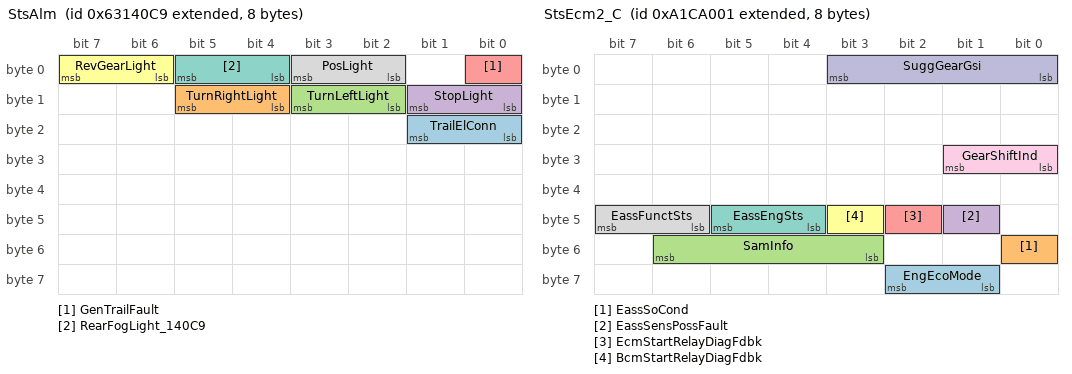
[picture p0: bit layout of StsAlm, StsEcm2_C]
BO_ 2251374793 StsAlm: 8 ALM
 SG_ TrailElConn : 16|2@1+ (1,0) [0|3] ""  PCM,NODE_40
 SG_ TurnRightLight : 12|2@1+ (1,0) [0|3] ""  PCM,NODE_40
 SG_ TurnLeftLight : 10|2@1+ (1,0) [0|3] ""  PCM,NODE_40
 SG_ StopLight : 8|2@1+ (1,0) [0|3] ""  PCM,NODE_40
 SG_ GenTrailFault : 0|1@0+ (1,0) [0|1] ""  PCM,NODE_40
 SG_ RevGearLight : 6|2@1+ (1,0) [0|3] ""  PCM,NODE_40
 SG_ RearFogLight_140C9 : 4|2@1+ (1,0) [0|3] ""  PCM,NODE_40
 SG_ PosLight : 2|2@1+ (1,0) [0|3] ""  PCM,NODE_40

BO_ 2317131777 StsEcm2_C: 8 NODE_1
 SG_ EngEcoMode : 58|2@0+ (1,0) [0|3] ""  PCM,AEBS
 SG_ EassSoCond : 48|1@0+ (1,0) [0|1] ""  PCM,AEBS
 SG_ SamInfo : 54|4@0+ (1,0) [0|15] ""  PCM,AEBS
 SG_ EassSensPossFault : 41|1@0+ (1,0) [0|1] ""  PCM,AEBS
 SG_ EcmStartRelayDiagFdbk : 42|1@0+ (1,0) [0|1] ""  PCM,AEBS
 SG_ BcmStartRelayDiagFdbk : 43|1@0+ (1,0) [0|1] ""  PCM,AEBS
 SG_ EassEngSts : 45|2@0+ (1,0) [0|3] ""  PCM,AEBS
 SG_ EassFunctSts : 47|2@0+ (1,0) [0|3] ""  PCM,AEBS
 SG_ GearShiftInd : 25|2@0+ (1,0) [0|3] ""  PCM,AEBS
 SG_ SuggGearGsi : 3|4@0+ (1,0) [0|15] ""  PCM,AEBS

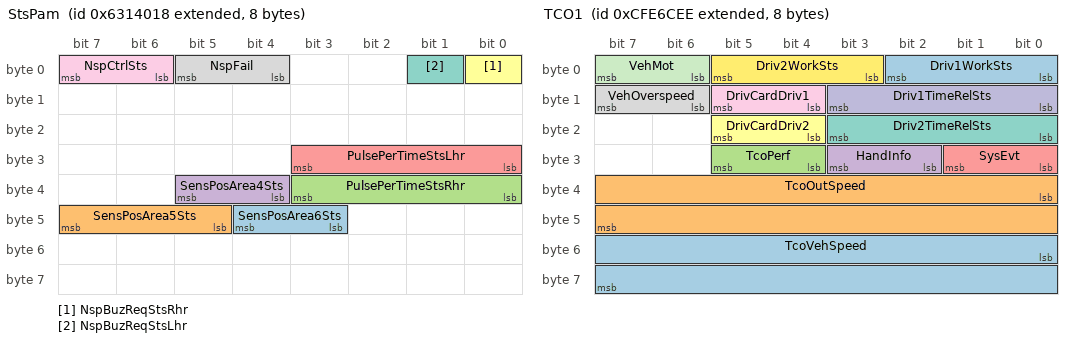
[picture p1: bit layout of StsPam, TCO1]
BO_ 2251374616 StsPam: 8 NODE_18
 SG_ SensPosArea6Sts : 44|2@0+ (1,0) [0|3] ""  PCM,NODE_40
 SG_ SensPosArea5Sts : 47|3@0+ (1,0) [0|7] ""  PCM,NODE_40
 SG_ PulsePerTimeStsRhr : 35|4@0+ (25,0) [0|375] "ms"  PCM,NODE_40
 SG_ SensPosArea4Sts : 37|2@0+ (1,0) [0|3] ""  PCM,NODE_40
 SG_ PulsePerTimeStsLhr : 27|4@0+ (25,0) [0|375] "ms"  PCM,NODE_40
 SG_ NspBuzReqStsRhr : 0|1@0+ (1,0) [0|1] ""  PCM,NODE_40
 SG_ NspBuzReqStsLhr : 1|1@0+ (1,0) [0|1] ""  PCM,NODE_40
 SG_ NspFail : 5|2@0+ (1,0) [0|3] ""  PCM,NODE_40
 SG_ NspCtrlSts : 7|2@0+ (1,0) [0|3] ""  PCM,NODE_40

BO_ 2348885874 TC1_72_27: 8 EM_PTO
 SG_ TransmMode8 : 62|2@1+ (1,0) [0|3] ""  PCM,VCM
 SG_ TransmMode7 : 60|2@1+ (1,0) [0|3] ""  PCM,VCM
 SG_ TransmMode6 : 58|2@1+ (1,0) [0|3] ""  PCM,VCM
 SG_ TransmMode5 : 56|2@1+ (1,0) [0|3] ""  PCM,VCM
 SG_ TransmShiftSelDisModeSw : 54|2@1+ (1,0) [0|3] ""  PCM,VCM
 SG_ TransmReqLaunchGear : 50|4@1+ (1,0) [0|15] ""  PCM,VCM
 SG_ TransmMode4 : 46|2@1+ (1,0) [0|3] ""  PCM,VCM
 SG_ TransmMode3 : 44|2@1+ (1,0) [0|3] ""  PCM,VCM
 SG_ TransmMode2 : 42|2@1+ (1,0) [0|3] ""  PCM,VCM
 SG_ TransmMode1 : 40|2@1+ (1,0) [0|3] ""  PCM,VCM
 SG_ DisengDiffLckReqCentRear : 36|2@1+ (1,0) [0|3] ""  PCM,VCM
 SG_ DisengDiffLckReqCentFront : 34|2@1+ (1,0) [0|3] ""  PCM,VCM
 SG_ DisengDiffLckReqCent : 32|2@1+ (1,0) [0|3] ""  PCM,VCM
 SG_ DisengDiffLckReqRa2 : 30|2@1+ (1,0) [0|3] ""  PCM,VCM
 SG_ DisengDiffLckReqRa1 : 28|2@1+ (1,0) [0|3] ""  PCM,VCM
 SG_ DisengDiffLckReqFa2 : 26|2@1+ (1,0) [0|3] ""  PCM,VCM
 SG_ DisengDiffLckReqFa1 : 24|2@1+ (1,0) [0|3] ""  PCM,VCM
 SG_ TransmReqGear : 16|8@1+ (1,-125) [-125|125] "gear value"  PCM,VCM
 SG_ ReqPcCltSlip : 8|8@1+ (0.4,0) [0|100] "%"  PCM,VCM
 SG_ TransmRevGearShiftInhReq : 6|2@1+ (1,0) [0|3] ""  PCM,VCM
 SG_ DisengDrvlReq : 4|2@1+ (1,0) [0|3] ""  PCM,VCM
 SG_ TransmTrqConvLckReq : 2|2@1+ (1,0) [0|3] ""  PCM,VCM
 SG_ TransmGearShiftInhReq : 0|2@1+ (1,0) [0|3] ""  PCM,VCM

BO_ 2566840835 TCFG: 20 AI_G5_TCM
 SG_ TransmGr9 : 144|16@1+ (0.001,0) [0|64.255] ""  PCM
 SG_ TransmGr8 : 128|16@1+ (0.001,0) [0|64.255] ""  PCM
 SG_ TransmGr7 : 112|16@1+ (0.001,0) [0|64.255] ""  PCM
 SG_ TransmGr6 : 96|16@1+ (0.001,0) [0|64.255] ""  PCM
 SG_ TransmGr5 : 80|16@1+ (0.001,0) [0|64.255] ""  PCM
 SG_ TransmGr4 : 64|16@1+ (0.001,0) [0|64.255] ""  PCM
 SG_ TransmGr3 : 48|16@1+ (0.001,0) [0|64.255] ""  PCM
 SG_ TransmGr2 : 32|16@1+ (0.001,0) [0|64.255] ""  PCM
 SG_ TransmGr1 : 16|16@1+ (0.001,0) [0|64.255] ""  PCM
 SG_ NumOfFwGrs : 8|8@1+ (1,0) [0|250] "gear value"  PCM
 SG_ NumOfRevGrs : 0|8@1+ (1,0) [0|250] "gear value"  PCM

BO_ 2566750979 TCI_03: 8 AI_G5_TCM
 SG_ TcSts : 0|3@1+ (1,0) [0|7] ""  PCM

BO_ 2566751205 TCI_E5: 8 BC2
 SG_ TcSts_FD83E5 : 0|3@1+ (1,0) [0|7] ""  PCM

BO_ 2365484270 TCO1: 8 DTCO
 SG_ TcoVehSpeed : 48|16@1+ (0.00390625,0) [0|250.996] "km/h"  PCM
 SG_ TcoOutSpeed : 32|16@1+ (0.125,0) [0|8031.875] "rpm"  PCM
 SG_ TcoPerf : 28|2@1+ (1,0) [0|3] ""  PCM
 SG_ HandInfo : 26|2@1+ (1,0) [0|3] ""  PCM
 SG_ SysEvt : 24|2@1+ (1,0) [0|3] ""  PCM
 SG_ DrivCardDriv2 : 20|2@1+ (1,0) [0|3] ""  PCM
 SG_ Driv2TimeRelSts : 16|4@1+ (1,0) [0|15] ""  PCM
 SG_ VehOverspeed : 14|2@1+ (1,0) [0|3] ""  PCM
 SG_ DrivCardDriv1 : 12|2@1+ (1,0) [0|3] ""  PCM
 SG_ Driv1TimeRelSts : 8|4@1+ (1,0) [0|15] ""  PCM
 SG_ VehMot : 6|2@1+ (1,0) [0|3] ""  PCM
 SG_ Driv2WorkSts : 3|3@1+ (1,0) [0|7] ""  PCM
 SG_ Driv1WorkSts : 0|3@1+ (1,0) [0|7] ""  PCM

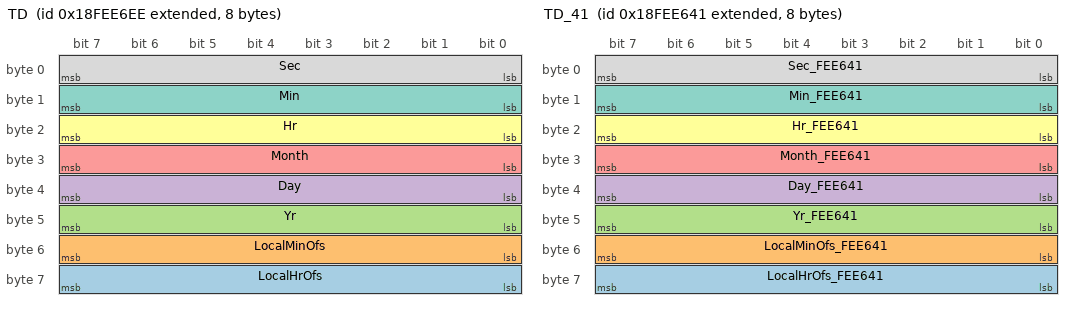
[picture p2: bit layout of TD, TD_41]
BO_ 2566842094 TD: 8 DTCO
 SG_ LocalHrOfs : 56|8@1+ (1,-125) [-125|125] "h"  PCM
 SG_ LocalMinOfs : 48|8@1+ (1,-125) [-125|125] "min"  PCM
 SG_ Yr : 40|8@1+ (1,1985) [1985|2235] "year"  PCM
 SG_ Day : 32|8@1+ (0.25,0) [0|62.5] "day"  PCM
 SG_ Month : 24|8@1+ (1,0) [0|250] "month"  PCM
 SG_ Hr : 16|8@1+ (1,0) [0|250] "h"  PCM
 SG_ Min : 8|8@1+ (1,0) [0|250] "min"  PCM
 SG_ Sec : 0|8@1+ (0.25,0) [0|62.5] "s"  PCM

BO_ 2566841921 TD_41: 8 NIS_RDR
 SG_ LocalHrOfs_FEE641 : 56|8@1+ (1,-125) [-125|125] "h"  PCM
 SG_ LocalMinOfs_FEE641 : 48|8@1+ (1,-125) [-125|125] "min"  PCM
 SG_ Yr_FEE641 : 40|8@1+ (1,1985) [1985|2235] "year"  PCM
 SG_ Day_FEE641 : 32|8@1+ (0.25,0) [0|62.5] "day"  PCM
 SG_ Month_FEE641 : 24|8@1+ (1,0) [0|250] "month"  PCM
 SG_ Hr_FEE641 : 16|8@1+ (1,0) [0|250] "h"  PCM
 SG_ Min_FEE641 : 8|8@1+ (1,0) [0|250] "min"  PCM
 SG_ Sec_FEE641 : 0|8@1+ (0.25,0) [0|62.5] "s"  PCM

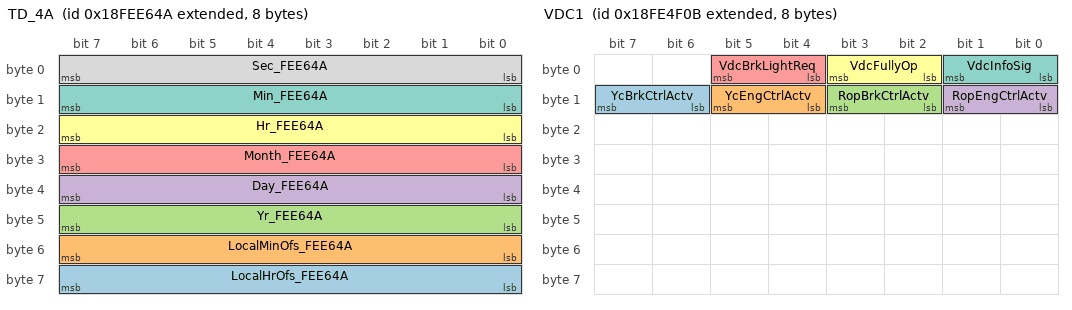
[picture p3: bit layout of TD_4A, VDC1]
BO_ 2566841930 TD_4A: 8 PCM
 SG_ LocalHrOfs_FEE64A : 56|8@1+ (1,-125) [-125|125] "h" Vector__XXX
 SG_ LocalMinOfs_FEE64A : 48|8@1+ (1,-125) [-125|125] "min" Vector__XXX
 SG_ Yr_FEE64A : 40|8@1+ (1,1985) [1985|2235] "year" Vector__XXX
 SG_ Day_FEE64A : 32|8@1+ (0.25,0) [0|62.5] "day" Vector__XXX
 SG_ Month_FEE64A : 24|8@1+ (1,0) [0|250] "month" Vector__XXX
 SG_ Hr_FEE64A : 16|8@1+ (1,0) [0|250] "h" Vector__XXX
 SG_ Min_FEE64A : 8|8@1+ (1,0) [0|250] "min" Vector__XXX
 SG_ Sec_FEE64A : 0|8@1+ (0.25,0) [0|62.5] "s" Vector__XXX

BO_ 2566764851 TPRI: 8 OptiTire
 SG_ RefTirePrs : 8|8@1+ (8,0) [0|2000] "kPa"  PCM
 SG_ TireLoc : 0|8@1+ (1,0) [0|255] ""  PCM

BO_ 2566846467 TRF1: 8 AI_G5_TCM
 SG_ TransmOilTemp1 : 32|16@1+ (0.03125,-273) [-273|1734.96875] "�C"  PCM

BO_ 2566755587 TRF2: 8 AI_G5_TCM
 SG_ TransmTrqConvOilOutTemp : 8|16@1+ (0.03125,-273) [-273|1734.96875] "�C"  PCM

BO_ 2566803211 VDC1: 8 BSM
 SG_ YcBrkCtrlActv : 14|2@1+ (1,0) [0|3] ""  PCM
 SG_ YcEngCtrlActv : 12|2@1+ (1,0) [0|3] ""  PCM
 SG_ RopBrkCtrlActv : 10|2@1+ (1,0) [0|3] ""  PCM
 SG_ RopEngCtrlActv : 8|2@1+ (1,0) [0|3] ""  PCM
 SG_ VdcBrkLightReq : 4|2@1+ (1,0) [0|3] ""  PCM
 SG_ VdcFullyOp : 2|2@1+ (1,0) [0|3] ""  PCM
 SG_ VdcInfoSig : 0|2@1+ (1,0) [0|3] ""  PCM

BO_ 2566832622 VDHR: 8 DTCO
 SG_ TripDistHr : 32|32@1+ (5,0) [0|21055406075] "m"  PCM
 SG_ TotVehDistHr : 0|32@1+ (5,0) [0|21055406075] "m"  PCM

BO_ 2566832407 VDHR_17: 8 ICC
 SG_ TotVehDistHr_FEC117 : 0|32@1+ (5,0) [0|21055406075] "m"  PCM

BO_ 2566842433 VDS_41: 8 NIS_RDR
 SG_ Altitude : 48|16@1+ (0.125,-2500) [-2500|5531.875] "m"  PCM
 SG_ Pitch : 32|16@1+ (0.0078125,-200) [-200|301.99] "deg"  PCM
 SG_ NavBasedVehSpeed : 16|16@1+ (0.00390625,0) [0|250.996] "km/h"  PCM
 SG_ CompassBear : 0|16@1+ (0.0078125,0) [0|501.99] "deg"  PCM

BO_ 2566842442 VDS_4A: 8 PCM
 SG_ Altitude_FEE84A : 48|16@1+ (0.125,-2500) [-2500|5531.875] "m" Vector__XXX
 SG_ Pitch_FEE84A : 32|16@1+ (0.0078125,-200) [-200|301.99] "deg" Vector__XXX
 SG_ NavBasedVehSpeed_FEE84A : 16|16@1+ (0.00390625,0) [0|250.996] "km/h" Vector__XXX
 SG_ CompassBear_FEE84A : 0|16@1+ (0.0078125,0) [0|501.99] "deg" Vector__XXX

BO_ 2566752586 VDS2_4A: 8 PCM
 SG_ VehRoll : 0|16@1+ (0.0078125,-200) [-200|301.99] "deg" Vector__XXX

BO_ 2566846208 VEP1_00: 8 ECM
 SG_ KeyBatPot : 48|16@1+ (0.05,0) [0|3212.75] "V"  PCM
 SG_ BatPot_PwrIn1 : 32|16@1+ (0.05,0) [0|3212.75] "V"  PCM

BO_ 2566846241 VEP1_21: 8 BCM
 SG_ KeyBatPot_FEF721 : 48|16@1+ (0.05,0) [0|3212.75] "V"  PCM
 SG_ BatPot_PwrIn1_FEF721 : 32|16@1+ (0.05,0) [0|3212.75] "V"  PCM

BO_ 2566843392 VI_00: 18 ECM
 SG_ Vin : 0|8@1+ (1,0) [0|255] "ASCII"  PCM

BO_ 2566843466 VI_4A: 18 PCM
 SG_ Vin_FEEC4A : 0|8@1+ (1,0) [0|255] "ASCII" Vector__XXX

BO_ 2566843630 VI_EE: 18 DTCO
 SG_ Vin_FEECEE : 0|8@1+ (1,0) [0|255] "ASCII"  PCM

BO_ 2566845249 VP1_41: 8 NIS_RDR
 SG_ Long_FEF341 : 32|32@1+ (1E-007,-210) [-210|211.1081215] "deg"  PCM
 SG_ Lat_FEF341 : 0|32@1+ (1E-007,-210) [-210|211.1081215] "deg"  PCM

BO_ 2566845258 VP1_4A: 8 PCM
 SG_ Long_FEF34A : 32|32@1+ (1E-007,-210) [-210|211.1081215] "deg" Vector__XXX
 SG_ Lat_FEF34A : 0|32@1+ (1E-007,-210) [-210|211.1081215] "deg" Vector__XXX

BO_ 2566845422 VP1_EE: 8 DTCO
 SG_ Long_FEF3EE : 32|32@1+ (1E-007,-210) [-210|211.1081215] "deg"  PCM
 SG_ Lat_FEF3EE : 0|32@1+ (1E-007,-210) [-210|211.1081215] "deg"  PCM

BO_ 2566649418 VP2_4A: 8 PCM
 SG_ TimeDilutionOfPrec : 32|8@1+ (0.1,0) [0|25] "" Vector__XXX
 SG_ PosDilutionOfPrec : 24|8@1+ (0.1,0) [0|25] "" Vector__XXX
 SG_ VertDilutionOfPrec : 16|8@1+ (0.1,0) [0|25] "" Vector__XXX
 SG_ HorDilutionOfPrec : 8|8@1+ (0.1,0) [0|25] "" Vector__XXX
 SG_ TotNumOfSatsInView : 0|8@1+ (1,0) [0|250] "count" Vector__XXX

BO_ 2566842606 VDS_EE: 8 DTCO
 SG_ Altitude_FEE8EE : 48|16@1+ (0.125,-2500) [-2500|5531.875] "m"  PCM
 SG_ NavBasedVehSpeed_FEE8EE : 16|16@1+ (0.00390625,0) [0|250.996] "km/h"  PCM
 SG_ CompassBear_FEE8EE : 0|16@1+ (0.0078125,0) [0|501.99] "deg"  PCM

BO_ 2348875082 PB_DC_7_4A: 8 PCM
 SG_ StopTime : 32|32@1+ (1,0) [0|65000000] "ms"  NODE_FD
 SG_ PTOTime : 0|32@1+ (1,0) [0|65000000] "ms"  NODE_FD

BO_ 2348874826 PB_DC_6_4A: 8 PCM
 SG_ DrivingTime : 32|32@1+ (1,0) [0|65000000] "ms"  RADAR_ACC
 SG_ RegenerationTime : 0|32@1+ (1,0) [0|65000000] "ms"  RADAR_ACC

BO_ 2348874570 PB_DC_5_4A: 8 PCM
 SG_ RegenerationDistance : 18|18@1+ (5,0) [0|1310000] "m"  NODE_FB
 SG_ EcoSwitchDistance : 0|18@1+ (5,0) [0|1310000] "m"  NODE_FB

BO_ 2348874314 PB_DC_4_4A: 8 PCM
 SG_ EcoSwitchTime : 24|32@1+ (1,0) [0|65000000] "ms"  TesterMh
 SG_ RecovEnergySumAbs : 0|24@1+ (0.1,0) [0|1644953.5] "kWh"  TesterMh

BO_ 2348875594 PB_DC_3_4A: 8 PCM
 SG_ TracEnergyDrivingSumAbs : 40|24@1+ (0.1,0) [0|1644953.5] "kWh" Vector__XXX
 SG_ EnergyConsPTOSumAbs : 16|24@1+ (0.1,0) [0|1644953.5] "kWh" Vector__XXX
 SG_ EnergyConsAvg : 0|16@1+ (0.001953125,0) [0|125.498046875] "km/kWh" Vector__XXX

BO_ 2348871498 PB_DC_2_4A: 8 PCM
 SG_ BatTempAvg : 40|8@1+ (1,-40) [-40|215] "�C"  NODE_EF
 SG_ AmbTempMax : 24|16@1+ (0.03125,-273) [-273|1734.96875] "�C"  NODE_EF
 SG_ AmbTempAvg : 8|16@1+ (0.03125,-273) [-273|1734.96875] "�C"  NODE_EF
 SG_ BatTempMax : 0|8@1+ (1,-40) [-40|210] "�C"  NODE_EF

BO_ 2348871242 PB_DC_1_4A: 8 PCM
 SG_ StopNumbersOccurrences : 34|10@1+ (1,0) [0|1023] ""  DTCO
 SG_ DrivingDistance : 16|18@1+ (5,0) [0|1310000] "m"  DTCO
 SG_ WhBasedVehSpeedAvg : 0|16@1+ (0.00390625,0) [0|250.996] "km/h"  DTCO

BO_ 2561142090 DSE_DRIVER_STOP: 8 PCM
 SG_ Driver_Stop : 0|2@1+ (1,0) [0|2] ""  NODE_ED

BO_ 2561141834 DSE_FUEL_CONSP: 8 PCM
 SG_ FuelConsumptionEstimatedDiesel : 20|10@1+ (0.1,-1) [-1|101.3] "L/100km"  MCDS
 SG_ FuelConsumptionGas : 10|10@1+ (0.1,-1) [-1|101.3] "Kg/100km"  MCDS
 SG_ FuelConsumptionDiesel : 0|10@1+ (0.1,-1) [-1|101.3] "L/100km"  MCDS

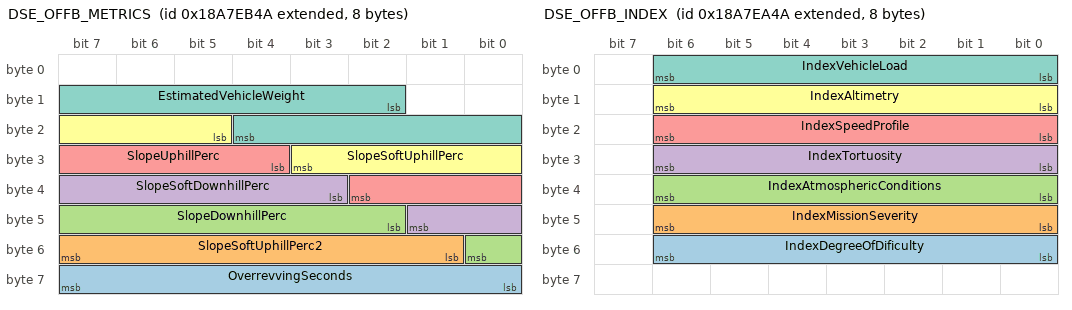
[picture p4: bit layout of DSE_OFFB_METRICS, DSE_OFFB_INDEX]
BO_ 2561141578 DSE_OFFB_METRICS: 8 PCM
 SG_ OverrevvingSeconds : 56|8@1+ (1,-1) [-1|254] "s"  NODE_EB
 SG_ SlopeSoftUphillPerc2 : 49|7@1+ (1,-1) [-1|126] "Index"  NODE_EB
 SG_ SlopeDownhillPerc : 42|7@1+ (1,-1) [-1|126] "Index"  NODE_EB
 SG_ SlopeSoftDownhillPerc : 35|7@1+ (1,-1) [-1|126] "Index"  NODE_EB
 SG_ SlopeUphillPerc : 28|7@1+ (1,-1) [-1|126] "Index"  NODE_EB
 SG_ SlopeSoftUphillPerc : 21|7@1+ (1,-1) [-1|126] "Index"  NODE_EB
 SG_ EstimatedVehicleWeight : 10|11@1+ (50,-1) [-1|102349] "kg"  NODE_EB

BO_ 2561141322 DSE_OFFB_INDEX: 8 PCM
 SG_ IndexDegreeOfDificulty : 48|7@1+ (1,-1) [-1|126] "Index"  MCSL
 SG_ IndexMissionSeverity : 40|7@1+ (1,-1) [-1|126] "Index"  MCSL
 SG_ IndexAtmosphericConditions : 32|7@1+ (1,-1) [-1|126] "Index"  MCSL
 SG_ IndexTortuosity : 24|7@1+ (1,-1) [-1|126] "Index"  MCSL
 SG_ IndexSpeedProfile : 16|7@1+ (1,-1) [-1|126] "Index"  MCSL
 SG_ IndexAltimetry : 8|7@1+ (1,-1) [-1|126] "Index"  MCSL
 SG_ IndexVehicleLoad : 0|7@1+ (1,-1) [-1|126] "Index"  MCSL

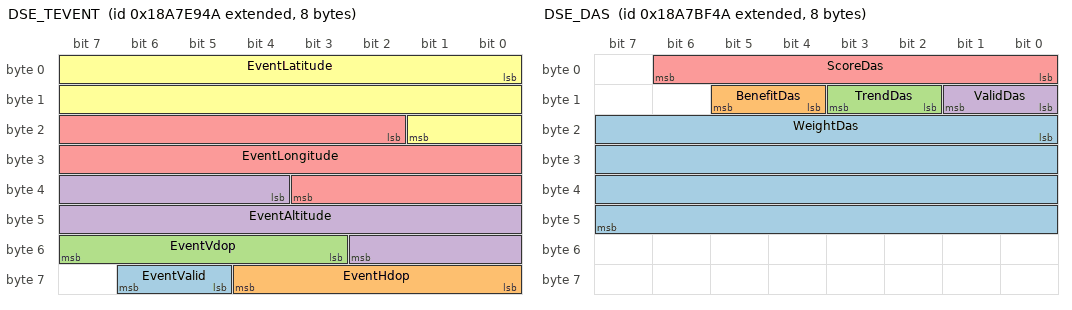
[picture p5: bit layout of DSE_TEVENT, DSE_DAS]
BO_ 2561141066 DSE_TEVENT: 8 PCM
 SG_ EventValid : 61|2@1+ (1,0) [0|3] ""  Mirror
 SG_ EventHdop : 56|5@1+ (1,0) [0|25] ""  Mirror
 SG_ EventVdop : 51|5@1+ (1,0) [0|25] ""  Mirror
 SG_ EventAltitude : 36|15@1+ (0.2,-500) [-500|6053.4] ""  Mirror
 SG_ EventLongitude : 18|18@1+ (0.0015,0) [-196.608|196.6065] ""  Mirror
 SG_ EventLatitude : 0|18@1+ (0.001,0) [-131.072|131.071] ""  Mirror

BO_ 2561140810 DSE_EVAL: 8 PCM
 SG_ EvaluatedSamplesTrip : 32|32@1+ (1,-1) [-1|4294967294] ""  NODE_E8
 SG_ EvaluatedMetersTrip : 0|32@1+ (1,-1) [-1|4294967294] "m"  NODE_E8

BO_ 2561140554 DSE_DAS_DBG: 8 PCM
 SG_ EventDas : 16|2@1+ (1,0) [0|3] ""  NODE_E7
 SG_ EvaluatedSamplesDas : 0|16@1+ (1,-1) [-1|65534] ""  NODE_E7

BO_ 2561130314 DSE_DAS: 8 PCM
 SG_ WeightDas : 16|32@1+ (1,-1) [-1|4294967294] ""  NODE_BF
 SG_ BenefitDas : 12|2@1+ (1,0) [0|0] ""  NODE_BF
 SG_ TrendDas : 10|2@1+ (1,-1) [-1|2] ""  NODE_BF
 SG_ ValidDas : 8|2@1+ (1,0) [0|0] ""  NODE_BF
 SG_ ScoreDas : 0|7@1+ (1,-1) [-1|126] "Index"  NODE_BF

BO_ 2561132874 DSE_HRBK_DBG: 8 PCM
 SG_ MaxDecelerationHarshBraking : 18|6@1+ (1,0) [0|63] "kmh/s"  ALM
 SG_ EventHarshBraking : 16|2@1+ (1,0) [0|3] ""  ALM
 SG_ EvaluatedMetersHarshBraking : 0|16@1+ (1,-1) [-1|65534] "m"  ALM

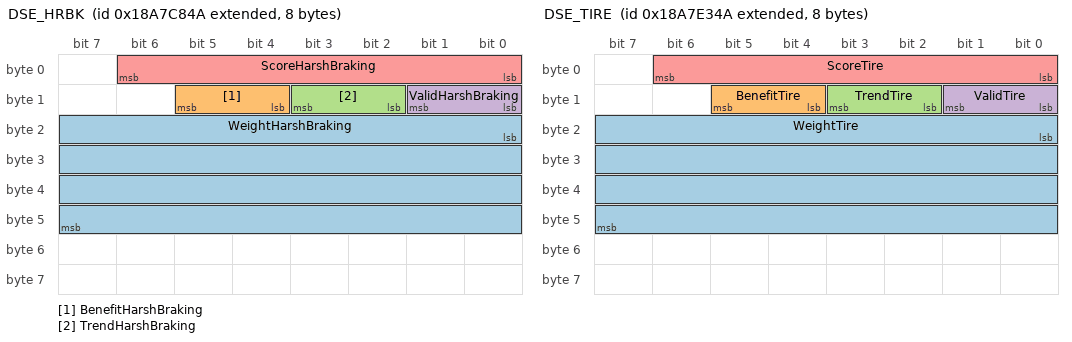
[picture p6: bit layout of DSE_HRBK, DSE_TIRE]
BO_ 2561132618 DSE_HRBK: 8 PCM
 SG_ WeightHarshBraking : 16|32@1+ (1,-1) [-1|4294967294] ""  NODE_C8
 SG_ BenefitHarshBraking : 12|2@1+ (1,0) [0|0] ""  NODE_C8
 SG_ TrendHarshBraking : 10|2@1+ (1,-1) [-1|2] ""  NODE_C8
 SG_ ValidHarshBraking : 8|2@1+ (1,0) [0|0] ""  NODE_C8
 SG_ ScoreHarshBraking : 0|7@1+ (1,-1) [-1|126] "Index"  NODE_C8

BO_ 2561139786 DSE_TIRE_DBG: 8 PCM
 SG_ EventTireSaving : 16|2@1+ (1,-1) [-1|2] ""  SAS
 SG_ EvaluatedSamplesTire : 0|16@1+ (1,-1) [-1|65534] ""  SAS

BO_ 2561139530 DSE_TIRE: 8 PCM
 SG_ WeightTire : 16|32@1+ (1,-1) [-1|4294967294] ""  NODE_E3
 SG_ BenefitTire : 12|2@1+ (1,0) [0|0] ""  NODE_E3
 SG_ TrendTire : 10|2@1+ (1,-1) [-1|2] ""  NODE_E3
 SG_ ValidTire : 8|2@1+ (1,0) [0|0] ""  NODE_E3
 SG_ ScoreTire : 0|7@1+ (1,-1) [-1|126] "Index"  NODE_E3

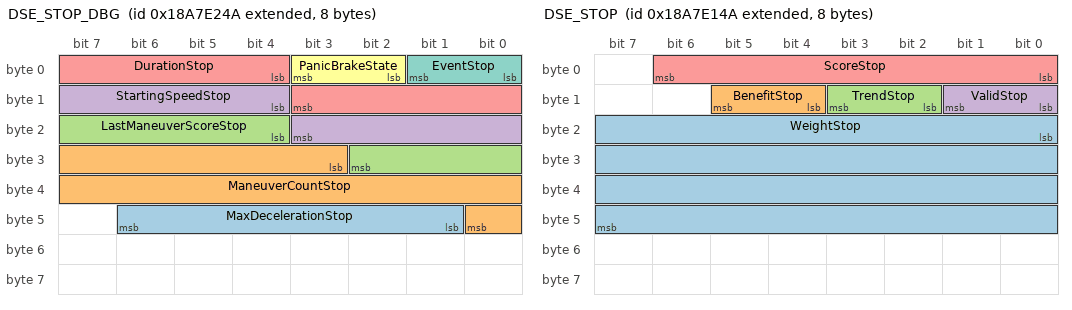
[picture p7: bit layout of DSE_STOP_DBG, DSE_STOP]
BO_ 2561139274 DSE_STOP_DBG: 8 PCM
 SG_ MaxDecelerationStop : 41|6@1+ (1,0) [0|63] "kmh/s"  NODE_E2
 SG_ ManeuverCountStop : 27|14@1+ (1,-1) [-1|16382] "Count"  NODE_E2
 SG_ LastManeuverScoreStop : 20|7@1+ (1,-1) [-1|126] "Index"  NODE_E2
 SG_ StartingSpeedStop : 12|8@1+ (0.5,0) [0|127.5] "km/h"  NODE_E2
 SG_ DurationStop : 4|8@1+ (1,-1) [-1|254] "s"  NODE_E2
 SG_ PanicBrakeState : 2|2@1+ (1,0) [0|3] ""  NODE_E2
 SG_ EventStop : 0|2@1+ (1,0) [0|3] ""  NODE_E2

BO_ 2561139018 DSE_STOP: 8 PCM
 SG_ WeightStop : 16|32@1+ (1,-1) [-1|4294967294] ""  NODE_E1
 SG_ BenefitStop : 12|2@1+ (1,0) [0|0] ""  NODE_E1
 SG_ TrendStop : 10|2@1+ (1,-1) [-1|2] ""  NODE_E1
 SG_ ValidStop : 8|2@1+ (1,0) [0|0] ""  NODE_E1
 SG_ ScoreStop : 0|7@1+ (1,-1) [-1|126] "Index"  NODE_E1

BO_ 2561138762 DSE_STCNT_DBG: 8 PCM
 SG_ EventStabilityControl : 16|2@1+ (1,0) [0|3] ""  NODE_E0
 SG_ EvaluatedMetersStabilityControl : 0|16@1+ (1,-1) [-1|65534] "m"  NODE_E0

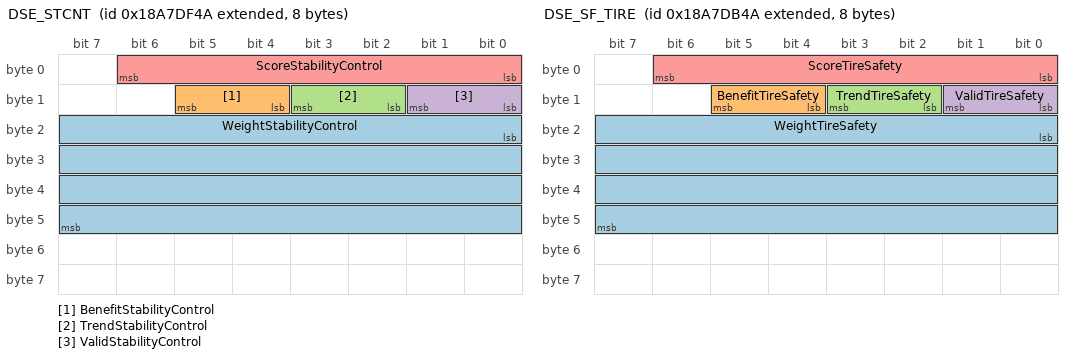
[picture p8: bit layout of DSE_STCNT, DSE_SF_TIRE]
BO_ 2561138506 DSE_STCNT: 8 PCM
 SG_ WeightStabilityControl : 16|32@1+ (1,-1) [-1|4294967294] ""  NODE_DF
 SG_ BenefitStabilityControl : 12|2@1+ (1,0) [0|0] ""  NODE_DF
 SG_ TrendStabilityControl : 10|2@1+ (1,-1) [-1|2] ""  NODE_DF
 SG_ ValidStabilityControl : 8|2@1+ (1,0) [0|0] ""  NODE_DF
 SG_ ScoreStabilityControl : 0|7@1+ (1,-1) [-1|126] "Index"  NODE_DF

BO_ 2561138250 DSE_STATUS: 8 PCM
 SG_ TripEndReason : 8|3@1+ (1,0) [0|7] ""  NODE_DE
 SG_ TripActive : 4|2@1+ (1,0) [0|0] ""  NODE_DE
 SG_ TripEnded_A7DE4A : 2|2@1+ (1,0) [0|0] ""  NODE_DE
 SG_ TripStarted_A7DE4A : 0|2@1+ (1,0) [0|0] ""  NODE_DE

BO_ 2561137994 DSE_START: 8 PCM
 SG_ TimeStampTripStart : 32|32@1+ (1,946684800) [946684800|5241652095] "Count"  NODE_DD
 SG_ OdometerTripStart : 0|32@1+ (5,-1) [-1|21474836474] "m"  NODE_DD

BO_ 2561137738 DSE_SF_TIRE_DBG: 8 PCM
 SG_ EventTireSafety : 16|2@1+ (1,0) [0|3] ""  NODE_DC
 SG_ EvaluatedMetersTireSafety : 0|16@1+ (1,-1) [-1|65534] "m"  NODE_DC

BO_ 2561137482 DSE_SF_TIRE: 8 PCM
 SG_ WeightTireSafety : 16|32@1+ (1,-1) [-1|4294967294] ""  NODE_DB
 SG_ BenefitTireSafety : 12|2@1+ (1,0) [0|0] ""  NODE_DB
 SG_ TrendTireSafety : 10|2@1+ (1,-1) [-1|2] ""  NODE_DB
 SG_ ValidTireSafety : 8|2@1+ (1,0) [0|0] ""  NODE_DB
 SG_ ScoreTireSafety : 0|7@1+ (1,-1) [-1|126] "Index"  NODE_DB

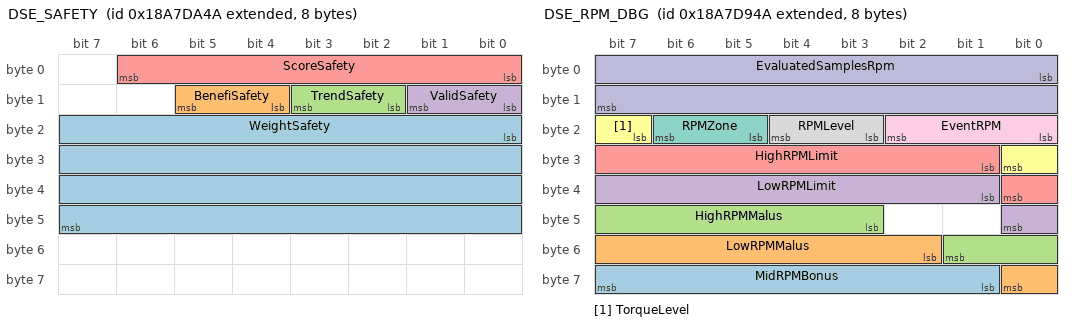
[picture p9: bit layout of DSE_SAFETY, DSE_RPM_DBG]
BO_ 2561137226 DSE_SAFETY: 8 PCM
 SG_ WeightSafety : 16|32@1+ (1,-1) [-1|4294967294] ""  NODE_DA
 SG_ BenefiSafety : 12|2@1+ (1,0) [0|0] ""  NODE_DA
 SG_ TrendSafety : 10|2@1+ (1,-1) [-1|2] ""  NODE_DA
 SG_ ValidSafety : 8|2@1+ (1,0) [0|0] ""  NODE_DA
 SG_ ScoreSafety : 0|7@1+ (1,-1) [-1|126] "Index"  NODE_DA

BO_ 2561136970 DSE_RPM_DBG: 8 PCM
 SG_ MidRPMBonus : 57|7@1+ (1,-1) [-1|126] "Index"  NODE_D9
 SG_ LowRPMMalus : 50|7@1+ (1,-126) [-126|1] "Index"  NODE_D9
 SG_ HighRPMMalus : 43|7@1+ (1,-126) [-126|1] "Index"  NODE_D9
 SG_ LowRPMLimit : 33|8@1+ (10,0) [0|2550] "rpm"  NODE_D9
 SG_ HighRPMLimit : 25|8@1+ (10,1000) [1000|3550] "rpm"  NODE_D9
 SG_ TorqueLevel : 23|2@1+ (1,0) [0|3] ""  NODE_D9
 SG_ RPMZone : 21|2@1+ (1,0) [0|3] ""  NODE_D9
 SG_ RPMLevel : 19|2@1+ (1,0) [0|3] ""  NODE_D9
 SG_ EventRPM : 16|3@1+ (1,0) [0|7] ""  NODE_D9
 SG_ EvaluatedSamplesRpm : 0|16@1+ (1,-1) [-1|65534] ""  NODE_D9

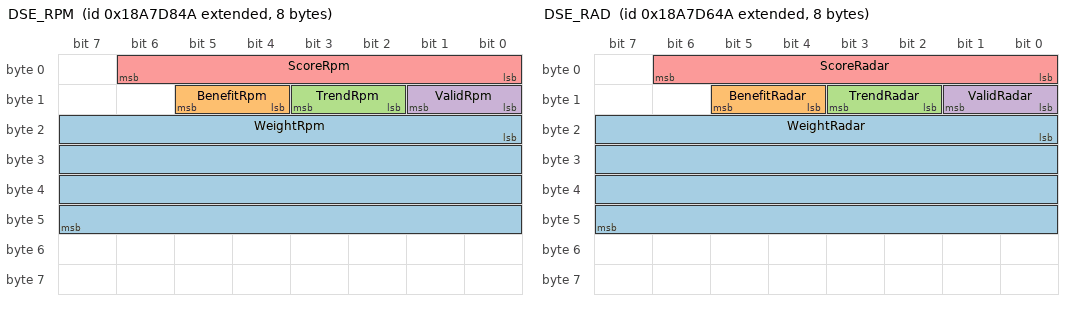
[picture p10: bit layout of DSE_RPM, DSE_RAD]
BO_ 2561136714 DSE_RPM: 8 PCM
 SG_ WeightRpm : 16|32@1+ (1,-1) [-1|4294967294] ""  NODE_D8
 SG_ BenefitRpm : 12|2@1+ (1,0) [0|0] ""  NODE_D8
 SG_ TrendRpm : 10|2@1+ (1,-1) [-1|2] ""  NODE_D8
 SG_ ValidRpm : 8|2@1+ (1,0) [0|0] ""  NODE_D8
 SG_ ScoreRpm : 0|7@1+ (1,-1) [-1|126] "Index"  NODE_D8

BO_ 2561136458 DSE_RAD_DBG: 8 PCM
 SG_ EventRadar : 16|2@1+ (1,0) [0|3] ""  NODE_D7
 SG_ EvaluatedSamplesRadar : 0|16@1+ (1,-1) [-1|65534] ""  NODE_D7

BO_ 2561136202 DSE_RAD: 8 PCM
 SG_ WeightRadar : 16|32@1+ (1,-1) [-1|4294967294] ""  NODE_D6
 SG_ BenefitRadar : 12|2@1+ (1,0) [0|0] ""  NODE_D6
 SG_ TrendRadar : 10|2@1+ (1,-1) [-1|2] ""  NODE_D6
 SG_ ValidRadar : 8|2@1+ (1,0) [0|0] ""  NODE_D6
 SG_ ScoreRadar : 0|7@1+ (1,-1) [-1|126] "Index"  NODE_D6

BO_ 2561135946 DSE_PECC_DBG: 8 PCM
 SG_ EventPecc : 16|2@1+ (1,0) [0|3] ""  NODE_D5
 SG_ EvaluatedSamplesPecc : 0|16@1+ (1,-1) [-1|65534] ""  NODE_D5

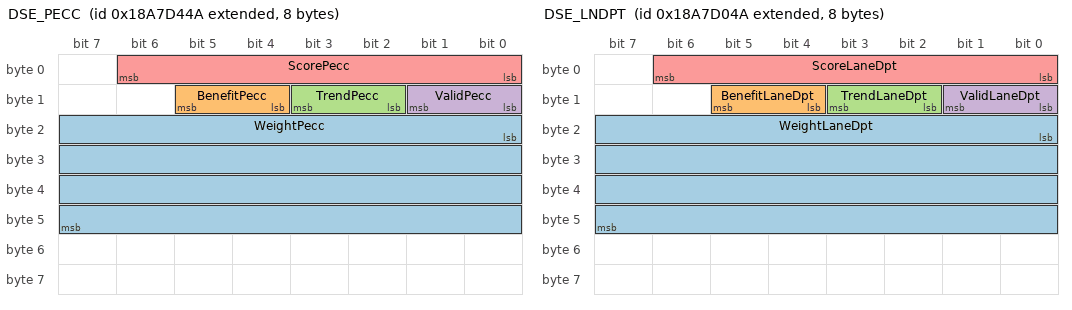
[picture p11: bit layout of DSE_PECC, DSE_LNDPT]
BO_ 2561135690 DSE_PECC: 8 PCM
 SG_ WeightPecc : 16|32@1+ (1,-1) [-1|4294967294] ""  NODE_D4
 SG_ BenefitPecc : 12|2@1+ (1,0) [0|0] ""  NODE_D4
 SG_ TrendPecc : 10|2@1+ (1,-1) [-1|2] ""  NODE_D4
 SG_ ValidPecc : 8|2@1+ (1,0) [0|0] ""  NODE_D4
 SG_ ScorePecc : 0|7@1+ (1,-1) [-1|126] "Index"  NODE_D4

BO_ 2561134922 DSE_LNDPT_DBG: 8 PCM
 SG_ EventLaneDpt : 16|2@1+ (1,0) [0|3] ""  NODE_D1
 SG_ EvaluatedSamplesLaneDpt : 0|16@1+ (1,-1) [-1|65534] ""  NODE_D1

BO_ 2561134666 DSE_LNDPT: 8 PCM
 SG_ WeightLaneDpt : 16|32@1+ (1,-1) [-1|4294967294] ""  NODE_D0
 SG_ BenefitLaneDpt : 12|2@1+ (1,0) [0|0] ""  NODE_D0
 SG_ TrendLaneDpt : 10|2@1+ (1,-1) [-1|2] ""  NODE_D0
 SG_ ValidLaneDpt : 8|2@1+ (1,0) [0|0] ""  NODE_D0
 SG_ ScoreLaneDpt : 0|7@1+ (1,-1) [-1|126] "Index"  NODE_D0

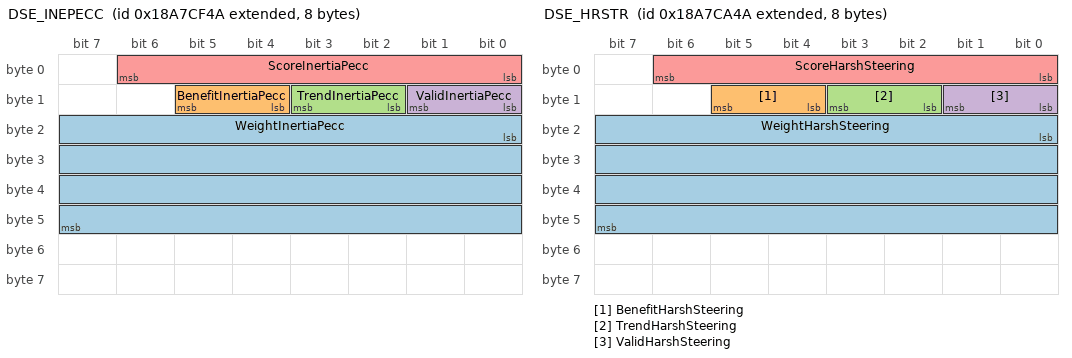
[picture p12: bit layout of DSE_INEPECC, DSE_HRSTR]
BO_ 2561134410 DSE_INEPECC: 8 PCM
 SG_ WeightInertiaPecc : 16|32@1+ (1,-1) [-1|4294967294] ""  NODE_CF
 SG_ BenefitInertiaPecc : 12|2@1+ (1,0) [0|0] ""  NODE_CF
 SG_ TrendInertiaPecc : 10|2@1+ (1,-1) [-1|2] ""  NODE_CF
 SG_ ValidInertiaPecc : 8|2@1+ (1,0) [0|0] ""  NODE_CF
 SG_ ScoreInertiaPecc : 0|7@1+ (1,-1) [-1|126] "Index"  NODE_CF

BO_ 2561133386 DSE_HRSTR_DBG: 8 PCM
 SG_ EventHarshSteering : 16|2@1+ (1,0) [0|3] ""  NODE_CB
 SG_ EvaluatedMetersHarshSteering : 0|16@1+ (1,-1) [-1|65534] "m"  NODE_CB

BO_ 2561133130 DSE_HRSTR: 8 PCM
 SG_ WeightHarshSteering : 16|32@1+ (1,-1) [-1|4294967294] ""  NODE_CA
 SG_ BenefitHarshSteering : 12|2@1+ (1,0) [0|0] ""  NODE_CA
 SG_ TrendHarshSteering : 10|2@1+ (1,-1) [-1|2] ""  NODE_CA
 SG_ ValidHarshSteering : 8|2@1+ (1,0) [0|0] ""  NODE_CA
 SG_ ScoreHarshSteering : 0|7@1+ (1,-1) [-1|126] "Index"  NODE_CA

BO_ 2561132362 DSE_HNBK_DBG: 8 PCM
 SG_ EventHandBrake : 16|2@1+ (1,0) [0|3] ""  NODE_C7
 SG_ NumEventsHandBrake : 0|16@1+ (1,-1) [-1|65534] ""  NODE_C7

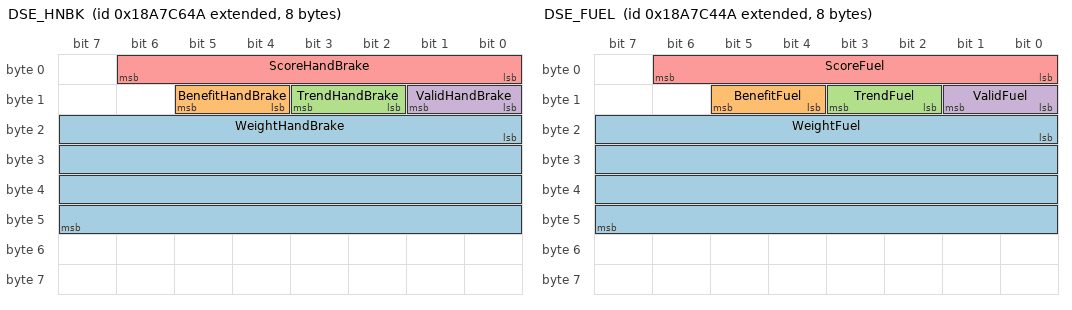
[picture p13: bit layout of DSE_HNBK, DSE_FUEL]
BO_ 2561132106 DSE_HNBK: 8 PCM
 SG_ WeightHandBrake : 16|32@1+ (1,-1) [-1|4294967294] ""  NODE_C6
 SG_ BenefitHandBrake : 12|2@1+ (1,0) [0|0] ""  NODE_C6
 SG_ TrendHandBrake : 10|2@1+ (1,-1) [-1|2] ""  NODE_C6
 SG_ ValidHandBrake : 8|2@1+ (1,0) [0|0] ""  NODE_C6
 SG_ ScoreHandBrake : 0|7@1+ (1,-1) [-1|126] "Index"  NODE_C6

BO_ 2561131594 DSE_FUEL: 8 PCM
 SG_ WeightFuel : 16|32@1+ (1,-1) [-1|4294967294] ""  NODE_C4
 SG_ BenefitFuel : 12|2@1+ (1,0) [0|0] ""  NODE_C4
 SG_ TrendFuel : 10|2@1+ (1,-1) [-1|2] ""  NODE_C4
 SG_ ValidFuel : 8|2@1+ (1,0) [0|0] ""  NODE_C4
 SG_ ScoreFuel : 0|7@1+ (1,-1) [-1|126] "Index"  NODE_C4

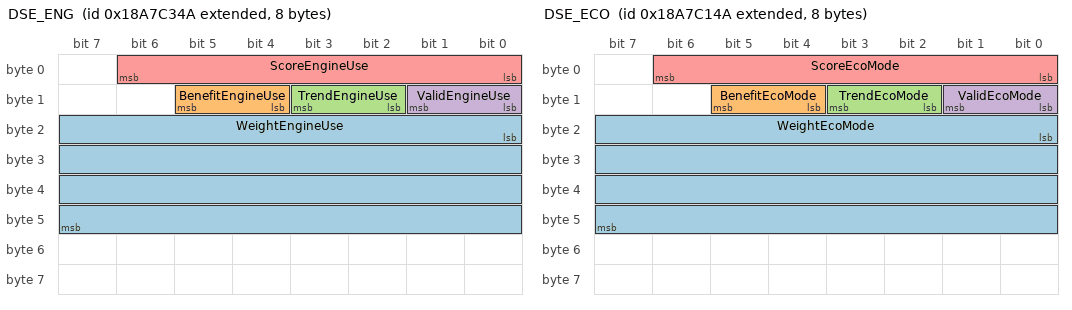
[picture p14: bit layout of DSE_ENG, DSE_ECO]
BO_ 2561131338 DSE_ENG: 8 PCM
 SG_ WeightEngineUse : 16|32@1+ (1,-1) [-1|4294967294] ""  NODE_C3
 SG_ BenefitEngineUse : 12|2@1+ (1,0) [0|0] ""  NODE_C3
 SG_ TrendEngineUse : 10|2@1+ (1,-1) [-1|2] ""  NODE_C3
 SG_ ValidEngineUse : 8|2@1+ (1,0) [0|0] ""  NODE_C3
 SG_ ScoreEngineUse : 0|7@1+ (1,-1) [-1|126] "Index"  NODE_C3

BO_ 2561131082 DSE_ECO_DBG: 8 PCM
 SG_ EvaluatedSamplesEcoMode : 0|16@1+ (1,-1) [-1|65534] ""  NODE_C2

BO_ 2561130826 DSE_ECO: 8 PCM
 SG_ WeightEcoMode : 16|32@1+ (1,-1) [-1|4294967294] ""  NODE_C1
 SG_ BenefitEcoMode : 12|2@1+ (1,0) [0|0] ""  NODE_C1
 SG_ TrendEcoMode : 10|2@1+ (1,-1) [-1|2] ""  NODE_C1
 SG_ ValidEcoMode : 8|2@1+ (1,0) [0|0] ""  NODE_C1
 SG_ ScoreEcoMode : 0|7@1+ (1,-1) [-1|126] "Index"  NODE_C1

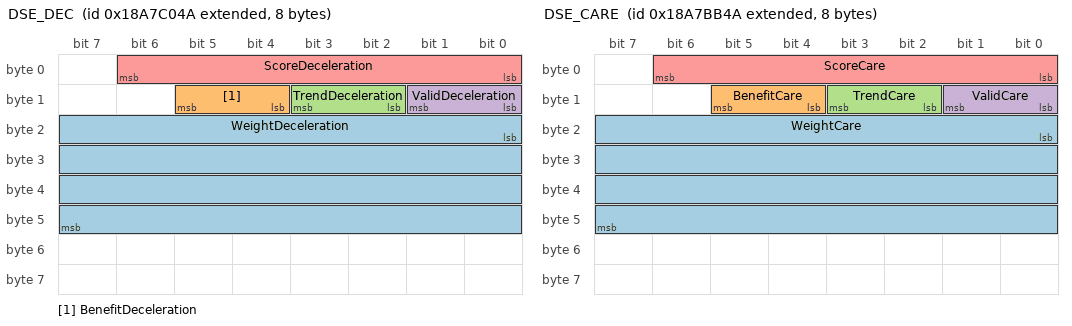
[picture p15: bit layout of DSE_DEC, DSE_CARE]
BO_ 2561130570 DSE_DEC: 8 PCM
 SG_ WeightDeceleration : 16|32@1+ (1,-1) [-1|4294967294] ""  NODE_C0
 SG_ BenefitDeceleration : 12|2@1+ (1,0) [0|0] ""  NODE_C0
 SG_ TrendDeceleration : 10|2@1+ (1,-1) [-1|2] ""  NODE_C0
 SG_ ValidDeceleration : 8|2@1+ (1,0) [0|0] ""  NODE_C0
 SG_ ScoreDeceleration : 0|7@1+ (1,-1) [-1|126] "Index"  NODE_C0

BO_ 2561129802 DSE_CURNT: 8 PCM
 SG_ TimeStampCurrent : 32|32@1+ (1,946684800) [946684800|5241652095] "Date"  NODE_BD
 SG_ OdometerTripCurrent : 0|32@1+ (5,-1) [-1|21474836474] "m"  NODE_BD

BO_ 2561129290 DSE_CARE: 8 PCM
 SG_ WeightCare : 16|32@1+ (1,-1) [-1|4294967294] ""  NODE_BB
 SG_ BenefitCare : 12|2@1+ (1,0) [0|0] ""  NODE_BB
 SG_ TrendCare : 10|2@1+ (1,-1) [-1|2] ""  NODE_BB
 SG_ ValidCare : 8|2@1+ (1,0) [0|0] ""  NODE_BB
 SG_ ScoreCare : 0|7@1+ (1,-1) [-1|126] "Index"  NODE_BB

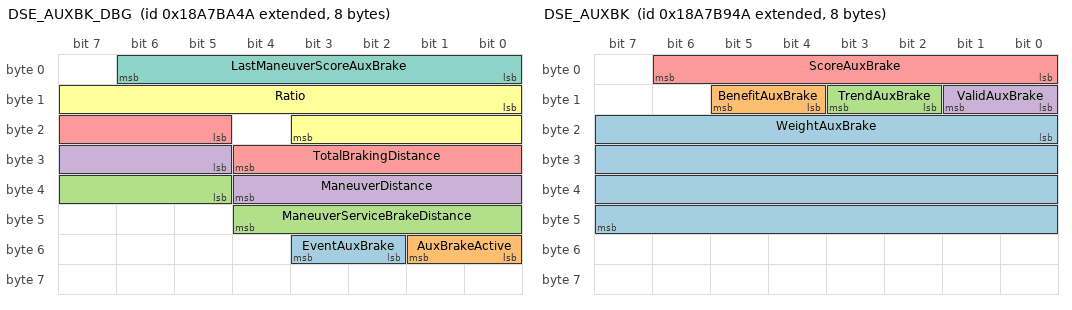
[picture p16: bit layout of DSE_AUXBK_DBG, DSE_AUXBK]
BO_ 2561129034 DSE_AUXBK_DBG: 8 PCM
 SG_ EventAuxBrake : 50|2@1+ (1,0) [0|3] ""  NODE_BA
 SG_ AuxBrakeActive : 48|2@1+ (1,0) [0|3] ""  NODE_BA
 SG_ ManeuverServiceBrakeDistance : 37|8@1+ (1,-1) [-1|254] "m"  NODE_BA
 SG_ ManeuverDistance : 29|8@1+ (1,-1) [-1|254] "m"  NODE_BA
 SG_ TotalBrakingDistance : 21|8@1+ (1,-1) [-1|254] "m"  NODE_BA
 SG_ Ratio : 8|12@1+ (0.1,-1) [-1|408.5] ""  NODE_BA
 SG_ LastManeuverScoreAuxBrake : 0|7@1+ (1,-1) [-1|126] "Index"  NODE_BA

BO_ 2561128778 DSE_AUXBK: 8 PCM
 SG_ WeightAuxBrake : 16|32@1+ (1,-1) [-1|4294967294] ""  NODE_B9
 SG_ BenefitAuxBrake : 12|2@1+ (1,0) [0|0] ""  NODE_B9
 SG_ TrendAuxBrake : 10|2@1+ (1,-1) [-1|2] ""  NODE_B9
 SG_ ValidAuxBrake : 8|2@1+ (1,0) [0|0] ""  NODE_B9
 SG_ ScoreAuxBrake : 0|7@1+ (1,-1) [-1|126] "Index"  NODE_B9

BO_ 2561128522 DSE_AIRC_DBG: 8 PCM
 SG_ EvaluatedSamplesAirC : 0|16@1+ (1,-1) [-1|65534] ""  NODE_B8

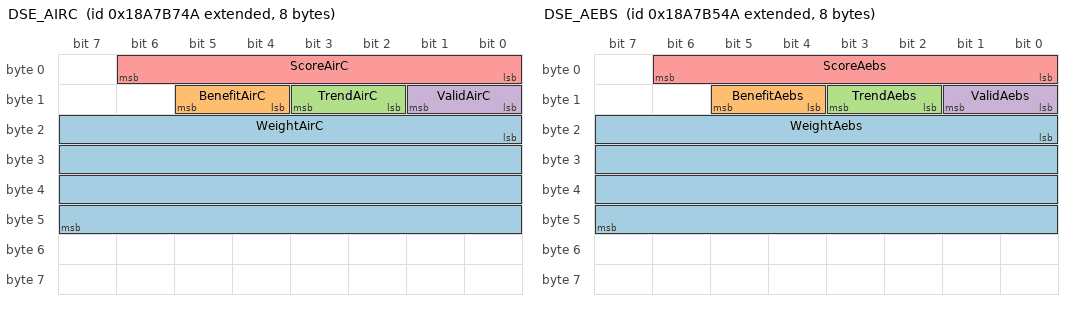
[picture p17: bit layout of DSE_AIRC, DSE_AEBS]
BO_ 2561128266 DSE_AIRC: 8 PCM
 SG_ WeightAirC : 16|32@1+ (1,-1) [-1|4294967294] ""  NODE_B7
 SG_ BenefitAirC : 12|2@1+ (1,0) [0|0] ""  NODE_B7
 SG_ TrendAirC : 10|2@1+ (1,-1) [-1|2] ""  NODE_B7
 SG_ ValidAirC : 8|2@1+ (1,0) [0|0] ""  NODE_B7
 SG_ ScoreAirC : 0|7@1+ (1,-1) [-1|126] "Index"  NODE_B7

BO_ 2561128010 DSE_AEBS_DBG: 8 PCM
 SG_ EventAebs : 16|2@1+ (1,0) [0|3] ""  NODE_B6
 SG_ EvaluatedSamplesAebs : 0|16@1+ (1,-1) [-1|65534] ""  NODE_B6

BO_ 2561126986 DSE_ACC_DBG: 8 PCM
 SG_ EventAcc : 16|2@1+ (1,0) [0|3] ""  NODE_B2
 SG_ EvaluatedSamplesAcc : 0|16@1+ (1,-1) [-1|65534] ""  NODE_B2

BO_ 2561127754 DSE_AEBS: 8 PCM
 SG_ WeightAebs : 16|32@1+ (1,-1) [-1|4294967294] ""  NODE_B5
 SG_ BenefitAebs : 12|2@1+ (1,0) [0|0] ""  NODE_B5
 SG_ TrendAebs : 10|2@1+ (1,-1) [-1|2] ""  NODE_B5
 SG_ ValidAebs : 8|2@1+ (1,0) [0|0] ""  NODE_B5
 SG_ ScoreAebs : 0|7@1+ (1,-1) [-1|126] "Index"  NODE_B5

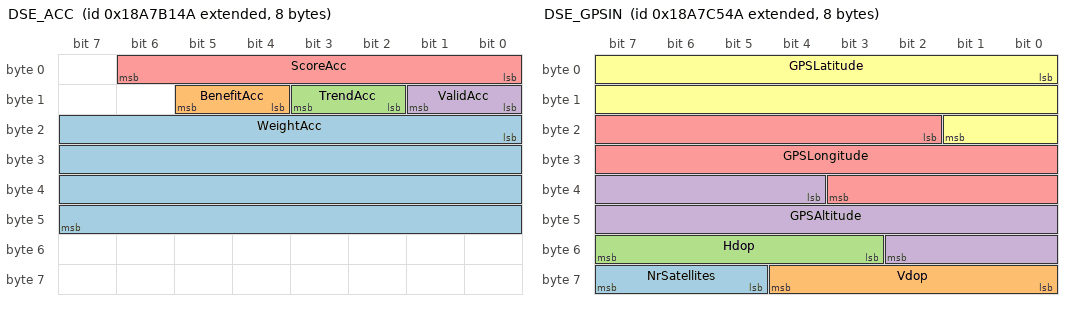
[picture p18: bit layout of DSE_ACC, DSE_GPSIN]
BO_ 2561126730 DSE_ACC: 8 PCM
 SG_ WeightAcc : 16|32@1+ (1,-1) [-1|4294967294] ""  NODE_B1
 SG_ BenefitAcc : 12|2@1+ (1,0) [0|0] ""  NODE_B1
 SG_ TrendAcc : 10|2@1+ (1,-1) [-1|2] ""  NODE_B1
 SG_ ValidAcc : 8|2@1+ (1,0) [0|0] ""  NODE_B1
 SG_ ScoreAcc : 0|7@1+ (1,-1) [-1|126] "Index"  NODE_B1

BO_ 2561129546 DSE_CMD: 8 PCM
 SG_ ResetEcoB : 2|2@1+ (1,0) [0|0] ""  NODE_BC
 SG_ ResetEcoA : 0|2@1+ (1,0) [0|0] ""  NODE_BC

BO_ 2561135434 DSE_OLDDAS: 8 PCM
 SG_ OldDasEnabled : 44|2@1- (1,0) [0|0] ""  NODE_D3
 SG_ OldDasWarning : 42|2@1+ (1,0) [0|0] ""  NODE_D3
 SG_ OldDasStop : 40|2@1+ (1,0) [0|0] ""  NODE_D3
 SG_ OldDasStatus : 32|8@1+ (1,0) [0|0] ""  NODE_D3
 SG_ OldDasPiswa : 0|32@1- (1,0) [0|0] ""  NODE_D3

BO_ 2561135178 DSE_NOTF: 8 PCM
 SG_ NotificationEnabled : 16|2@1+ (1,0) [0|3] ""  NODE_D2
 SG_ NotificationCritical : 14|2@1+ (1,0) [0|3] ""  NODE_D2
 SG_ NotificationTypeId : 8|6@1+ (1,0) [0|63] ""  NODE_D2
 SG_ NotificationTextId : 0|6@1+ (1,0) [0|63] ""  NODE_D2

BO_ 2561131850 DSE_GPSIN: 8 PCM
 SG_ NrSatellites : 61|3@1+ (1,0) [0|7] ""  NODE_C5
 SG_ Vdop : 56|5@1+ (1,0) [0|25] ""  NODE_C5
 SG_ Hdop : 51|5@1+ (1,0) [0|25] ""  NODE_C5
 SG_ GPSAltitude : 36|15@1+ (0.2,-500) [-500|6053.4] ""  NODE_C5
 SG_ GPSLongitude : 18|18@1- (0.0015,0) [-196.608|196.6065] ""  NODE_C5
 SG_ GPSLatitude : 0|18@1- (0.001,0) [-131.072|131.071] ""  NODE_C5

BO_ 2561140298 DSE_VER: 8 PCM
 SG_ VersionModel : 24|8@1+ (1,-1) [0|0] ""  NODE_E6
 SG_ VersionRevision : 16|8@1+ (1,-1) [0|0] ""  NODE_E6
 SG_ VersionMinor : 8|8@1+ (1,-1) [0|0] ""  NODE_E6
 SG_ VersionMajor : 0|8@1+ (1,-1) [0|0] ""  NODE_E6

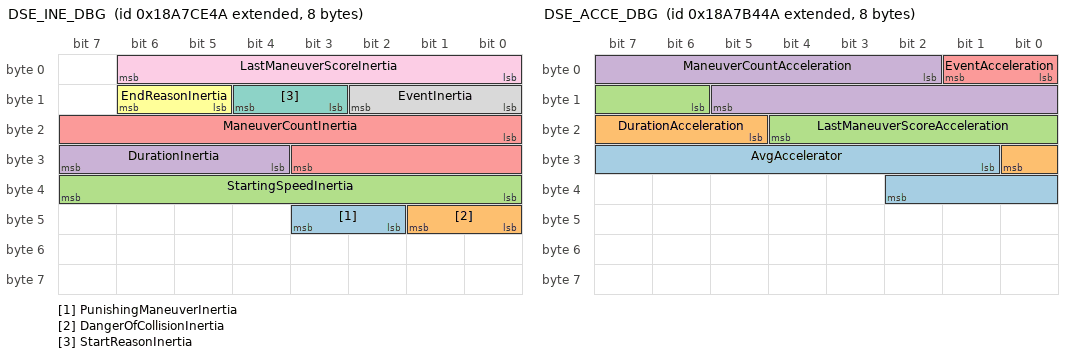
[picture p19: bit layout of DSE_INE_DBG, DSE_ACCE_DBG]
BO_ 2561134154 DSE_INE_DBG: 8 PCM
 SG_ PunishingManeuverInertia : 42|2@1+ (1,0) [0|0] ""  NODE_CE
 SG_ DangerOfCollisionInertia : 40|2@1+ (1,0) [0|0] ""  NODE_CE
 SG_ StartingSpeedInertia : 32|8@1+ (0.5,0) [0|127.5] "km/h"  NODE_CE
 SG_ DurationInertia : 28|4@1+ (1,-1) [-1|14] "s"  NODE_CE
 SG_ ManeuverCountInertia : 16|12@1+ (1,-1) [-1|4094] "Count"  NODE_CE
 SG_ EndReasonInertia : 13|2@1+ (1,0) [0|3] ""  NODE_CE
 SG_ StartReasonInertia : 11|2@1+ (1,0) [0|3] ""  NODE_CE
 SG_ EventInertia : 8|3@1+ (1,0) [0|7] ""  NODE_CE
 SG_ LastManeuverScoreInertia : 0|7@1+ (1,-1) [-1|126] "Index"  NODE_CE

BO_ 2561133898 DSE_INE: 8 PCM
 SG_ WeightInertia : 16|32@1+ (1,-1) [-1|4294967294] ""  NODE_CD
 SG_ BenefitInertia : 12|2@1+ (1,0) [0|0] ""  NODE_CD
 SG_ TrendInertia : 10|2@1+ (1,-1) [-1|2] ""  NODE_CD
 SG_ ValidInertia : 8|2@1+ (1,0) [0|0] ""  NODE_CD
 SG_ ScoreInertia : 0|7@1+ (1,-1) [-1|126] "Index"  NODE_CD

BO_ 2561127498 DSE_ACCE_DBG: 8 PCM
 SG_ AvgAccelerator : 25|10@1+ (0.1,-1) [-1|101.3] "%"  NODE_B4
 SG_ DurationAcceleration : 21|4@1+ (1,-1) [-1|14] "s"  NODE_B4
 SG_ LastManeuverScoreAcceleration : 14|7@1+ (1,-1) [-1|126] "Index"  NODE_B4
 SG_ ManeuverCountAcceleration : 2|12@1+ (1,-1) [-1|4094] "Count"  NODE_B4
 SG_ EventAcceleration : 0|2@1+ (1,0) [0|3] ""  NODE_B4

BO_ 2561127242 DSE_ACCE: 8 PCM
 SG_ WeightAcceleration : 16|32@1+ (1,-1) [-1|4294967294] ""  NODE_B3
 SG_ BenefitAcceleration : 12|2@1+ (1,0) [0|0] ""  NODE_B3
 SG_ TrendAcceleration : 10|2@1+ (1,-1) [-1|2] ""  NODE_B3
 SG_ ValidAcceleration : 8|2@1+ (1,0) [0|0] ""  NODE_B3
 SG_ ScoreAcceleration : 0|7@1+ (1,-1) [-1|126] "Index"  NODE_B3

BO_ 2566894154 PB_EVR_4A: 8 PCM
 SG_ GetChargedTime : 40|16@1+ (1,0) [0|64255] "min" Vector__XXX

BO_ 2566896970 PB_IdCrash2_4A: 8 PCM
 SG_ IdCrashDevice4 : 32|32@1+ (1,0) [0|4294967295] "" Vector__XXX
 SG_ IdCrashDevice3 : 0|32@1+ (1,0) [0|4294967295] "" Vector__XXX

BO_ 2566893898 PB_CrashInfo_4A: 8 PCM
 SG_ CrashEventType : 0|3@1+ (1,0) [0|7] "" Vector__XXX

BO_ 2566895434 PB_IdCrash_4A: 8 PCM
 SG_ IdCrashDevice2 : 32|32@1+ (1,0) [0|4294967295] "" Vector__XXX
 SG_ IdCrashDevice : 0|32@1+ (1,0) [0|4294967295] "" Vector__XXX

BO_ 2566845491 TIRE1: 8 OptiTire
 SG_ TirePrsThrsDetAx1InnLe m1 : 61|3@1+ (1,0) [0|7] ""  PCM
 SG_ TirePrsThrsDetAx1InnRi m2 : 61|3@1+ (1,0) [0|7] ""  PCM
 SG_ TirePrsThrsDetAx1OutLe m0 : 61|3@1+ (1,0) [0|7] ""  PCM
 SG_ TirePrsThrsDetAx1OutRi m3 : 61|3@1+ (1,0) [0|7] ""  PCM
 SG_ TirePrsThrsDetAx2InnLe m17 : 61|3@1+ (1,0) [0|7] ""  PCM
 SG_ TirePrsThrsDetAx2InnRi m18 : 61|3@1+ (1,0) [0|7] ""  PCM
 SG_ TirePrsThrsDetAx2OutLe m16 : 61|3@1+ (1,0) [0|7] ""  PCM
 SG_ TirePrsThrsDetAx2OutRi m19 : 61|3@1+ (1,0) [0|7] ""  PCM
 SG_ TirePrsThrsDetAx3InnLe m33 : 61|3@1+ (1,0) [0|7] ""  PCM
 SG_ TirePrsThrsDetAx3InnRi m34 : 61|3@1+ (1,0) [0|7] ""  PCM
 SG_ TirePrsThrsDetAx3OutLe m32 : 61|3@1+ (1,0) [0|7] ""  PCM
 SG_ TirePrsThrsDetAx3OutRi m35 : 61|3@1+ (1,0) [0|7] ""  PCM
 SG_ TirePrsThrsDetAx4InnLe m49 : 61|3@1+ (1,0) [0|7] ""  PCM
 SG_ TirePrsThrsDetAx4InnRi m50 : 61|3@1+ (1,0) [0|7] ""  PCM
 SG_ TirePrsThrsDetAx4OutLe m48 : 61|3@1+ (1,0) [0|7] ""  PCM
 SG_ TirePrsThrsDetAx4OutRi m51 : 61|3@1+ (1,0) [0|7] ""  PCM
 SG_ ExTirePrsSupp m0 : 38|2@1+ (1,0) [0|3] ""  PCM
 SG_ TireSensElFault m0 : 36|2@1+ (1,0) [0|3] ""  PCM
 SG_ TireSensEnaSts m0 : 32|2@1+ (1,0) [0|3] ""  PCM
 SG_ TireTempAx1InnLe m1 : 16|16@1+ (0.03125,-273) [-273|1734.96875] "�C"  PCM
 SG_ TireTempAx1InnRi m2 : 16|16@1+ (0.03125,-273) [-273|1734.96875] "�C"  PCM
 SG_ TireTempAx1OutLe m0 : 16|16@1+ (0.03125,-273) [-273|1734.96875] "�C"  PCM
 SG_ TireTempAx1OutRi m3 : 16|16@1+ (0.03125,-273) [-273|1734.96875] "�C"  PCM
 SG_ TireTempAx2InnLe m17 : 16|16@1+ (0.03125,-273) [-273|1734.96875] "�C"  PCM
 SG_ TireTempAx2InnRi m18 : 16|16@1+ (0.03125,-273) [-273|1734.96875] "�C"  PCM
 SG_ TireTempAx2OutLe m16 : 16|16@1+ (0.03125,-273) [-273|1734.96875] "�C"  PCM
 SG_ TireTempAx2OutRi m19 : 16|16@1+ (0.03125,-273) [-273|1734.96875] "�C"  PCM
 SG_ TireTempAx3InnLe m33 : 16|16@1+ (0.03125,-273) [-273|1734.96875] "�C"  PCM
 SG_ TireTempAx3InnRi m34 : 16|16@1+ (0.03125,-273) [-273|1734.96875] "�C"  PCM
 SG_ TireTempAx3OutLe m32 : 16|16@1+ (0.03125,-273) [-273|1734.96875] "�C"  PCM
 SG_ TireTempAx3OutRi m35 : 16|16@1+ (0.03125,-273) [-273|1734.96875] "�C"  PCM
 SG_ TireTempAx4InnLe m49 : 16|16@1+ (0.03125,-273) [-273|1734.96875] "�C"  PCM
 SG_ TireTempAx4InnRi m50 : 16|16@1+ (0.03125,-273) [-273|1734.96875] "�C"  PCM
 SG_ TireTempAx4OutLe m48 : 16|16@1+ (0.03125,-273) [-273|1734.96875] "�C"  PCM
 SG_ TireTempAx4OutRi m51 : 16|16@1+ (0.03125,-273) [-273|1734.96875] "�C"  PCM
 SG_ TirePrsAx1OutRi m3 : 8|8@1+ (4,0) [0|1000] "kPa"  PCM
 SG_ TirePrsAx1InnLe m1 : 8|8@1+ (4,0) [0|1000] "kPa"  PCM
 SG_ TirePrsAx1InnRi m2 : 8|8@1+ (4,0) [0|1000] "kPa"  PCM
 SG_ TirePrsAx1OutLe m0 : 8|8@1+ (4,0) [0|1000] "kPa"  PCM
 SG_ TirePrsAx2InnLe m17 : 8|8@1+ (4,0) [0|1000] "kPa"  PCM
 SG_ TirePrsAx2InnRi m18 : 8|8@1+ (4,0) [0|1000] "kPa"  PCM
 SG_ TirePrsAx2OutLe m16 : 8|8@1+ (4,0) [0|1000] "kPa"  PCM
 SG_ TirePrsAx2OutRi m19 : 8|8@1+ (4,0) [0|1000] "kPa"  PCM
 SG_ TirePrsAx3InnLe m33 : 8|8@1+ (4,0) [0|1000] "kPa"  PCM
 SG_ TirePrsAx3InnRi m34 : 8|8@1+ (4,0) [0|1000] "kPa"  PCM
 SG_ TirePrsAx3OutLe m32 : 8|8@1+ (4,0) [0|1000] "kPa"  PCM
 SG_ TirePrsAx3OutRi m35 : 8|8@1+ (4,0) [0|1000] "kPa"  PCM
 SG_ TirePrsAx4InnLe m49 : 8|8@1+ (4,0) [0|1000] "kPa"  PCM
 SG_ TirePrsAx4InnRi m50 : 8|8@1+ (4,0) [0|1000] "kPa"  PCM
 SG_ TirePrsAx4OutLe m48 : 8|8@1+ (4,0) [0|1000] "kPa"  PCM
 SG_ TirePrsAx4OutRi m51 : 8|8@1+ (4,0) [0|1000] "kPa"  PCM
 SG_ TireLoc_FEF433 M : 0|8@1+ (1,0) [0|255] ""  PCM

BO_ 2565982748 DM01_1C: 82 PCM
 SG_ SpnCm20_FECA1C : 655|1@1+ (1,0) [0|1] "" Vector__XXX

BO_ 2566845212 VP1_1C: 8 PCM
 SG_ Long_FEF31C : 32|32@1+ (1E-007,-210) [-210|211.1081215] "deg" Vector__XXX
 SG_ Lat_FEF31C : 0|32@1+ (1E-007,-210) [-210|211.1081215] "deg" Vector__XXX

CM_ SG_ 2251374793 TurnRightLight "- On Daily MY24 values are (00 Off; 01 On; 10 Error & Off; 11 Error and On)";
CM_ SG_ 2251374793 TurnLeftLight "- On Daily MY24 values are (00 Off; 01 On; 10 Error & Off; 11 Error and On)";
CM_ SG_ 2251374793 StopLight "- On Daily MY24 values are (00 Off; 01 On; 10 Error & Off; 11 Error and On)";
CM_ SG_ 2251374793 RevGearLight "- On Daily MY24 values are (00 Off; 01 On; 10 Error & Off; 11 Error and On)";
CM_ SG_ 2251374793 RearFogLight_140C9 "- On Daily MY24 values are (00 Off; 01 On; 10 Error & Off; 11 Error and On)";
CM_ SG_ 2251374793 PosLight "- On Daily MY24 values are (00 Off; 01 On; 10 Error & Off; 11 Error and On)";
CM_ SG_ 2317131777 EassSoCond "- In Fiat 07332 assigned to ColdStartLampIndication";
CM_ SG_ 2317131777 SamInfo "- Logistic Mode value available on VT from MY24";
CM_ SG_ 2317131777 SuggGearGsi "- Only with F1A and 2835.6 manual transmission";
CM_ BO_ 2251374616 "- Original Fiat name STATUS_PAM_V2";
CM_ SG_ 2348885874 TransmMode8 "- Application Counter (0 to 3)";
CM_ BO_ 2566840835 "-  2 Message Variant(s): Transm.Rates OnRequest, OnRequest
-  Multipacket message handled by SAE Transport Protocol (J1939/21, par 5.10, Multipacket Broadcast with TP.CM/BAM, TP.DT)
-  Multipacket message handled by SAE Transport Protocol (J1939/21, par 5.10, Multipacket Broadcast with TP.CM/BAM, TP.DT)";
CM_ SG_ 2566751205 TcSts_FD83E5 "- 010b Neutral, 100b Low Range, 001b High Range, 101b Shift in progress, 110b Error, 111b Not available";
CM_ BO_ 2365484270 "- FMS Trans.Rate=1s
-  SAE Trans.Rate=50ms";
CM_ SG_ 2365484270 Driv2TimeRelSts "- SAE J1939 Value Table different to ISO16844-7 definition (used by DTCO)";
CM_ SG_ 2365484270 Driv1TimeRelSts "- SAE J1939 Value Table different to ISO16844-7 definition (used by DTCO)";
CM_ BO_ 2566842094 "- SAE Trans.Rate=On Request";
CM_ SG_ 2566842094 Yr "- SAE J1939/73 Freeze Frame parameter";
CM_ SG_ 2566842094 Day "- SAE J1939/73 Freeze Frame parameter";
CM_ SG_ 2566842094 Month "- SAE J1939/73 Freeze Frame parameter";
CM_ SG_ 2566842094 Hr "- SAE J1939/73 Freeze Frame parameter";
CM_ SG_ 2566842094 Min "- SAE J1939/73 Freeze Frame parameter";
CM_ SG_ 2566842094 Sec "- SAE J1939/73 Freeze Frame parameter";
CM_ BO_ 2566841921 "- Cyclic Transmission Rate as result of PGN requests";
CM_ SG_ 2566841921 Yr_FEE641 "- GPS Time";
CM_ SG_ 2566841921 Day_FEE641 "- GPS Time";
CM_ SG_ 2566841921 Month_FEE641 "- GPS Time";
CM_ SG_ 2566841921 Hr_FEE641 "- GPS Time";
CM_ SG_ 2566841921 Min_FEE641 "- GPS Time";
CM_ SG_ 2566841921 Sec_FEE641 "- GPS Time";
CM_ SG_ 2566841930 Yr_FEE64A "- GPS Time";
CM_ SG_ 2566841930 Day_FEE64A "- GPS Time";
CM_ SG_ 2566841930 Month_FEE64A "- GPS Time";
CM_ SG_ 2566841930 Hr_FEE64A "- GPS Time";
CM_ SG_ 2566841930 Min_FEE64A "- GPS Time";
CM_ SG_ 2566841930 Sec_FEE64A "- GPS Time";
CM_ BO_ 2566764851 "- Not implemented in TPMS Sensata Step1 Stralis MY2019";
CM_ SG_ 2566803211 VdcInfoSig "- VDC lamp status";
CM_ SG_ 2566832622 TotVehDistHr "- SAE J1939/73 Freeze Frame parameter";
CM_ SG_ 2566846208 BatPot_PwrIn1 "- SAE J1939/73 Freeze Frame parameter";
CM_ BO_ 2566846241 "- SAE Trans.Rate=1000ms";
CM_ SG_ 2566846241 BatPot_PwrIn1_FEF721 "- SAE J1939/73 Freeze Frame parameter";
CM_ BO_ 2566843392 "-  2 Message Variant(s): Transm.Rates 10000, OnRequest
-  As a deviation from SAE, when multi-packet, this message is always sent without control flow (Broadcast mode)
-  Cyclic Transmission Rate as result of PGN requests
-  Multipacket message handled by SAE Transport Protocol (J1939/21, par 5.10, Multipacket Broadcast with TP.CM/BAM, TP.DT)
-  Variable Message Length, maximum value used for dbc generation
-  As a deviation from SAE, when multi-packet, this message is always sent without control fl";
CM_ SG_ 2566843392 Vin "- 17 bytes followed by an * delimiter
-  Variable signal length, 8 bits used for dbc generation only";
CM_ BO_ 2566843466 "- Multipacket message handled by SAE Transport Protocol (J1939/21, par 5.10, Multipacket Broadcast with TP.CM/BAM, TP.DT)
-  Variable Message Length, maximum value used for dbc generation";
CM_ SG_ 2566843466 Vin_FEEC4A "- 17 bytes followed by an * delimiter
-  Variable signal length, 8 bits used for dbc generation only";
CM_ BO_ 2566843630 "- Multipacket message handled by SAE Transport Protocol (J1939/21, par 5.10, Multipacket Broadcast with TP.CM/BAM, TP.DT)
-  Variable Message Length, maximum value used for dbc generation";
CM_ SG_ 2566843630 Vin_FEECEE "- 17 bytes followed by an * delimiter
-  Variable signal length, 8 bits used for dbc generation only";
CM_ BO_ 2566842606 "- TBC";
CM_ SG_ 2348875082 StopTime "- SAE J1939/73 Freeze Frame parameter";
CM_ SG_ 2348874826 DrivingTime "- SAE J1939/73 Freeze Frame parameter";
CM_ SG_ 2348874826 RegenerationTime "- SAE J1939/73 Freeze Frame parameter";
CM_ SG_ 2348874570 RegenerationDistance "- SAE J1939/73 Freeze Frame parameter";
CM_ SG_ 2348874570 EcoSwitchDistance "- SAE J1939/73 Freeze Frame parameter";
CM_ SG_ 2348874314 EcoSwitchTime "- SAE J1939/73 Freeze Frame parameter";
CM_ SG_ 2348871242 StopNumbersOccurrences "- SAE J1939/73 Freeze Frame parameter";
CM_ SG_ 2348871242 DrivingDistance "- SAE J1939/73 Freeze Frame parameter";
CM_ SG_ 2348871242 WhBasedVehSpeedAvg "- SAE J1939/73 Freeze Frame parameter";
CM_ BO_ 2561140298 "DSE Version is MAJOR.MINOR.REVISION
Model version is MODEL";
CM_ BO_ 2566845491 "- SAE Trans.Rate=10s";
CM_ SG_ 2566845491 TirePrsThrsDetAx1InnLe "- SAE Resolution= 4kPa/bit";
CM_ SG_ 2566845491 TirePrsThrsDetAx1InnRi "- SAE Resolution= 4kPa/bit";
CM_ SG_ 2566845491 TirePrsThrsDetAx1OutLe "- SAE Resolution= 4kPa/bit";
CM_ SG_ 2566845491 TirePrsThrsDetAx1OutRi "- SAE Resolution= 4kPa/bit";
CM_ SG_ 2566845491 TirePrsThrsDetAx2InnLe "- SAE Resolution= 4kPa/bit";
CM_ SG_ 2566845491 TirePrsThrsDetAx2InnRi "- SAE Resolution= 4kPa/bit";
CM_ SG_ 2566845491 TirePrsThrsDetAx2OutLe "- SAE Resolution= 4kPa/bit";
CM_ SG_ 2566845491 TirePrsThrsDetAx2OutRi "- SAE Resolution= 4kPa/bit";
CM_ SG_ 2566845491 TirePrsThrsDetAx3InnLe "- SAE Resolution= 4kPa/bit";
CM_ SG_ 2566845491 TirePrsThrsDetAx3InnRi "- SAE Resolution= 4kPa/bit";
CM_ SG_ 2566845491 TirePrsThrsDetAx3OutLe "- SAE Resolution= 4kPa/bit";
CM_ SG_ 2566845491 TirePrsThrsDetAx3OutRi "- SAE Resolution= 4kPa/bit";
CM_ SG_ 2566845491 TirePrsThrsDetAx4InnLe "- SAE Resolution= 4kPa/bit";
CM_ SG_ 2566845491 TirePrsThrsDetAx4InnRi "- SAE Resolution= 4kPa/bit";
CM_ SG_ 2566845491 TirePrsThrsDetAx4OutLe "- SAE Resolution= 4kPa/bit";
CM_ SG_ 2566845491 TirePrsThrsDetAx4OutRi "- SAE Resolution= 4kPa/bit";
CM_ SG_ 2566845491 ExTirePrsSupp "- SAE Resolution= 4kPa/bit";
CM_ SG_ 2566845491 TireSensElFault "- SAE Resolution= 4kPa/bit";
CM_ SG_ 2566845491 TireSensEnaSts "- SAE Resolution= 4kPa/bit";
CM_ SG_ 2566845491 TireTempAx1InnLe "- SAE Resolution= 4kPa/bit";
CM_ SG_ 2566845491 TireTempAx1InnRi "- SAE Resolution= 4kPa/bit";
CM_ SG_ 2566845491 TireTempAx1OutLe "- SAE Resolution= 4kPa/bit";
CM_ SG_ 2566845491 TireTempAx1OutRi "- SAE Resolution= 4kPa/bit";
CM_ SG_ 2566845491 TireTempAx2InnLe "- SAE Resolution= 4kPa/bit";
CM_ SG_ 2566845491 TireTempAx2InnRi "- SAE Resolution= 4kPa/bit";
CM_ SG_ 2566845491 TireTempAx2OutLe "- SAE Resolution= 4kPa/bit";
CM_ SG_ 2566845491 TireTempAx2OutRi "- SAE Resolution= 4kPa/bit";
CM_ SG_ 2566845491 TireTempAx3InnLe "- SAE Resolution= 4kPa/bit";
CM_ SG_ 2566845491 TireTempAx3InnRi "- SAE Resolution= 4kPa/bit";
CM_ SG_ 2566845491 TireTempAx3OutLe "- SAE Resolution= 4kPa/bit";
CM_ SG_ 2566845491 TireTempAx3OutRi "- SAE Resolution= 4kPa/bit";
CM_ SG_ 2566845491 TireTempAx4InnLe "- SAE Resolution= 4kPa/bit";
CM_ SG_ 2566845491 TireTempAx4InnRi "- SAE Resolution= 4kPa/bit";
CM_ SG_ 2566845491 TireTempAx4OutLe "- SAE Resolution= 4kPa/bit";
CM_ SG_ 2566845491 TireTempAx4OutRi "- SAE Resolution= 4kPa/bit";
CM_ SG_ 2566845491 TirePrsAx1OutRi "- SAE Resolution= 4kPa/bit";
CM_ SG_ 2566845491 TirePrsAx1InnLe "- SAE Resolution= 4kPa/bit";
CM_ SG_ 2566845491 TirePrsAx1InnRi "- SAE Resolution= 4kPa/bit";
CM_ SG_ 2566845491 TirePrsAx1OutLe "- SAE Resolution= 4kPa/bit";
CM_ SG_ 2566845491 TirePrsAx2InnLe "- SAE Resolution= 4kPa/bit";
CM_ SG_ 2566845491 TirePrsAx2InnRi "- SAE Resolution= 4kPa/bit";
CM_ SG_ 2566845491 TirePrsAx2OutLe "- SAE Resolution= 4kPa/bit";
CM_ SG_ 2566845491 TirePrsAx2OutRi "- SAE Resolution= 4kPa/bit";
CM_ SG_ 2566845491 TirePrsAx3InnLe "- SAE Resolution= 4kPa/bit";
CM_ SG_ 2566845491 TirePrsAx3InnRi "- SAE Resolution= 4kPa/bit";
CM_ SG_ 2566845491 TirePrsAx3OutLe "- SAE Resolution= 4kPa/bit";
CM_ SG_ 2566845491 TirePrsAx3OutRi "- SAE Resolution= 4kPa/bit";
CM_ SG_ 2566845491 TirePrsAx4InnLe "- SAE Resolution= 4kPa/bit";
CM_ SG_ 2566845491 TirePrsAx4InnRi "- SAE Resolution= 4kPa/bit";
CM_ SG_ 2566845491 TirePrsAx4OutLe "- SAE Resolution= 4kPa/bit";
CM_ SG_ 2566845491 TirePrsAx4OutRi "- SAE Resolution= 4kPa/bit";
CM_ SG_ 2566845491 TireLoc_FEF433 "- 0Xh 1st, 1Xh 2nd 2Xh 3rd, 3Xh 4th axle
- X0h Left outer, X1h Left inner, X2h Right inner, X3h Right outer wheel";
CM_ BO_ 2565982748 "- Multipacket message handled by SAE Transport Protocol (J1939/21, par 5.10, Multipacket Broadcast with TP.CM/BAM, TP.DT)
-  Variable Message Length, maximum value used for dbc generation";
CM_ SG_ 2565982748 SpnCm20_FECA1C "- Always 0b";
BA_DEF_ BO_  "CI_MsgDefinition" STRING ;
BA_DEF_ BO_  "CI_MsgId" INT 0 2147483647;
BA_DEF_ BO_  "CI_MsgName" STRING ;
BA_DEF_ BO_  "GenMsgCycleTime" INT 0 3600000;
BA_DEF_ BO_  "GenMsgCycleTimeFast" INT 0 3600000;
BA_DEF_ BO_  "GenMsgDelayTime" INT 0 3600000;
BA_DEF_ BO_  "GenMsgILSupport" ENUM  "No","Yes";
BA_DEF_ BO_  "GenMsgNrOfRepetition" INT 0 1000000;
BA_DEF_ BO_  "GenMsgRequestable" INT 0 1;
BA_DEF_ BO_  "GenMsgSendType" ENUM  "cyclic","NotUsed","NotUsed","NotUsed","NotUsed","NotUsed","NotUsed","IfActive","noMsgSendType";
BA_DEF_ BO_  "GenMsgStartDelayTime" INT 0 100000;
BA_DEF_ BO_  "TpJ1939VarDlc" ENUM  "No","Yes";
BA_DEF_ BO_  "VFrameFormat" ENUM  "StandardCAN","ExtendedCAN","reserved","J1939PG";
BA_DEF_ SG_  "CI_ParId" STRING ;
BA_DEF_ SG_  "CI_SigId" INT 0 2147483647;
BA_DEF_ SG_  "CI_SigName" STRING ;
BA_DEF_ SG_  "GenSigEVName" STRING ;
BA_DEF_ SG_  "GenSigILSupport" ENUM  "No","Yes";
BA_DEF_ SG_  "GenSigInactiveValue" INT 0 2147483647;
BA_DEF_ SG_  "GenSigSendType" ENUM  "Cyclic","OnWrite","OnWriteWithRepetition","OnChange","OnChangeWithRepetition","IfActive","IfActiveWithRepetition","NoSigSendType";
BA_DEF_ SG_  "GenSigStartValue" INT 0 2147483647;
BA_DEF_ SG_  "GenSigTimeoutTime_PCM" INT 0 3600000;
BA_DEF_ SG_  "GenSigTimeoutTime_SGW" INT 0 3600000;
BA_DEF_ SG_  "SPN" INT 0 524287;
BA_DEF_ SG_  "SigType" ENUM  "Default","Range","RangeSigned","ASCII","Discrete","Control","ReferencePGN","DTC","StringDelimiter","StringLength","StringLengthControl";
BA_DEF_DEF_  "CI_MsgDefinition" "";
BA_DEF_DEF_  "CI_MsgId" 0;
BA_DEF_DEF_  "CI_MsgName" "";
BA_DEF_DEF_  "GenMsgCycleTime" 0;
BA_DEF_DEF_  "GenMsgCycleTimeFast" 0;
BA_DEF_DEF_  "GenMsgDelayTime" 1;
BA_DEF_DEF_  "GenMsgILSupport" "Yes";
BA_DEF_DEF_  "GenMsgNrOfRepetition" 0;
BA_DEF_DEF_  "GenMsgRequestable" 0;
BA_DEF_DEF_  "GenMsgSendType" "noMsgSendType";
BA_DEF_DEF_  "GenMsgStartDelayTime" 0;
BA_DEF_DEF_  "TpJ1939VarDlc" "No";
BA_DEF_DEF_  "VFrameFormat" "J1939PG";
BA_DEF_DEF_  "CI_ParId" "";
BA_DEF_DEF_  "CI_SigId" 0;
BA_DEF_DEF_  "CI_SigName" "";
BA_DEF_DEF_  "GenSigEVName" "Env@Nodename_@Signame";
BA_DEF_DEF_  "GenSigILSupport" "Yes";
BA_DEF_DEF_  "GenSigInactiveValue" 0;
BA_DEF_DEF_  "GenSigSendType" "NoSigSendType";
BA_DEF_DEF_  "GenSigStartValue" 0;
BA_DEF_DEF_  "GenSigTimeoutTime_PCM" 0;
BA_DEF_DEF_  "GenSigTimeoutTime_SGW" 0;
BA_DEF_DEF_  "SPN" 0;
BA_DEF_DEF_  "SigType" "Default";
BA_ "CI_MsgDefinition" BO_ 2251374793 "Iveco Daily Proprietary";
BA_ "CI_MsgId" BO_ 2251374793 42837;
BA_ "CI_MsgName" BO_ 2251374793 "StsAlm - ALM Status (B-CAN)";
BA_ "GenMsgCycleTime" BO_ 2251374793 50;
BA_ "GenMsgCycleTimeFast" BO_ 2251374793 50;
BA_ "GenMsgDelayTime" BO_ 2251374793 100;
BA_ "GenMsgSendType" BO_ 2251374793 0;
BA_ "GenMsgStartDelayTime" BO_ 2251374793 32;
BA_ "VFrameFormat" BO_ 2251374793 1;
BA_ "CI_MsgDefinition" BO_ 2317131777 "Iveco Daily Proprietary";
BA_ "CI_MsgId" BO_ 2317131777 29888;
BA_ "CI_MsgName" BO_ 2317131777 "StsEcm2-C - ECM Status 2 (VDB)";
BA_ "GenMsgCycleTime" BO_ 2317131777 50;
BA_ "GenMsgCycleTimeFast" BO_ 2317131777 50;
BA_ "GenMsgDelayTime" BO_ 2317131777 25;
BA_ "GenMsgSendType" BO_ 2317131777 0;
BA_ "GenMsgStartDelayTime" BO_ 2317131777 33;
BA_ "VFrameFormat" BO_ 2317131777 1;
BA_ "CI_MsgDefinition" BO_ 2251374616 "Iveco Daily Proprietary";
BA_ "CI_MsgId" BO_ 2251374616 41675;
BA_ "CI_MsgName" BO_ 2251374616 "StsPam - PAM Status (B-CAN)";
BA_ "GenMsgCycleTime" BO_ 2251374616 200;
BA_ "GenMsgCycleTimeFast" BO_ 2251374616 200;
BA_ "GenMsgDelayTime" BO_ 2251374616 100;
BA_ "GenMsgSendType" BO_ 2251374616 0;
BA_ "GenMsgStartDelayTime" BO_ 2251374616 97;
BA_ "VFrameFormat" BO_ 2251374616 1;
BA_ "CI_MsgDefinition" BO_ 2348885874 "J1939DA";
BA_ "CI_MsgId" BO_ 2348885874 1215;
BA_ "CI_MsgName" BO_ 2348885874 "TC1_72_27 - Transmission Control 1";
BA_ "GenMsgCycleTime" BO_ 2348885874 50;
BA_ "GenMsgCycleTimeFast" BO_ 2348885874 50;
BA_ "GenMsgDelayTime" BO_ 2348885874 25;
BA_ "GenMsgSendType" BO_ 2348885874 0;
BA_ "GenMsgStartDelayTime" BO_ 2348885874 34;
BA_ "CI_MsgDefinition" BO_ 2566840835 "J1939DA";
BA_ "CI_MsgId" BO_ 2566840835 1423;
BA_ "CI_MsgName" BO_ 2566840835 "TCFG - Transmission Configuration";
BA_ "CI_MsgDefinition" BO_ 2566750979 "J1939DA";
BA_ "CI_MsgId" BO_ 2566750979 1410;
BA_ "CI_MsgName" BO_ 2566750979 "TCI_03 - Transfer Case Information";
BA_ "GenMsgCycleTime" BO_ 2566750979 1000;
BA_ "GenMsgCycleTimeFast" BO_ 2566750979 1000;
BA_ "GenMsgDelayTime" BO_ 2566750979 100;
BA_ "GenMsgSendType" BO_ 2566750979 0;
BA_ "GenMsgStartDelayTime" BO_ 2566750979 167;
BA_ "CI_MsgDefinition" BO_ 2566751205 "J1939DA";
BA_ "CI_MsgId" BO_ 2566751205 1413;
BA_ "CI_MsgName" BO_ 2566751205 "TCI_E5 - Transfer Case Information";
BA_ "GenMsgCycleTime" BO_ 2566751205 1000;
BA_ "GenMsgCycleTimeFast" BO_ 2566751205 1000;
BA_ "GenMsgDelayTime" BO_ 2566751205 100;
BA_ "GenMsgSendType" BO_ 2566751205 0;
BA_ "GenMsgStartDelayTime" BO_ 2566751205 168;
BA_ "CI_MsgDefinition" BO_ 2365484270 "J1939DA";
BA_ "CI_MsgId" BO_ 2365484270 1511;
BA_ "CI_MsgName" BO_ 2365484270 "TCO1 - Tachograph";
BA_ "GenMsgCycleTime" BO_ 2365484270 20;
BA_ "GenMsgCycleTimeFast" BO_ 2365484270 20;
BA_ "GenMsgDelayTime" BO_ 2365484270 10;
BA_ "GenMsgSendType" BO_ 2365484270 0;
BA_ "GenMsgStartDelayTime" BO_ 2365484270 18;
BA_ "CI_MsgDefinition" BO_ 2566842094 "J1939DA";
BA_ "CI_MsgId" BO_ 2566842094 1589;
BA_ "CI_MsgName" BO_ 2566842094 "TD - Time/Date";
BA_ "GenMsgCycleTime" BO_ 2566842094 1000;
BA_ "GenMsgCycleTimeFast" BO_ 2566842094 1000;
BA_ "GenMsgDelayTime" BO_ 2566842094 500;
BA_ "GenMsgSendType" BO_ 2566842094 0;
BA_ "GenMsgStartDelayTime" BO_ 2566842094 232;
BA_ "CI_MsgDefinition" BO_ 2566841921 "J1939DA";
BA_ "CI_MsgId" BO_ 2566841921 1562;
BA_ "CI_MsgName" BO_ 2566841921 "TD_41 - Time/Date";
BA_ "GenMsgCycleTime" BO_ 2566841921 1000;
BA_ "GenMsgCycleTimeFast" BO_ 2566841921 1000;
BA_ "GenMsgDelayTime" BO_ 2566841921 500;
BA_ "GenMsgSendType" BO_ 2566841921 0;
BA_ "GenMsgStartDelayTime" BO_ 2566841921 231;
BA_ "CI_MsgDefinition" BO_ 2566841930 "J1939DA";
BA_ "CI_MsgId" BO_ 2566841930 1571;
BA_ "CI_MsgName" BO_ 2566841930 "TD_4A - Time/Date";
BA_ "CI_MsgDefinition" BO_ 2566764851 "J1939DA";
BA_ "CI_MsgId" BO_ 2566764851 6097;
BA_ "CI_MsgName" BO_ 2566764851 "TPRI - Tire Pressure Reference Information";
BA_ "CI_MsgDefinition" BO_ 2566846467 "J1939DA";
BA_ "CI_MsgId" BO_ 2566846467 1472;
BA_ "CI_MsgName" BO_ 2566846467 "TRF1 - Transmission Fluids 1";
BA_ "GenMsgCycleTime" BO_ 2566846467 1000;
BA_ "GenMsgCycleTimeFast" BO_ 2566846467 1000;
BA_ "GenMsgDelayTime" BO_ 2566846467 500;
BA_ "GenMsgSendType" BO_ 2566846467 0;
BA_ "GenMsgStartDelayTime" BO_ 2566846467 244;
BA_ "CI_MsgDefinition" BO_ 2566755587 "J1939DA";
BA_ "CI_MsgId" BO_ 2566755587 1481;
BA_ "CI_MsgName" BO_ 2566755587 "TRF2 - Transmission Fluids 2";
BA_ "GenMsgCycleTime" BO_ 2566755587 1000;
BA_ "GenMsgCycleTimeFast" BO_ 2566755587 1000;
BA_ "GenMsgDelayTime" BO_ 2566755587 500;
BA_ "GenMsgSendType" BO_ 2566755587 0;
BA_ "GenMsgStartDelayTime" BO_ 2566755587 169;
BA_ "CI_MsgDefinition" BO_ 2566803211 "J1939DA";
BA_ "CI_MsgId" BO_ 2566803211 751;
BA_ "CI_MsgName" BO_ 2566803211 "VDC1 - Vehicle Dynamic Stability Control 1";
BA_ "GenMsgCycleTime" BO_ 2566803211 100;
BA_ "GenMsgCycleTimeFast" BO_ 2566803211 100;
BA_ "GenMsgDelayTime" BO_ 2566803211 50;
BA_ "GenMsgSendType" BO_ 2566803211 0;
BA_ "GenMsgStartDelayTime" BO_ 2566803211 72;
BA_ "CI_MsgDefinition" BO_ 2566832622 "J1939DA";
BA_ "CI_MsgId" BO_ 2566832622 1533;
BA_ "CI_MsgName" BO_ 2566832622 "VDHR - High Resolution Vehicle Distance";
BA_ "GenMsgCycleTime" BO_ 2566832622 1000;
BA_ "GenMsgCycleTimeFast" BO_ 2566832622 1000;
BA_ "GenMsgDelayTime" BO_ 2566832622 500;
BA_ "GenMsgSendType" BO_ 2566832622 0;
BA_ "GenMsgStartDelayTime" BO_ 2566832622 185;
BA_ "CI_MsgDefinition" BO_ 2566832407 "J1939DA";
BA_ "CI_MsgId" BO_ 2566832407 1530;
BA_ "CI_MsgName" BO_ 2566832407 "VDHR_17 - High Resolution Vehicle Distance";
BA_ "GenMsgCycleTime" BO_ 2566832407 1000;
BA_ "GenMsgCycleTimeFast" BO_ 2566832407 1000;
BA_ "GenMsgDelayTime" BO_ 2566832407 500;
BA_ "GenMsgSendType" BO_ 2566832407 0;
BA_ "GenMsgStartDelayTime" BO_ 2566832407 184;
BA_ "CI_MsgDefinition" BO_ 2566842433 "J1939DA";
BA_ "CI_MsgId" BO_ 2566842433 9755;
BA_ "CI_MsgName" BO_ 2566842433 "VDS_41 - Vehicle Direction/Speed";
BA_ "GenMsgCycleTime" BO_ 2566842433 1000;
BA_ "GenMsgCycleTimeFast" BO_ 2566842433 1000;
BA_ "GenMsgDelayTime" BO_ 2566842433 500;
BA_ "GenMsgSendType" BO_ 2566842433 0;
BA_ "GenMsgStartDelayTime" BO_ 2566842433 233;
BA_ "CI_MsgDefinition" BO_ 2566842442 "J1939DA";
BA_ "CI_MsgId" BO_ 2566842442 9760;
BA_ "CI_MsgName" BO_ 2566842442 "VDS_4A - Vehicle Direction/Speed";
BA_ "GenMsgCycleTime" BO_ 2566842442 1000;
BA_ "GenMsgCycleTimeFast" BO_ 2566842442 1000;
BA_ "GenMsgDelayTime" BO_ 2566842442 500;
BA_ "GenMsgSendType" BO_ 2566842442 0;
BA_ "GenMsgStartDelayTime" BO_ 2566842442 14;
BA_ "CI_MsgDefinition" BO_ 2566752586 "J1939DA";
BA_ "CI_MsgId" BO_ 2566752586 9779;
BA_ "CI_MsgName" BO_ 2566752586 "VDS2_4A - Vehicle Direction/Speed 2";
BA_ "CI_MsgDefinition" BO_ 2566846208 "J1939DA";
BA_ "CI_MsgId" BO_ 2566846208 3531;
BA_ "CI_MsgName" BO_ 2566846208 "VEP1_00 - Vehicle Electrical Power 1";
BA_ "GenMsgCycleTime" BO_ 2566846208 1000;
BA_ "GenMsgCycleTimeFast" BO_ 2566846208 1000;
BA_ "GenMsgDelayTime" BO_ 2566846208 500;
BA_ "GenMsgSendType" BO_ 2566846208 0;
BA_ "GenMsgStartDelayTime" BO_ 2566846208 242;
BA_ "CI_MsgDefinition" BO_ 2566846241 "J1939DA";
BA_ "CI_MsgId" BO_ 2566846241 3545;
BA_ "CI_MsgName" BO_ 2566846241 "VEP1_21 - Vehicle Electrical Power 1";
BA_ "GenMsgCycleTime" BO_ 2566846241 1000;
BA_ "GenMsgCycleTimeFast" BO_ 2566846241 1000;
BA_ "GenMsgDelayTime" BO_ 2566846241 100;
BA_ "GenMsgSendType" BO_ 2566846241 0;
BA_ "GenMsgStartDelayTime" BO_ 2566846241 243;
BA_ "CI_MsgDefinition" BO_ 2566843392 "J1939DA";
BA_ "CI_MsgId" BO_ 2566843392 1642;
BA_ "CI_MsgName" BO_ 2566843392 "VI_00 - Vehicle Identification";
BA_ "GenMsgCycleTime" BO_ 2566843392 10000;
BA_ "GenMsgCycleTimeFast" BO_ 2566843392 10000;
BA_ "GenMsgDelayTime" BO_ 2566843392 5000;
BA_ "GenMsgSendType" BO_ 2566843392 0;
BA_ "GenMsgStartDelayTime" BO_ 2566843392 344;
BA_ "CI_MsgDefinition" BO_ 2566843466 "J1939DA";
BA_ "CI_MsgId" BO_ 2566843466 1653;
BA_ "CI_MsgName" BO_ 2566843466 "VI_4A - Vehicle Identification";
BA_ "CI_MsgDefinition" BO_ 2566843630 "J1939DA";
BA_ "CI_MsgId" BO_ 2566843630 1647;
BA_ "CI_MsgName" BO_ 2566843630 "VI_EE - Vehicle Identification";
BA_ "CI_MsgDefinition" BO_ 2566845249 "J1939DA";
BA_ "CI_MsgId" BO_ 2566845249 44798;
BA_ "CI_MsgName" BO_ 2566845249 "VP1_41 - Vehicle Position 1";
BA_ "GenMsgCycleTime" BO_ 2566845249 1000;
BA_ "GenMsgCycleTimeFast" BO_ 2566845249 1000;
BA_ "GenMsgDelayTime" BO_ 2566845249 500;
BA_ "GenMsgSendType" BO_ 2566845249 0;
BA_ "GenMsgStartDelayTime" BO_ 2566845249 237;
BA_ "CI_MsgDefinition" BO_ 2566845258 "J1939DA";
BA_ "CI_MsgId" BO_ 2566845258 9795;
BA_ "CI_MsgName" BO_ 2566845258 "VP1_4A - Vehicle Position 1";
BA_ "GenMsgCycleTime" BO_ 2566845258 1000;
BA_ "GenMsgCycleTimeFast" BO_ 2566845258 1000;
BA_ "GenMsgDelayTime" BO_ 2566845258 500;
BA_ "GenMsgSendType" BO_ 2566845258 0;
BA_ "GenMsgStartDelayTime" BO_ 2566845258 18;
BA_ "CI_MsgDefinition" BO_ 2566845422 "J1939DA";
BA_ "CI_MsgId" BO_ 2566845422 9801;
BA_ "CI_MsgName" BO_ 2566845422 "VP1_EE - Vehicle Position 1";
BA_ "GenMsgCycleTime" BO_ 2566845422 1000;
BA_ "GenMsgCycleTimeFast" BO_ 2566845422 1000;
BA_ "GenMsgDelayTime" BO_ 2566845422 500;
BA_ "GenMsgSendType" BO_ 2566845422 0;
BA_ "GenMsgStartDelayTime" BO_ 2566845422 238;
BA_ "CI_MsgDefinition" BO_ 2566649418 "J1939DA";
BA_ "CI_MsgId" BO_ 2566649418 9813;
BA_ "CI_MsgName" BO_ 2566649418 "VP2_4A - Vehicle Position 2";
BA_ "GenMsgCycleTime" BO_ 2566649418 5000;
BA_ "GenMsgCycleTimeFast" BO_ 2566649418 5000;
BA_ "GenMsgDelayTime" BO_ 2566649418 2500;
BA_ "GenMsgSendType" BO_ 2566649418 0;
BA_ "GenMsgStartDelayTime" BO_ 2566649418 38;
BA_ "CI_MsgDefinition" BO_ 2566842606 "J1939DA";
BA_ "CI_MsgId" BO_ 2566842606 50066;
BA_ "GenMsgCycleTime" BO_ 2566842606 1000;
BA_ "GenMsgCycleTimeFast" BO_ 2566842606 1000;
BA_ "GenMsgDelayTime" BO_ 2566842606 500;
BA_ "GenMsgSendType" BO_ 2566842606 0;
BA_ "GenMsgStartDelayTime" BO_ 2566842606 10;
BA_ "CI_MsgDefinition" BO_ 2348875082 "J1939DA";
BA_ "CI_MsgId" BO_ 2348875082 50001;
BA_ "GenMsgCycleTime" BO_ 2348875082 1000;
BA_ "GenMsgCycleTimeFast" BO_ 2348875082 1000;
BA_ "GenMsgDelayTime" BO_ 2348875082 50;
BA_ "GenMsgSendType" BO_ 2348875082 0;
BA_ "GenMsgStartDelayTime" BO_ 2348875082 86;
BA_ "CI_MsgDefinition" BO_ 2348874826 "J1939DA";
BA_ "CI_MsgId" BO_ 2348874826 50002;
BA_ "GenMsgCycleTime" BO_ 2348874826 1000;
BA_ "GenMsgCycleTimeFast" BO_ 2348874826 1000;
BA_ "GenMsgDelayTime" BO_ 2348874826 50;
BA_ "GenMsgSendType" BO_ 2348874826 0;
BA_ "GenMsgStartDelayTime" BO_ 2348874826 86;
BA_ "CI_MsgDefinition" BO_ 2348874570 "J1939DA";
BA_ "CI_MsgId" BO_ 2348874570 50003;
BA_ "GenMsgCycleTime" BO_ 2348874570 1000;
BA_ "GenMsgCycleTimeFast" BO_ 2348874570 1000;
BA_ "GenMsgDelayTime" BO_ 2348874570 50;
BA_ "GenMsgSendType" BO_ 2348874570 0;
BA_ "GenMsgStartDelayTime" BO_ 2348874570 86;
BA_ "CI_MsgDefinition" BO_ 2348874314 "J1939DA";
BA_ "CI_MsgId" BO_ 2348874314 50004;
BA_ "GenMsgCycleTime" BO_ 2348874314 1000;
BA_ "GenMsgCycleTimeFast" BO_ 2348874314 1000;
BA_ "GenMsgDelayTime" BO_ 2348874314 50;
BA_ "GenMsgSendType" BO_ 2348874314 0;
BA_ "GenMsgStartDelayTime" BO_ 2348874314 86;
BA_ "CI_MsgDefinition" BO_ 2348875594 "J1939DA";
BA_ "CI_MsgId" BO_ 2348875594 50005;
BA_ "GenMsgCycleTime" BO_ 2348875594 1000;
BA_ "GenMsgCycleTimeFast" BO_ 2348875594 1000;
BA_ "GenMsgDelayTime" BO_ 2348875594 50;
BA_ "GenMsgSendType" BO_ 2348875594 0;
BA_ "GenMsgStartDelayTime" BO_ 2348875594 86;
BA_ "CI_MsgDefinition" BO_ 2348871498 "J1939DA";
BA_ "CI_MsgId" BO_ 2348871498 50006;
BA_ "GenMsgCycleTime" BO_ 2348871498 1000;
BA_ "GenMsgCycleTimeFast" BO_ 2348871498 1000;
BA_ "GenMsgDelayTime" BO_ 2348871498 50;
BA_ "GenMsgSendType" BO_ 2348871498 0;
BA_ "GenMsgStartDelayTime" BO_ 2348871498 86;
BA_ "CI_MsgDefinition" BO_ 2348871242 "J1939DA";
BA_ "CI_MsgId" BO_ 2348871242 50007;
BA_ "GenMsgCycleTime" BO_ 2348871242 1000;
BA_ "GenMsgCycleTimeFast" BO_ 2348871242 1000;
BA_ "GenMsgDelayTime" BO_ 2348871242 50;
BA_ "GenMsgSendType" BO_ 2348871242 0;
BA_ "GenMsgStartDelayTime" BO_ 2348871242 86;
BA_ "CI_MsgId" BO_ 2561142090 50008;
BA_ "GenMsgSendType" BO_ 2561142090 0;
BA_ "CI_MsgId" BO_ 2561141834 50009;
BA_ "GenMsgSendType" BO_ 2561141834 0;
BA_ "CI_MsgId" BO_ 2561141578 50010;
BA_ "GenMsgSendType" BO_ 2561141578 0;
BA_ "CI_MsgId" BO_ 2561141322 50011;
BA_ "GenMsgSendType" BO_ 2561141322 0;
BA_ "CI_MsgId" BO_ 2561141066 50012;
BA_ "GenMsgSendType" BO_ 2561141066 0;
BA_ "CI_MsgId" BO_ 2561140810 50013;
BA_ "GenMsgSendType" BO_ 2561140810 0;
BA_ "CI_MsgId" BO_ 2561140554 50014;
BA_ "GenMsgSendType" BO_ 2561140554 0;
BA_ "CI_MsgId" BO_ 2561130314 50015;
BA_ "GenMsgSendType" BO_ 2561130314 0;
BA_ "CI_MsgId" BO_ 2561132874 50016;
BA_ "GenMsgSendType" BO_ 2561132874 0;
BA_ "CI_MsgId" BO_ 2561132618 50017;
BA_ "GenMsgSendType" BO_ 2561132618 0;
BA_ "CI_MsgId" BO_ 2561139786 50018;
BA_ "GenMsgSendType" BO_ 2561139786 0;
BA_ "CI_MsgId" BO_ 2561139530 50019;
BA_ "GenMsgSendType" BO_ 2561139530 0;
BA_ "CI_MsgId" BO_ 2561139274 50020;
BA_ "GenMsgSendType" BO_ 2561139274 0;
BA_ "CI_MsgId" BO_ 2561139018 50021;
BA_ "GenMsgSendType" BO_ 2561139018 0;
BA_ "CI_MsgId" BO_ 2561138762 50022;
BA_ "GenMsgSendType" BO_ 2561138762 0;
BA_ "CI_MsgId" BO_ 2561138506 50023;
BA_ "GenMsgSendType" BO_ 2561138506 0;
BA_ "CI_MsgId" BO_ 2561138250 50024;
BA_ "GenMsgSendType" BO_ 2561138250 0;
BA_ "CI_MsgId" BO_ 2561137994 50025;
BA_ "GenMsgSendType" BO_ 2561137994 0;
BA_ "CI_MsgId" BO_ 2561137738 50026;
BA_ "GenMsgSendType" BO_ 2561137738 0;
BA_ "CI_MsgId" BO_ 2561137482 50027;
BA_ "GenMsgSendType" BO_ 2561137482 0;
BA_ "CI_MsgId" BO_ 2561137226 50028;
BA_ "GenMsgSendType" BO_ 2561137226 0;
BA_ "CI_MsgId" BO_ 2561136970 50029;
BA_ "GenMsgSendType" BO_ 2561136970 0;
BA_ "CI_MsgId" BO_ 2561136714 50030;
BA_ "GenMsgSendType" BO_ 2561136714 0;
BA_ "CI_MsgId" BO_ 2561136458 50031;
BA_ "GenMsgSendType" BO_ 2561136458 0;
BA_ "CI_MsgId" BO_ 2561136202 50032;
BA_ "GenMsgSendType" BO_ 2561136202 0;
BA_ "CI_MsgId" BO_ 2561135946 50033;
BA_ "GenMsgSendType" BO_ 2561135946 0;
BA_ "CI_MsgId" BO_ 2561135690 50034;
BA_ "GenMsgSendType" BO_ 2561135690 0;
BA_ "CI_MsgId" BO_ 2561134922 50035;
BA_ "GenMsgSendType" BO_ 2561134922 0;
BA_ "CI_MsgId" BO_ 2561134666 50036;
BA_ "GenMsgSendType" BO_ 2561134666 0;
BA_ "CI_MsgId" BO_ 2561134410 50037;
BA_ "GenMsgSendType" BO_ 2561134410 0;
BA_ "CI_MsgId" BO_ 2561133386 50038;
BA_ "GenMsgSendType" BO_ 2561133386 0;
BA_ "CI_MsgId" BO_ 2561133130 50039;
BA_ "GenMsgSendType" BO_ 2561133130 0;
BA_ "CI_MsgId" BO_ 2561132362 50040;
BA_ "GenMsgSendType" BO_ 2561132362 0;
BA_ "CI_MsgId" BO_ 2561132106 50041;
BA_ "GenMsgSendType" BO_ 2561132106 0;
BA_ "CI_MsgId" BO_ 2561131594 50042;
BA_ "GenMsgSendType" BO_ 2561131594 0;
BA_ "CI_MsgId" BO_ 2561131338 50043;
BA_ "GenMsgSendType" BO_ 2561131338 0;
BA_ "CI_MsgId" BO_ 2561131082 50044;
BA_ "GenMsgSendType" BO_ 2561131082 0;
BA_ "CI_MsgId" BO_ 2561130826 50045;
BA_ "GenMsgSendType" BO_ 2561130826 0;
BA_ "CI_MsgId" BO_ 2561130570 50046;
BA_ "GenMsgSendType" BO_ 2561130570 0;
BA_ "CI_MsgId" BO_ 2561129802 50047;
BA_ "GenMsgSendType" BO_ 2561129802 0;
BA_ "CI_MsgId" BO_ 2561129290 50048;
BA_ "GenMsgSendType" BO_ 2561129290 0;
BA_ "CI_MsgId" BO_ 2561129034 50049;
BA_ "GenMsgSendType" BO_ 2561129034 0;
BA_ "CI_MsgId" BO_ 2561128778 50050;
BA_ "GenMsgSendType" BO_ 2561128778 0;
BA_ "CI_MsgId" BO_ 2561128522 50051;
BA_ "GenMsgSendType" BO_ 2561128522 0;
BA_ "CI_MsgId" BO_ 2561128266 50052;
BA_ "GenMsgSendType" BO_ 2561128266 0;
BA_ "CI_MsgId" BO_ 2561128010 50053;
BA_ "GenMsgSendType" BO_ 2561128010 0;
BA_ "CI_MsgId" BO_ 2561126986 50054;
BA_ "GenMsgSendType" BO_ 2561126986 0;
BA_ "CI_MsgId" BO_ 2561127754 50055;
BA_ "GenMsgSendType" BO_ 2561127754 0;
BA_ "CI_MsgId" BO_ 2561126730 50056;
BA_ "GenMsgSendType" BO_ 2561126730 0;
BA_ "CI_MsgId" BO_ 2561129546 50057;
BA_ "GenMsgSendType" BO_ 2561129546 0;
BA_ "CI_MsgId" BO_ 2561135434 50058;
BA_ "GenMsgSendType" BO_ 2561135434 0;
BA_ "CI_MsgId" BO_ 2561135178 50059;
BA_ "GenMsgSendType" BO_ 2561135178 0;
BA_ "CI_MsgId" BO_ 2561131850 50060;
BA_ "GenMsgSendType" BO_ 2561131850 0;
BA_ "CI_MsgId" BO_ 2561140298 50061;
BA_ "GenMsgSendType" BO_ 2561140298 0;
BA_ "CI_MsgId" BO_ 2561134154 50062;
BA_ "GenMsgSendType" BO_ 2561134154 0;
BA_ "CI_MsgId" BO_ 2561133898 50063;
BA_ "GenMsgSendType" BO_ 2561133898 0;
BA_ "CI_MsgId" BO_ 2561127498 50064;
BA_ "GenMsgSendType" BO_ 2561127498 0;
BA_ "CI_MsgId" BO_ 2561127242 50065;
BA_ "GenMsgSendType" BO_ 2561127242 0;
BA_ "CI_MsgId" BO_ 2566894154 50068;
BA_ "GenMsgCycleTime" BO_ 2566894154 1000;
BA_ "GenMsgSendType" BO_ 2566894154 0;
BA_ "CI_MsgDefinition" BO_ 2566896970 "Iveco Proprietary";
BA_ "CI_MsgId" BO_ 2566896970 50071;
BA_ "GenMsgCycleTime" BO_ 2566896970 1000;
BA_ "GenMsgCycleTimeFast" BO_ 2566896970 1000;
BA_ "GenMsgDelayTime" BO_ 2566896970 500;
BA_ "GenMsgSendType" BO_ 2566896970 0;
BA_ "GenMsgStartDelayTime" BO_ 2566896970 16;
BA_ "CI_MsgDefinition" BO_ 2566893898 "Iveco Proprietary";
BA_ "CI_MsgId" BO_ 2566893898 50072;
BA_ "GenMsgCycleTime" BO_ 2566893898 1000;
BA_ "GenMsgCycleTimeFast" BO_ 2566893898 1000;
BA_ "GenMsgDelayTime" BO_ 2566893898 500;
BA_ "GenMsgSendType" BO_ 2566893898 0;
BA_ "GenMsgStartDelayTime" BO_ 2566893898 16;
BA_ "CI_MsgDefinition" BO_ 2566895434 "Iveco Proprietary";
BA_ "CI_MsgId" BO_ 2566895434 50073;
BA_ "GenMsgCycleTime" BO_ 2566895434 1000;
BA_ "GenMsgCycleTimeFast" BO_ 2566895434 1000;
BA_ "GenMsgDelayTime" BO_ 2566895434 500;
BA_ "GenMsgSendType" BO_ 2566895434 0;
BA_ "GenMsgStartDelayTime" BO_ 2566895434 16;
BA_ "CI_MsgDefinition" BO_ 2566845491 "Wabco Proprietary";
BA_ "CI_MsgId" BO_ 2566845491 50074;
BA_ "GenMsgCycleTime" BO_ 2566845491 500;
BA_ "GenMsgCycleTimeFast" BO_ 2566845491 500;
BA_ "GenMsgDelayTime" BO_ 2566845491 250;
BA_ "GenMsgSendType" BO_ 2566845491 0;
BA_ "CI_MsgDefinition" BO_ 2565982748 "J1939-73";
BA_ "CI_MsgId" BO_ 2565982748 50333;
BA_ "GenMsgCycleTime" BO_ 2565982748 1000;
BA_ "GenMsgCycleTimeFast" BO_ 2565982748 1000;
BA_ "GenMsgDelayTime" BO_ 2565982748 100;
BA_ "GenMsgSendType" BO_ 2565982748 0;
BA_ "GenMsgStartDelayTime" BO_ 2565982748 186;
BA_ "TpJ1939VarDlc" BO_ 2565982748 1;
BA_ "CI_MsgDefinition" BO_ 2566845212 "J1939DA";
BA_ "CI_MsgId" BO_ 2566845212 50334;
BA_ "GenMsgCycleTime" BO_ 2566845212 1000;
BA_ "GenMsgCycleTimeFast" BO_ 2566845212 1000;
BA_ "GenMsgDelayTime" BO_ 2566845212 500;
BA_ "GenMsgSendType" BO_ 2566845212 0;
BA_ "GenMsgStartDelayTime" BO_ 2566845212 18;
BA_ "CI_ParId" SG_ 2251374793 TrailElConn "I090";
BA_ "CI_SigId" SG_ 2251374793 TrailElConn 42839;
BA_ "CI_SigName" SG_ 2251374793 TrailElConn "Trailer Electrically Connected";
BA_ "GenSigTimeoutTime_PCM" SG_ 2251374793 TrailElConn 500;
BA_ "SigType" SG_ 2251374793 TrailElConn 4;
BA_ "CI_ParId" SG_ 2251374793 TurnRightLight "ID2313";
BA_ "CI_SigId" SG_ 2251374793 TurnRightLight 42788;
BA_ "CI_SigName" SG_ 2251374793 TurnRightLight "Turn Right Lights";
BA_ "GenSigTimeoutTime_PCM" SG_ 2251374793 TurnRightLight 500;
BA_ "SigType" SG_ 2251374793 TurnRightLight 4;
BA_ "CI_ParId" SG_ 2251374793 TurnLeftLight "ID2312";
BA_ "CI_SigId" SG_ 2251374793 TurnLeftLight 42787;
BA_ "CI_SigName" SG_ 2251374793 TurnLeftLight "Turn Left Lights";
BA_ "GenSigTimeoutTime_PCM" SG_ 2251374793 TurnLeftLight 500;
BA_ "SigType" SG_ 2251374793 TurnLeftLight 4;
BA_ "CI_ParId" SG_ 2251374793 StopLight "ID2311";
BA_ "CI_SigId" SG_ 2251374793 StopLight 42786;
BA_ "CI_SigName" SG_ 2251374793 StopLight "Stop Lights";
BA_ "GenSigTimeoutTime_PCM" SG_ 2251374793 StopLight 500;
BA_ "SigType" SG_ 2251374793 StopLight 4;
BA_ "CI_ParId" SG_ 2251374793 GenTrailFault "ID0510";
BA_ "CI_SigId" SG_ 2251374793 GenTrailFault 42838;
BA_ "CI_SigName" SG_ 2251374793 GenTrailFault "Generic Trailer Fault";
BA_ "GenSigTimeoutTime_PCM" SG_ 2251374793 GenTrailFault 500;
BA_ "CI_ParId" SG_ 2251374793 RevGearLight "ID2310";
BA_ "CI_SigId" SG_ 2251374793 RevGearLight 42785;
BA_ "CI_SigName" SG_ 2251374793 RevGearLight "Reverse Gear Lights";
BA_ "GenSigTimeoutTime_PCM" SG_ 2251374793 RevGearLight 500;
BA_ "SigType" SG_ 2251374793 RevGearLight 4;
BA_ "CI_ParId" SG_ 2251374793 RearFogLight_140C9 "ID2309";
BA_ "CI_SigId" SG_ 2251374793 RearFogLight_140C9 42784;
BA_ "CI_SigName" SG_ 2251374793 RearFogLight_140C9 "Rear Fog Lights";
BA_ "GenSigTimeoutTime_PCM" SG_ 2251374793 RearFogLight_140C9 500;
BA_ "SigType" SG_ 2251374793 RearFogLight_140C9 4;
BA_ "CI_ParId" SG_ 2251374793 PosLight "ID2308";
BA_ "CI_SigId" SG_ 2251374793 PosLight 42783;
BA_ "CI_SigName" SG_ 2251374793 PosLight "Position Lights";
BA_ "GenSigTimeoutTime_PCM" SG_ 2251374793 PosLight 500;
BA_ "SigType" SG_ 2251374793 PosLight 4;
BA_ "CI_ParId" SG_ 2317131777 EngEcoMode "ID0226";
BA_ "CI_SigId" SG_ 2317131777 EngEcoMode 42629;
BA_ "CI_SigName" SG_ 2317131777 EngEcoMode "Engine ECO Mode";
BA_ "GenSigTimeoutTime_PCM" SG_ 2317131777 EngEcoMode 500;
BA_ "SigType" SG_ 2317131777 EngEcoMode 4;
BA_ "CI_ParId" SG_ 2317131777 EassSoCond "ID0141";
BA_ "CI_SigId" SG_ 2317131777 EassSoCond 29907;
BA_ "CI_SigName" SG_ 2317131777 EassSoCond "Stop and Start Shut-Off Condition";
BA_ "GenSigTimeoutTime_PCM" SG_ 2317131777 EassSoCond 500;
BA_ "CI_ParId" SG_ 2317131777 SamInfo "ID0372";
BA_ "CI_SigId" SG_ 2317131777 SamInfo 29908;
BA_ "CI_SigName" SG_ 2317131777 SamInfo "SAM Info";
BA_ "GenSigTimeoutTime_PCM" SG_ 2317131777 SamInfo 500;
BA_ "CI_ParId" SG_ 2317131777 EassSensPossFault "ID0366";
BA_ "CI_SigId" SG_ 2317131777 EassSensPossFault 29902;
BA_ "CI_SigName" SG_ 2317131777 EassSensPossFault "Stop and Start Sensor Possible Fault";
BA_ "GenSigTimeoutTime_PCM" SG_ 2317131777 EassSensPossFault 500;
BA_ "CI_ParId" SG_ 2317131777 EcmStartRelayDiagFdbk "ID0367";
BA_ "CI_SigId" SG_ 2317131777 EcmStartRelayDiagFdbk 29903;
BA_ "CI_SigName" SG_ 2317131777 EcmStartRelayDiagFdbk "ECM Start Relay Diagnostic Feedback";
BA_ "GenSigTimeoutTime_PCM" SG_ 2317131777 EcmStartRelayDiagFdbk 500;
BA_ "CI_ParId" SG_ 2317131777 BcmStartRelayDiagFdbk "ID0368";
BA_ "CI_SigId" SG_ 2317131777 BcmStartRelayDiagFdbk 29904;
BA_ "CI_SigName" SG_ 2317131777 BcmStartRelayDiagFdbk "BCM Start Relay Diagnostic Feedback";
BA_ "GenSigTimeoutTime_PCM" SG_ 2317131777 BcmStartRelayDiagFdbk 500;
BA_ "CI_ParId" SG_ 2317131777 EassEngSts "ID0369";
BA_ "CI_SigId" SG_ 2317131777 EassEngSts 29905;
BA_ "CI_SigName" SG_ 2317131777 EassEngSts "Stop and Start Engine Status";
BA_ "GenSigStartValue" SG_ 2317131777 EassEngSts 1;
BA_ "GenSigTimeoutTime_PCM" SG_ 2317131777 EassEngSts 500;
BA_ "SigType" SG_ 2317131777 EassEngSts 4;
BA_ "CI_ParId" SG_ 2317131777 EassFunctSts "ID0370";
BA_ "CI_SigId" SG_ 2317131777 EassFunctSts 29906;
BA_ "CI_SigName" SG_ 2317131777 EassFunctSts "Stop and Start Function Status";
BA_ "GenSigTimeoutTime_PCM" SG_ 2317131777 EassFunctSts 500;
BA_ "SigType" SG_ 2317131777 EassFunctSts 4;
BA_ "CI_ParId" SG_ 2317131777 GearShiftInd "ID0360";
BA_ "CI_SigId" SG_ 2317131777 GearShiftInd 29896;
BA_ "CI_SigName" SG_ 2317131777 GearShiftInd "Gear Shift Indication";
BA_ "GenSigTimeoutTime_PCM" SG_ 2317131777 GearShiftInd 500;
BA_ "SigType" SG_ 2317131777 GearShiftInd 4;
BA_ "CI_ParId" SG_ 2317131777 SuggGearGsi "ID0353";
BA_ "CI_SigId" SG_ 2317131777 SuggGearGsi 29889;
BA_ "CI_SigName" SG_ 2317131777 SuggGearGsi "Suggested Gear GSI";
BA_ "GenSigTimeoutTime_PCM" SG_ 2317131777 SuggGearGsi 500;
BA_ "CI_ParId" SG_ 2251374616 SensPosArea6Sts "ID0602";
BA_ "CI_SigId" SG_ 2251374616 SensPosArea6Sts 30360;
BA_ "CI_SigName" SG_ 2251374616 SensPosArea6Sts "Sensor Position Area 6 Status";
BA_ "GenSigSendType" SG_ 2251374616 SensPosArea6Sts 3;
BA_ "GenSigTimeoutTime_PCM" SG_ 2251374616 SensPosArea6Sts 1000;
BA_ "SigType" SG_ 2251374616 SensPosArea6Sts 4;
BA_ "CI_ParId" SG_ 2251374616 SensPosArea5Sts "ID0603";
BA_ "CI_SigId" SG_ 2251374616 SensPosArea5Sts 30361;
BA_ "CI_SigName" SG_ 2251374616 SensPosArea5Sts "Sensor Position Area 5 Status";
BA_ "GenSigSendType" SG_ 2251374616 SensPosArea5Sts 3;
BA_ "GenSigTimeoutTime_PCM" SG_ 2251374616 SensPosArea5Sts 1000;
BA_ "CI_ParId" SG_ 2251374616 PulsePerTimeStsRhr "ID0599";
BA_ "CI_SigId" SG_ 2251374616 PulsePerTimeStsRhr 30357;
BA_ "CI_SigName" SG_ 2251374616 PulsePerTimeStsRhr "Pulse Period Time Status, Right Hand Rear";
BA_ "GenSigSendType" SG_ 2251374616 PulsePerTimeStsRhr 3;
BA_ "GenSigTimeoutTime_PCM" SG_ 2251374616 PulsePerTimeStsRhr 1000;
BA_ "CI_ParId" SG_ 2251374616 SensPosArea4Sts "ID0600";
BA_ "CI_SigId" SG_ 2251374616 SensPosArea4Sts 30358;
BA_ "CI_SigName" SG_ 2251374616 SensPosArea4Sts "Sensor Position Area 4 Status";
BA_ "GenSigSendType" SG_ 2251374616 SensPosArea4Sts 3;
BA_ "GenSigTimeoutTime_PCM" SG_ 2251374616 SensPosArea4Sts 1000;
BA_ "SigType" SG_ 2251374616 SensPosArea4Sts 4;
BA_ "CI_ParId" SG_ 2251374616 PulsePerTimeStsLhr "ID0596";
BA_ "CI_SigId" SG_ 2251374616 PulsePerTimeStsLhr 30354;
BA_ "CI_SigName" SG_ 2251374616 PulsePerTimeStsLhr "Pulse Period Time Status, Left Hand Rear";
BA_ "GenSigSendType" SG_ 2251374616 PulsePerTimeStsLhr 3;
BA_ "GenSigTimeoutTime_PCM" SG_ 2251374616 PulsePerTimeStsLhr 1000;
BA_ "CI_ParId" SG_ 2251374616 NspBuzReqStsRhr "ID0584";
BA_ "CI_SigId" SG_ 2251374616 NspBuzReqStsRhr 30342;
BA_ "CI_SigName" SG_ 2251374616 NspBuzReqStsRhr "NSP Buzzer Request Status, Right Hand Rear";
BA_ "GenSigSendType" SG_ 2251374616 NspBuzReqStsRhr 3;
BA_ "GenSigTimeoutTime_PCM" SG_ 2251374616 NspBuzReqStsRhr 1000;
BA_ "CI_ParId" SG_ 2251374616 NspBuzReqStsLhr "ID0585";
BA_ "CI_SigId" SG_ 2251374616 NspBuzReqStsLhr 30343;
BA_ "CI_SigName" SG_ 2251374616 NspBuzReqStsLhr "NSP Buzzer Request Status, Left Hand Rear";
BA_ "GenSigSendType" SG_ 2251374616 NspBuzReqStsLhr 3;
BA_ "GenSigTimeoutTime_PCM" SG_ 2251374616 NspBuzReqStsLhr 1000;
BA_ "CI_ParId" SG_ 2251374616 NspFail "ID0588";
BA_ "CI_SigId" SG_ 2251374616 NspFail 30346;
BA_ "CI_SigName" SG_ 2251374616 NspFail "NSP Fail Status";
BA_ "GenSigSendType" SG_ 2251374616 NspFail 3;
BA_ "GenSigTimeoutTime_PCM" SG_ 2251374616 NspFail 1000;
BA_ "SigType" SG_ 2251374616 NspFail 4;
BA_ "CI_ParId" SG_ 2251374616 NspCtrlSts "ID0589";
BA_ "CI_SigId" SG_ 2251374616 NspCtrlSts 42147;
BA_ "CI_SigName" SG_ 2251374616 NspCtrlSts "NSP Control Status";
BA_ "GenSigSendType" SG_ 2251374616 NspCtrlSts 3;
BA_ "GenSigStartValue" SG_ 2251374616 NspCtrlSts 3;
BA_ "GenSigTimeoutTime_PCM" SG_ 2251374616 NspCtrlSts 1000;
BA_ "SigType" SG_ 2251374616 NspCtrlSts 4;
BA_ "CI_ParId" SG_ 2348885874 TransmMode8 "4249";
BA_ "CI_SigId" SG_ 2348885874 TransmMode8 1239;
BA_ "CI_SigName" SG_ 2348885874 TransmMode8 "Transmission Mode 8";
BA_ "GenSigTimeoutTime_PCM" SG_ 2348885874 TransmMode8 500;
BA_ "SPN" SG_ 2348885874 TransmMode8 4249;
BA_ "SigType" SG_ 2348885874 TransmMode8 4;
BA_ "CI_ParId" SG_ 2348885874 TransmMode7 "4248";
BA_ "CI_SigId" SG_ 2348885874 TransmMode7 1238;
BA_ "CI_SigName" SG_ 2348885874 TransmMode7 "Transmission Mode 7";
BA_ "GenSigTimeoutTime_PCM" SG_ 2348885874 TransmMode7 500;
BA_ "SPN" SG_ 2348885874 TransmMode7 4248;
BA_ "SigType" SG_ 2348885874 TransmMode7 4;
BA_ "CI_ParId" SG_ 2348885874 TransmMode6 "4247";
BA_ "CI_SigId" SG_ 2348885874 TransmMode6 1237;
BA_ "CI_SigName" SG_ 2348885874 TransmMode6 "Transmission Mode 6";
BA_ "GenSigTimeoutTime_PCM" SG_ 2348885874 TransmMode6 500;
BA_ "SPN" SG_ 2348885874 TransmMode6 4247;
BA_ "SigType" SG_ 2348885874 TransmMode6 4;
BA_ "CI_ParId" SG_ 2348885874 TransmMode5 "4246";
BA_ "CI_SigId" SG_ 2348885874 TransmMode5 1236;
BA_ "CI_SigName" SG_ 2348885874 TransmMode5 "Transmission Mode 5";
BA_ "GenSigTimeoutTime_PCM" SG_ 2348885874 TransmMode5 500;
BA_ "SPN" SG_ 2348885874 TransmMode5 4246;
BA_ "SigType" SG_ 2348885874 TransmMode5 4;
BA_ "CI_ParId" SG_ 2348885874 TransmShiftSelDisModeSw "2985";
BA_ "CI_SigId" SG_ 2348885874 TransmShiftSelDisModeSw 1235;
BA_ "CI_SigName" SG_ 2348885874 TransmShiftSelDisModeSw "Transmission Shift Selector Display Mode Switch";
BA_ "GenSigTimeoutTime_PCM" SG_ 2348885874 TransmShiftSelDisModeSw 500;
BA_ "SPN" SG_ 2348885874 TransmShiftSelDisModeSw 2985;
BA_ "SigType" SG_ 2348885874 TransmShiftSelDisModeSw 4;
BA_ "CI_ParId" SG_ 2348885874 TransmReqLaunchGear "4255";
BA_ "CI_SigId" SG_ 2348885874 TransmReqLaunchGear 1234;
BA_ "CI_SigName" SG_ 2348885874 TransmReqLaunchGear "Transmission Requested Launch Gear";
BA_ "GenSigTimeoutTime_PCM" SG_ 2348885874 TransmReqLaunchGear 500;
BA_ "SPN" SG_ 2348885874 TransmReqLaunchGear 4255;
BA_ "CI_ParId" SG_ 2348885874 TransmMode4 "1855";
BA_ "CI_SigId" SG_ 2348885874 TransmMode4 1233;
BA_ "CI_SigName" SG_ 2348885874 TransmMode4 "Transmission Mode 4";
BA_ "GenSigTimeoutTime_PCM" SG_ 2348885874 TransmMode4 500;
BA_ "SPN" SG_ 2348885874 TransmMode4 1855;
BA_ "SigType" SG_ 2348885874 TransmMode4 4;
BA_ "CI_ParId" SG_ 2348885874 TransmMode3 "1854";
BA_ "CI_SigId" SG_ 2348885874 TransmMode3 1232;
BA_ "CI_SigName" SG_ 2348885874 TransmMode3 "Transmission Mode 3";
BA_ "GenSigTimeoutTime_PCM" SG_ 2348885874 TransmMode3 500;
BA_ "SPN" SG_ 2348885874 TransmMode3 1854;
BA_ "SigType" SG_ 2348885874 TransmMode3 4;
BA_ "CI_ParId" SG_ 2348885874 TransmMode2 "1853";
BA_ "CI_SigId" SG_ 2348885874 TransmMode2 1231;
BA_ "CI_SigName" SG_ 2348885874 TransmMode2 "Transmission Mode 2";
BA_ "GenSigTimeoutTime_PCM" SG_ 2348885874 TransmMode2 500;
BA_ "SPN" SG_ 2348885874 TransmMode2 1853;
BA_ "SigType" SG_ 2348885874 TransmMode2 4;
BA_ "CI_ParId" SG_ 2348885874 TransmMode1 "1852";
BA_ "CI_SigId" SG_ 2348885874 TransmMode1 1230;
BA_ "CI_SigName" SG_ 2348885874 TransmMode1 "Transmission Mode 1";
BA_ "GenSigTimeoutTime_PCM" SG_ 2348885874 TransmMode1 500;
BA_ "SPN" SG_ 2348885874 TransmMode1 1852;
BA_ "SigType" SG_ 2348885874 TransmMode1 4;
BA_ "CI_ParId" SG_ 2348885874 DisengDiffLckReqCentRear "691";
BA_ "CI_SigId" SG_ 2348885874 DisengDiffLckReqCentRear 1228;
BA_ "CI_SigName" SG_ 2348885874 DisengDiffLckReqCentRear "Disengage Differential Lock Request - Central Rear";
BA_ "GenSigTimeoutTime_PCM" SG_ 2348885874 DisengDiffLckReqCentRear 500;
BA_ "SPN" SG_ 2348885874 DisengDiffLckReqCentRear 691;
BA_ "SigType" SG_ 2348885874 DisengDiffLckReqCentRear 4;
BA_ "CI_ParId" SG_ 2348885874 DisengDiffLckReqCentFront "690";
BA_ "CI_SigId" SG_ 2348885874 DisengDiffLckReqCentFront 1227;
BA_ "CI_SigName" SG_ 2348885874 DisengDiffLckReqCentFront "Disengage Differential Lock Request - Central Front";
BA_ "GenSigTimeoutTime_PCM" SG_ 2348885874 DisengDiffLckReqCentFront 500;
BA_ "SPN" SG_ 2348885874 DisengDiffLckReqCentFront 690;
BA_ "SigType" SG_ 2348885874 DisengDiffLckReqCentFront 4;
BA_ "CI_ParId" SG_ 2348885874 DisengDiffLckReqCent "689";
BA_ "CI_SigId" SG_ 2348885874 DisengDiffLckReqCent 1226;
BA_ "CI_SigName" SG_ 2348885874 DisengDiffLckReqCent "Disengage Differential Lock Request - Central";
BA_ "GenSigTimeoutTime_PCM" SG_ 2348885874 DisengDiffLckReqCent 500;
BA_ "SPN" SG_ 2348885874 DisengDiffLckReqCent 689;
BA_ "SigType" SG_ 2348885874 DisengDiffLckReqCent 4;
BA_ "CI_ParId" SG_ 2348885874 DisengDiffLckReqRa2 "688";
BA_ "CI_SigId" SG_ 2348885874 DisengDiffLckReqRa2 1225;
BA_ "CI_SigName" SG_ 2348885874 DisengDiffLckReqRa2 "Disengage Differential Lock Request - Rear Axle 2";
BA_ "GenSigTimeoutTime_PCM" SG_ 2348885874 DisengDiffLckReqRa2 500;
BA_ "SPN" SG_ 2348885874 DisengDiffLckReqRa2 688;
BA_ "SigType" SG_ 2348885874 DisengDiffLckReqRa2 4;
BA_ "CI_ParId" SG_ 2348885874 DisengDiffLckReqRa1 "687";
BA_ "CI_SigId" SG_ 2348885874 DisengDiffLckReqRa1 1224;
BA_ "CI_SigName" SG_ 2348885874 DisengDiffLckReqRa1 "Disengage Differential Lock Request - Rear Axle 1";
BA_ "GenSigTimeoutTime_PCM" SG_ 2348885874 DisengDiffLckReqRa1 500;
BA_ "SPN" SG_ 2348885874 DisengDiffLckReqRa1 687;
BA_ "SigType" SG_ 2348885874 DisengDiffLckReqRa1 4;
BA_ "CI_ParId" SG_ 2348885874 DisengDiffLckReqFa2 "686";
BA_ "CI_SigId" SG_ 2348885874 DisengDiffLckReqFa2 1223;
BA_ "CI_SigName" SG_ 2348885874 DisengDiffLckReqFa2 "Disengage Differential Lock Request - Front Axle 2";
BA_ "GenSigTimeoutTime_PCM" SG_ 2348885874 DisengDiffLckReqFa2 500;
BA_ "SPN" SG_ 2348885874 DisengDiffLckReqFa2 686;
BA_ "SigType" SG_ 2348885874 DisengDiffLckReqFa2 4;
BA_ "CI_ParId" SG_ 2348885874 DisengDiffLckReqFa1 "685";
BA_ "CI_SigId" SG_ 2348885874 DisengDiffLckReqFa1 1222;
BA_ "CI_SigName" SG_ 2348885874 DisengDiffLckReqFa1 "Disengage Differential Lock Request - Front Axle 1";
BA_ "GenSigTimeoutTime_PCM" SG_ 2348885874 DisengDiffLckReqFa1 500;
BA_ "SPN" SG_ 2348885874 DisengDiffLckReqFa1 685;
BA_ "SigType" SG_ 2348885874 DisengDiffLckReqFa1 4;
BA_ "CI_ParId" SG_ 2348885874 TransmReqGear "525";
BA_ "CI_SigId" SG_ 2348885874 TransmReqGear 1221;
BA_ "CI_SigName" SG_ 2348885874 TransmReqGear "Transmission Requested Gear";
BA_ "GenSigTimeoutTime_PCM" SG_ 2348885874 TransmReqGear 500;
BA_ "SPN" SG_ 2348885874 TransmReqGear 525;
BA_ "SigType" SG_ 2348885874 TransmReqGear 1;
BA_ "CI_ParId" SG_ 2348885874 ReqPcCltSlip "684";
BA_ "CI_SigId" SG_ 2348885874 ReqPcCltSlip 1220;
BA_ "CI_SigName" SG_ 2348885874 ReqPcCltSlip "Requested Percent Clutch Slip";
BA_ "GenSigTimeoutTime_PCM" SG_ 2348885874 ReqPcCltSlip 500;
BA_ "SPN" SG_ 2348885874 ReqPcCltSlip 684;
BA_ "SigType" SG_ 2348885874 ReqPcCltSlip 1;
BA_ "CI_ParId" SG_ 2348885874 TransmRevGearShiftInhReq "4242";
BA_ "CI_SigId" SG_ 2348885874 TransmRevGearShiftInhReq 1219;
BA_ "CI_SigName" SG_ 2348885874 TransmRevGearShiftInhReq "Transmission Reverse Gear Shift Inhibit Request";
BA_ "GenSigTimeoutTime_PCM" SG_ 2348885874 TransmRevGearShiftInhReq 500;
BA_ "SPN" SG_ 2348885874 TransmRevGearShiftInhReq 4242;
BA_ "SigType" SG_ 2348885874 TransmRevGearShiftInhReq 4;
BA_ "CI_ParId" SG_ 2348885874 DisengDrvlReq "683";
BA_ "CI_SigId" SG_ 2348885874 DisengDrvlReq 1218;
BA_ "CI_SigName" SG_ 2348885874 DisengDrvlReq "Disengage Driveline Request";
BA_ "GenSigTimeoutTime_PCM" SG_ 2348885874 DisengDrvlReq 500;
BA_ "SPN" SG_ 2348885874 DisengDrvlReq 683;
BA_ "SigType" SG_ 2348885874 DisengDrvlReq 4;
BA_ "CI_ParId" SG_ 2348885874 TransmTrqConvLckReq "682";
BA_ "CI_SigId" SG_ 2348885874 TransmTrqConvLckReq 1217;
BA_ "CI_SigName" SG_ 2348885874 TransmTrqConvLckReq "Transmission Torque Converter Lockup Request";
BA_ "GenSigTimeoutTime_PCM" SG_ 2348885874 TransmTrqConvLckReq 500;
BA_ "SPN" SG_ 2348885874 TransmTrqConvLckReq 682;
BA_ "SigType" SG_ 2348885874 TransmTrqConvLckReq 4;
BA_ "CI_ParId" SG_ 2348885874 TransmGearShiftInhReq "681";
BA_ "CI_SigId" SG_ 2348885874 TransmGearShiftInhReq 1216;
BA_ "CI_SigName" SG_ 2348885874 TransmGearShiftInhReq "Transmission Gear Shift Inhibit Request";
BA_ "GenSigTimeoutTime_PCM" SG_ 2348885874 TransmGearShiftInhReq 500;
BA_ "SPN" SG_ 2348885874 TransmGearShiftInhReq 681;
BA_ "SigType" SG_ 2348885874 TransmGearShiftInhReq 4;
BA_ "CI_ParId" SG_ 2566840835 TransmGr9 "581";
BA_ "CI_SigId" SG_ 2566840835 TransmGr9 1439;
BA_ "CI_SigName" SG_ 2566840835 TransmGr9 "Transmission Gear Ratio 9";
BA_ "SPN" SG_ 2566840835 TransmGr9 581;
BA_ "CI_ParId" SG_ 2566840835 TransmGr8 "581";
BA_ "CI_SigId" SG_ 2566840835 TransmGr8 1438;
BA_ "CI_SigName" SG_ 2566840835 TransmGr8 "Transmission Gear Ratio 8";
BA_ "SPN" SG_ 2566840835 TransmGr8 581;
BA_ "CI_ParId" SG_ 2566840835 TransmGr7 "581";
BA_ "CI_SigId" SG_ 2566840835 TransmGr7 1437;
BA_ "CI_SigName" SG_ 2566840835 TransmGr7 "Transmission Gear Ratio 7";
BA_ "SPN" SG_ 2566840835 TransmGr7 581;
BA_ "CI_ParId" SG_ 2566840835 TransmGr6 "581";
BA_ "CI_SigId" SG_ 2566840835 TransmGr6 1436;
BA_ "CI_SigName" SG_ 2566840835 TransmGr6 "Transmission Gear Ratio 6";
BA_ "SPN" SG_ 2566840835 TransmGr6 581;
BA_ "CI_ParId" SG_ 2566840835 TransmGr5 "581";
BA_ "CI_SigId" SG_ 2566840835 TransmGr5 1435;
BA_ "CI_SigName" SG_ 2566840835 TransmGr5 "Transmission Gear Ratio 5";
BA_ "SPN" SG_ 2566840835 TransmGr5 581;
BA_ "CI_ParId" SG_ 2566840835 TransmGr4 "581";
BA_ "CI_SigId" SG_ 2566840835 TransmGr4 1434;
BA_ "CI_SigName" SG_ 2566840835 TransmGr4 "Transmission Gear Ratio 4";
BA_ "SPN" SG_ 2566840835 TransmGr4 581;
BA_ "CI_ParId" SG_ 2566840835 TransmGr3 "581";
BA_ "CI_SigId" SG_ 2566840835 TransmGr3 1433;
BA_ "CI_SigName" SG_ 2566840835 TransmGr3 "Transmission Gear Ratio 3";
BA_ "SPN" SG_ 2566840835 TransmGr3 581;
BA_ "CI_ParId" SG_ 2566840835 TransmGr2 "581";
BA_ "CI_SigId" SG_ 2566840835 TransmGr2 1432;
BA_ "CI_SigName" SG_ 2566840835 TransmGr2 "Transmission Gear Ratio 2";
BA_ "SPN" SG_ 2566840835 TransmGr2 581;
BA_ "CI_ParId" SG_ 2566840835 TransmGr1 "581";
BA_ "CI_SigId" SG_ 2566840835 TransmGr1 1431;
BA_ "CI_SigName" SG_ 2566840835 TransmGr1 "Transmission Gear Ratio 1";
BA_ "SPN" SG_ 2566840835 TransmGr1 581;
BA_ "CI_ParId" SG_ 2566840835 NumOfFwGrs "957";
BA_ "CI_SigId" SG_ 2566840835 NumOfFwGrs 1430;
BA_ "CI_SigName" SG_ 2566840835 NumOfFwGrs "Number of Forward Gear Ratios";
BA_ "SPN" SG_ 2566840835 NumOfFwGrs 957;
BA_ "SigType" SG_ 2566840835 NumOfFwGrs 1;
BA_ "CI_ParId" SG_ 2566840835 NumOfRevGrs "958";
BA_ "CI_SigId" SG_ 2566840835 NumOfRevGrs 1429;
BA_ "CI_SigName" SG_ 2566840835 NumOfRevGrs "Number of Reverse Gear Ratios";
BA_ "SPN" SG_ 2566840835 NumOfRevGrs 958;
BA_ "SigType" SG_ 2566840835 NumOfRevGrs 1;
BA_ "CI_ParId" SG_ 2566750979 TcSts "3645";
BA_ "CI_SigId" SG_ 2566750979 TcSts 1411;
BA_ "CI_SigName" SG_ 2566750979 TcSts "Transfer case status";
BA_ "GenSigSendType" SG_ 2566750979 TcSts 3;
BA_ "GenSigTimeoutTime_PCM" SG_ 2566750979 TcSts 5000;
BA_ "SPN" SG_ 2566750979 TcSts 3645;
BA_ "CI_ParId" SG_ 2566751205 TcSts_FD83E5 "3645";
BA_ "CI_SigId" SG_ 2566751205 TcSts_FD83E5 1414;
BA_ "CI_SigName" SG_ 2566751205 TcSts_FD83E5 "Transfer case status";
BA_ "GenSigSendType" SG_ 2566751205 TcSts_FD83E5 3;
BA_ "GenSigTimeoutTime_PCM" SG_ 2566751205 TcSts_FD83E5 5000;
BA_ "SPN" SG_ 2566751205 TcSts_FD83E5 3645;
BA_ "CI_ParId" SG_ 2365484270 TcoVehSpeed "1624";
BA_ "CI_SigId" SG_ 2365484270 TcoVehSpeed 1526;
BA_ "CI_SigName" SG_ 2365484270 TcoVehSpeed "Tachograph vehicle speed";
BA_ "GenSigTimeoutTime_PCM" SG_ 2365484270 TcoVehSpeed 500;
BA_ "SPN" SG_ 2365484270 TcoVehSpeed 1624;
BA_ "SigType" SG_ 2365484270 TcoVehSpeed 1;
BA_ "CI_ParId" SG_ 2365484270 TcoOutSpeed "1623";
BA_ "CI_SigId" SG_ 2365484270 TcoOutSpeed 1525;
BA_ "CI_SigName" SG_ 2365484270 TcoOutSpeed "Tachograph output shaft speed";
BA_ "GenSigTimeoutTime_PCM" SG_ 2365484270 TcoOutSpeed 500;
BA_ "SPN" SG_ 2365484270 TcoOutSpeed 1623;
BA_ "SigType" SG_ 2365484270 TcoOutSpeed 1;
BA_ "CI_ParId" SG_ 2365484270 TcoPerf "1620";
BA_ "CI_SigId" SG_ 2365484270 TcoPerf 1523;
BA_ "CI_SigName" SG_ 2365484270 TcoPerf "Tachograph performance";
BA_ "GenSigTimeoutTime_PCM" SG_ 2365484270 TcoPerf 500;
BA_ "SPN" SG_ 2365484270 TcoPerf 1620;
BA_ "SigType" SG_ 2365484270 TcoPerf 4;
BA_ "CI_ParId" SG_ 2365484270 HandInfo "1621";
BA_ "CI_SigId" SG_ 2365484270 HandInfo 1522;
BA_ "CI_SigName" SG_ 2365484270 HandInfo "Handling information";
BA_ "GenSigTimeoutTime_PCM" SG_ 2365484270 HandInfo 500;
BA_ "SPN" SG_ 2365484270 HandInfo 1621;
BA_ "SigType" SG_ 2365484270 HandInfo 4;
BA_ "CI_ParId" SG_ 2365484270 SysEvt "1622";
BA_ "CI_SigId" SG_ 2365484270 SysEvt 1521;
BA_ "CI_SigName" SG_ 2365484270 SysEvt "System event";
BA_ "GenSigTimeoutTime_PCM" SG_ 2365484270 SysEvt 500;
BA_ "SPN" SG_ 2365484270 SysEvt 1622;
BA_ "SigType" SG_ 2365484270 SysEvt 4;
BA_ "CI_ParId" SG_ 2365484270 DrivCardDriv2 "1616";
BA_ "CI_SigId" SG_ 2365484270 DrivCardDriv2 1519;
BA_ "CI_SigName" SG_ 2365484270 DrivCardDriv2 "Driver card, driver 2";
BA_ "GenSigTimeoutTime_PCM" SG_ 2365484270 DrivCardDriv2 500;
BA_ "SPN" SG_ 2365484270 DrivCardDriv2 1616;
BA_ "SigType" SG_ 2365484270 DrivCardDriv2 4;
BA_ "CI_ParId" SG_ 2365484270 Driv2TimeRelSts "1618";
BA_ "CI_SigId" SG_ 2365484270 Driv2TimeRelSts 1518;
BA_ "CI_SigName" SG_ 2365484270 Driv2TimeRelSts "Driver 2 Time Related States";
BA_ "GenSigTimeoutTime_PCM" SG_ 2365484270 Driv2TimeRelSts 500;
BA_ "SPN" SG_ 2365484270 Driv2TimeRelSts 1618;
BA_ "CI_ParId" SG_ 2365484270 VehOverspeed "1614";
BA_ "CI_SigId" SG_ 2365484270 VehOverspeed 1517;
BA_ "CI_SigName" SG_ 2365484270 VehOverspeed "Vehicle Overspeed";
BA_ "GenSigTimeoutTime_PCM" SG_ 2365484270 VehOverspeed 500;
BA_ "SPN" SG_ 2365484270 VehOverspeed 1614;
BA_ "SigType" SG_ 2365484270 VehOverspeed 4;
BA_ "CI_ParId" SG_ 2365484270 DrivCardDriv1 "1615";
BA_ "CI_SigId" SG_ 2365484270 DrivCardDriv1 1516;
BA_ "CI_SigName" SG_ 2365484270 DrivCardDriv1 "Driver card, driver 1";
BA_ "GenSigTimeoutTime_PCM" SG_ 2365484270 DrivCardDriv1 500;
BA_ "SPN" SG_ 2365484270 DrivCardDriv1 1615;
BA_ "SigType" SG_ 2365484270 DrivCardDriv1 4;
BA_ "CI_ParId" SG_ 2365484270 Driv1TimeRelSts "1617";
BA_ "CI_SigId" SG_ 2365484270 Driv1TimeRelSts 1515;
BA_ "CI_SigName" SG_ 2365484270 Driv1TimeRelSts "Driver 1 Time Related States";
BA_ "GenSigTimeoutTime_PCM" SG_ 2365484270 Driv1TimeRelSts 500;
BA_ "SPN" SG_ 2365484270 Driv1TimeRelSts 1617;
BA_ "CI_ParId" SG_ 2365484270 VehMot "1611";
BA_ "CI_SigId" SG_ 2365484270 VehMot 1514;
BA_ "CI_SigName" SG_ 2365484270 VehMot "Vehicle motion";
BA_ "GenSigTimeoutTime_PCM" SG_ 2365484270 VehMot 500;
BA_ "SPN" SG_ 2365484270 VehMot 1611;
BA_ "SigType" SG_ 2365484270 VehMot 4;
BA_ "CI_ParId" SG_ 2365484270 Driv2WorkSts "1613";
BA_ "CI_SigId" SG_ 2365484270 Driv2WorkSts 1513;
BA_ "CI_SigName" SG_ 2365484270 Driv2WorkSts "Driver 2 working state";
BA_ "GenSigTimeoutTime_PCM" SG_ 2365484270 Driv2WorkSts 500;
BA_ "SPN" SG_ 2365484270 Driv2WorkSts 1613;
BA_ "CI_ParId" SG_ 2365484270 Driv1WorkSts "1612";
BA_ "CI_SigId" SG_ 2365484270 Driv1WorkSts 1512;
BA_ "CI_SigName" SG_ 2365484270 Driv1WorkSts "Driver 1 working state";
BA_ "GenSigTimeoutTime_PCM" SG_ 2365484270 Driv1WorkSts 500;
BA_ "SPN" SG_ 2365484270 Driv1WorkSts 1612;
BA_ "CI_ParId" SG_ 2566842094 LocalHrOfs "1602";
BA_ "CI_SigId" SG_ 2566842094 LocalHrOfs 1597;
BA_ "CI_SigName" SG_ 2566842094 LocalHrOfs "Local hour offset";
BA_ "GenSigStartValue" SG_ 2566842094 LocalHrOfs 255;
BA_ "GenSigTimeoutTime_PCM" SG_ 2566842094 LocalHrOfs 5000;
BA_ "SPN" SG_ 2566842094 LocalHrOfs 1602;
BA_ "SigType" SG_ 2566842094 LocalHrOfs 1;
BA_ "CI_ParId" SG_ 2566842094 LocalMinOfs "1601";
BA_ "CI_SigId" SG_ 2566842094 LocalMinOfs 1596;
BA_ "CI_SigName" SG_ 2566842094 LocalMinOfs "Local minute offset";
BA_ "GenSigStartValue" SG_ 2566842094 LocalMinOfs 255;
BA_ "GenSigTimeoutTime_PCM" SG_ 2566842094 LocalMinOfs 5000;
BA_ "SPN" SG_ 2566842094 LocalMinOfs 1601;
BA_ "SigType" SG_ 2566842094 LocalMinOfs 1;
BA_ "CI_ParId" SG_ 2566842094 Yr "964";
BA_ "CI_SigId" SG_ 2566842094 Yr 1595;
BA_ "CI_SigName" SG_ 2566842094 Yr "Year";
BA_ "GenSigStartValue" SG_ 2566842094 Yr 255;
BA_ "GenSigTimeoutTime_PCM" SG_ 2566842094 Yr 5000;
BA_ "SPN" SG_ 2566842094 Yr 964;
BA_ "SigType" SG_ 2566842094 Yr 1;
BA_ "CI_ParId" SG_ 2566842094 Day "962";
BA_ "CI_SigId" SG_ 2566842094 Day 1594;
BA_ "CI_SigName" SG_ 2566842094 Day "Day";
BA_ "GenSigStartValue" SG_ 2566842094 Day 255;
BA_ "GenSigTimeoutTime_PCM" SG_ 2566842094 Day 5000;
BA_ "SPN" SG_ 2566842094 Day 962;
BA_ "SigType" SG_ 2566842094 Day 1;
BA_ "CI_ParId" SG_ 2566842094 Month "963";
BA_ "CI_SigId" SG_ 2566842094 Month 1593;
BA_ "CI_SigName" SG_ 2566842094 Month "Month";
BA_ "GenSigStartValue" SG_ 2566842094 Month 255;
BA_ "GenSigTimeoutTime_PCM" SG_ 2566842094 Month 5000;
BA_ "SPN" SG_ 2566842094 Month 963;
BA_ "SigType" SG_ 2566842094 Month 1;
BA_ "CI_ParId" SG_ 2566842094 Hr "961";
BA_ "CI_SigId" SG_ 2566842094 Hr 1592;
BA_ "CI_SigName" SG_ 2566842094 Hr "Hours";
BA_ "GenSigStartValue" SG_ 2566842094 Hr 255;
BA_ "GenSigTimeoutTime_PCM" SG_ 2566842094 Hr 5000;
BA_ "SPN" SG_ 2566842094 Hr 961;
BA_ "SigType" SG_ 2566842094 Hr 1;
BA_ "CI_ParId" SG_ 2566842094 Min "960";
BA_ "CI_SigId" SG_ 2566842094 Min 1591;
BA_ "CI_SigName" SG_ 2566842094 Min "Minutes";
BA_ "GenSigStartValue" SG_ 2566842094 Min 255;
BA_ "GenSigTimeoutTime_PCM" SG_ 2566842094 Min 5000;
BA_ "SPN" SG_ 2566842094 Min 960;
BA_ "SigType" SG_ 2566842094 Min 1;
BA_ "CI_ParId" SG_ 2566842094 Sec "959";
BA_ "CI_SigId" SG_ 2566842094 Sec 1590;
BA_ "CI_SigName" SG_ 2566842094 Sec "Seconds";
BA_ "GenSigStartValue" SG_ 2566842094 Sec 255;
BA_ "GenSigTimeoutTime_PCM" SG_ 2566842094 Sec 5000;
BA_ "SPN" SG_ 2566842094 Sec 959;
BA_ "SigType" SG_ 2566842094 Sec 1;
BA_ "CI_ParId" SG_ 2566841921 LocalHrOfs_FEE641 "1602";
BA_ "CI_SigId" SG_ 2566841921 LocalHrOfs_FEE641 1570;
BA_ "CI_SigName" SG_ 2566841921 LocalHrOfs_FEE641 "Local hour offset";
BA_ "GenSigStartValue" SG_ 2566841921 LocalHrOfs_FEE641 255;
BA_ "GenSigTimeoutTime_PCM" SG_ 2566841921 LocalHrOfs_FEE641 5000;
BA_ "SPN" SG_ 2566841921 LocalHrOfs_FEE641 1602;
BA_ "SigType" SG_ 2566841921 LocalHrOfs_FEE641 1;
BA_ "CI_ParId" SG_ 2566841921 LocalMinOfs_FEE641 "1601";
BA_ "CI_SigId" SG_ 2566841921 LocalMinOfs_FEE641 1569;
BA_ "CI_SigName" SG_ 2566841921 LocalMinOfs_FEE641 "Local minute offset";
BA_ "GenSigStartValue" SG_ 2566841921 LocalMinOfs_FEE641 255;
BA_ "GenSigTimeoutTime_PCM" SG_ 2566841921 LocalMinOfs_FEE641 5000;
BA_ "SPN" SG_ 2566841921 LocalMinOfs_FEE641 1601;
BA_ "SigType" SG_ 2566841921 LocalMinOfs_FEE641 1;
BA_ "CI_ParId" SG_ 2566841921 Yr_FEE641 "964";
BA_ "CI_SigId" SG_ 2566841921 Yr_FEE641 1568;
BA_ "CI_SigName" SG_ 2566841921 Yr_FEE641 "Year";
BA_ "GenSigStartValue" SG_ 2566841921 Yr_FEE641 255;
BA_ "GenSigTimeoutTime_PCM" SG_ 2566841921 Yr_FEE641 5000;
BA_ "SPN" SG_ 2566841921 Yr_FEE641 964;
BA_ "SigType" SG_ 2566841921 Yr_FEE641 1;
BA_ "CI_ParId" SG_ 2566841921 Day_FEE641 "962";
BA_ "CI_SigId" SG_ 2566841921 Day_FEE641 1567;
BA_ "CI_SigName" SG_ 2566841921 Day_FEE641 "Day";
BA_ "GenSigStartValue" SG_ 2566841921 Day_FEE641 255;
BA_ "GenSigTimeoutTime_PCM" SG_ 2566841921 Day_FEE641 5000;
BA_ "SPN" SG_ 2566841921 Day_FEE641 962;
BA_ "SigType" SG_ 2566841921 Day_FEE641 1;
BA_ "CI_ParId" SG_ 2566841921 Month_FEE641 "963";
BA_ "CI_SigId" SG_ 2566841921 Month_FEE641 1566;
BA_ "CI_SigName" SG_ 2566841921 Month_FEE641 "Month";
BA_ "GenSigStartValue" SG_ 2566841921 Month_FEE641 255;
BA_ "GenSigTimeoutTime_PCM" SG_ 2566841921 Month_FEE641 5000;
BA_ "SPN" SG_ 2566841921 Month_FEE641 963;
BA_ "SigType" SG_ 2566841921 Month_FEE641 1;
BA_ "CI_ParId" SG_ 2566841921 Hr_FEE641 "961";
BA_ "CI_SigId" SG_ 2566841921 Hr_FEE641 1565;
BA_ "CI_SigName" SG_ 2566841921 Hr_FEE641 "Hours";
BA_ "GenSigStartValue" SG_ 2566841921 Hr_FEE641 255;
BA_ "GenSigTimeoutTime_PCM" SG_ 2566841921 Hr_FEE641 5000;
BA_ "SPN" SG_ 2566841921 Hr_FEE641 961;
BA_ "SigType" SG_ 2566841921 Hr_FEE641 1;
BA_ "CI_ParId" SG_ 2566841921 Min_FEE641 "960";
BA_ "CI_SigId" SG_ 2566841921 Min_FEE641 1564;
BA_ "CI_SigName" SG_ 2566841921 Min_FEE641 "Minutes";
BA_ "GenSigStartValue" SG_ 2566841921 Min_FEE641 255;
BA_ "GenSigTimeoutTime_PCM" SG_ 2566841921 Min_FEE641 5000;
BA_ "SPN" SG_ 2566841921 Min_FEE641 960;
BA_ "SigType" SG_ 2566841921 Min_FEE641 1;
BA_ "CI_ParId" SG_ 2566841921 Sec_FEE641 "959";
BA_ "CI_SigId" SG_ 2566841921 Sec_FEE641 1563;
BA_ "CI_SigName" SG_ 2566841921 Sec_FEE641 "Seconds";
BA_ "GenSigStartValue" SG_ 2566841921 Sec_FEE641 255;
BA_ "GenSigTimeoutTime_PCM" SG_ 2566841921 Sec_FEE641 5000;
BA_ "SPN" SG_ 2566841921 Sec_FEE641 959;
BA_ "SigType" SG_ 2566841921 Sec_FEE641 1;
BA_ "CI_ParId" SG_ 2566841930 LocalHrOfs_FEE64A "1602";
BA_ "CI_SigId" SG_ 2566841930 LocalHrOfs_FEE64A 1579;
BA_ "CI_SigName" SG_ 2566841930 LocalHrOfs_FEE64A "Local hour offset";
BA_ "SPN" SG_ 2566841930 LocalHrOfs_FEE64A 1602;
BA_ "SigType" SG_ 2566841930 LocalHrOfs_FEE64A 1;
BA_ "CI_ParId" SG_ 2566841930 LocalMinOfs_FEE64A "1601";
BA_ "CI_SigId" SG_ 2566841930 LocalMinOfs_FEE64A 1578;
BA_ "CI_SigName" SG_ 2566841930 LocalMinOfs_FEE64A "Local minute offset";
BA_ "SPN" SG_ 2566841930 LocalMinOfs_FEE64A 1601;
BA_ "SigType" SG_ 2566841930 LocalMinOfs_FEE64A 1;
BA_ "CI_ParId" SG_ 2566841930 Yr_FEE64A "964";
BA_ "CI_SigId" SG_ 2566841930 Yr_FEE64A 1577;
BA_ "CI_SigName" SG_ 2566841930 Yr_FEE64A "Year";
BA_ "SPN" SG_ 2566841930 Yr_FEE64A 964;
BA_ "SigType" SG_ 2566841930 Yr_FEE64A 1;
BA_ "CI_ParId" SG_ 2566841930 Day_FEE64A "962";
BA_ "CI_SigId" SG_ 2566841930 Day_FEE64A 1576;
BA_ "CI_SigName" SG_ 2566841930 Day_FEE64A "Day";
BA_ "SPN" SG_ 2566841930 Day_FEE64A 962;
BA_ "SigType" SG_ 2566841930 Day_FEE64A 1;
BA_ "CI_ParId" SG_ 2566841930 Month_FEE64A "963";
BA_ "CI_SigId" SG_ 2566841930 Month_FEE64A 1575;
BA_ "CI_SigName" SG_ 2566841930 Month_FEE64A "Month";
BA_ "SPN" SG_ 2566841930 Month_FEE64A 963;
BA_ "SigType" SG_ 2566841930 Month_FEE64A 1;
BA_ "CI_ParId" SG_ 2566841930 Hr_FEE64A "961";
BA_ "CI_SigId" SG_ 2566841930 Hr_FEE64A 1574;
BA_ "CI_SigName" SG_ 2566841930 Hr_FEE64A "Hours";
BA_ "SPN" SG_ 2566841930 Hr_FEE64A 961;
BA_ "SigType" SG_ 2566841930 Hr_FEE64A 1;
BA_ "CI_ParId" SG_ 2566841930 Min_FEE64A "960";
BA_ "CI_SigId" SG_ 2566841930 Min_FEE64A 1573;
BA_ "CI_SigName" SG_ 2566841930 Min_FEE64A "Minutes";
BA_ "SPN" SG_ 2566841930 Min_FEE64A 960;
BA_ "SigType" SG_ 2566841930 Min_FEE64A 1;
BA_ "CI_ParId" SG_ 2566841930 Sec_FEE64A "959";
BA_ "CI_SigId" SG_ 2566841930 Sec_FEE64A 1572;
BA_ "CI_SigName" SG_ 2566841930 Sec_FEE64A "Seconds";
BA_ "SPN" SG_ 2566841930 Sec_FEE64A 959;
BA_ "SigType" SG_ 2566841930 Sec_FEE64A 1;
BA_ "CI_ParId" SG_ 2566764851 RefTirePrs "3191";
BA_ "CI_SigId" SG_ 2566764851 RefTirePrs 6099;
BA_ "CI_SigName" SG_ 2566764851 RefTirePrs "Reference Tire Pressure";
BA_ "SPN" SG_ 2566764851 RefTirePrs 3191;
BA_ "SigType" SG_ 2566764851 RefTirePrs 1;
BA_ "CI_ParId" SG_ 2566764851 TireLoc "3190";
BA_ "CI_SigId" SG_ 2566764851 TireLoc 6098;
BA_ "CI_SigName" SG_ 2566764851 TireLoc "Tire Location";
BA_ "SPN" SG_ 2566764851 TireLoc 3190;
BA_ "CI_ParId" SG_ 2566846467 TransmOilTemp1 "177";
BA_ "CI_SigId" SG_ 2566846467 TransmOilTemp1 1477;
BA_ "CI_SigName" SG_ 2566846467 TransmOilTemp1 "Transmission Oil Temperature 1";
BA_ "GenSigTimeoutTime_PCM" SG_ 2566846467 TransmOilTemp1 5000;
BA_ "SPN" SG_ 2566846467 TransmOilTemp1 177;
BA_ "SigType" SG_ 2566846467 TransmOilTemp1 1;
BA_ "CI_ParId" SG_ 2566755587 TransmTrqConvOilOutTemp "3823";
BA_ "CI_SigId" SG_ 2566755587 TransmTrqConvOilOutTemp 1485;
BA_ "CI_SigName" SG_ 2566755587 TransmTrqConvOilOutTemp "Transmission Torque Converter Oil Outlet Temperature";
BA_ "GenSigTimeoutTime_PCM" SG_ 2566755587 TransmTrqConvOilOutTemp 5000;
BA_ "SPN" SG_ 2566755587 TransmTrqConvOilOutTemp 3823;
BA_ "SigType" SG_ 2566755587 TransmTrqConvOilOutTemp 1;
BA_ "CI_ParId" SG_ 2566803211 YcBrkCtrlActv "1819";
BA_ "CI_SigId" SG_ 2566803211 YcBrkCtrlActv 758;
BA_ "CI_SigName" SG_ 2566803211 YcBrkCtrlActv "YC Brake Control active";
BA_ "GenSigTimeoutTime_PCM" SG_ 2566803211 YcBrkCtrlActv 500;
BA_ "SPN" SG_ 2566803211 YcBrkCtrlActv 1819;
BA_ "SigType" SG_ 2566803211 YcBrkCtrlActv 4;
BA_ "CI_ParId" SG_ 2566803211 YcEngCtrlActv "1817";
BA_ "CI_SigId" SG_ 2566803211 YcEngCtrlActv 757;
BA_ "CI_SigName" SG_ 2566803211 YcEngCtrlActv "YC Engine Control active";
BA_ "GenSigTimeoutTime_PCM" SG_ 2566803211 YcEngCtrlActv 500;
BA_ "SPN" SG_ 2566803211 YcEngCtrlActv 1817;
BA_ "SigType" SG_ 2566803211 YcEngCtrlActv 4;
BA_ "CI_ParId" SG_ 2566803211 RopBrkCtrlActv "1818";
BA_ "CI_SigId" SG_ 2566803211 RopBrkCtrlActv 756;
BA_ "CI_SigName" SG_ 2566803211 RopBrkCtrlActv "ROP Brake Control active";
BA_ "GenSigTimeoutTime_PCM" SG_ 2566803211 RopBrkCtrlActv 500;
BA_ "SPN" SG_ 2566803211 RopBrkCtrlActv 1818;
BA_ "SigType" SG_ 2566803211 RopBrkCtrlActv 4;
BA_ "CI_ParId" SG_ 2566803211 RopEngCtrlActv "1816";
BA_ "CI_SigId" SG_ 2566803211 RopEngCtrlActv 755;
BA_ "CI_SigName" SG_ 2566803211 RopEngCtrlActv "ROP Engine Control active";
BA_ "GenSigTimeoutTime_PCM" SG_ 2566803211 RopEngCtrlActv 500;
BA_ "SPN" SG_ 2566803211 RopEngCtrlActv 1816;
BA_ "SigType" SG_ 2566803211 RopEngCtrlActv 4;
BA_ "CI_ParId" SG_ 2566803211 VdcBrkLightReq "1815";
BA_ "CI_SigId" SG_ 2566803211 VdcBrkLightReq 754;
BA_ "CI_SigName" SG_ 2566803211 VdcBrkLightReq "VDC brake light request";
BA_ "GenSigTimeoutTime_PCM" SG_ 2566803211 VdcBrkLightReq 500;
BA_ "SPN" SG_ 2566803211 VdcBrkLightReq 1815;
BA_ "SigType" SG_ 2566803211 VdcBrkLightReq 4;
BA_ "CI_ParId" SG_ 2566803211 VdcFullyOp "1814";
BA_ "CI_SigId" SG_ 2566803211 VdcFullyOp 753;
BA_ "CI_SigName" SG_ 2566803211 VdcFullyOp "VDC Fully Operational";
BA_ "GenSigTimeoutTime_PCM" SG_ 2566803211 VdcFullyOp 500;
BA_ "SPN" SG_ 2566803211 VdcFullyOp 1814;
BA_ "SigType" SG_ 2566803211 VdcFullyOp 4;
BA_ "CI_ParId" SG_ 2566803211 VdcInfoSig "1813";
BA_ "CI_SigId" SG_ 2566803211 VdcInfoSig 752;
BA_ "CI_SigName" SG_ 2566803211 VdcInfoSig "VDC Information Signal";
BA_ "GenSigTimeoutTime_PCM" SG_ 2566803211 VdcInfoSig 500;
BA_ "SPN" SG_ 2566803211 VdcInfoSig 1813;
BA_ "SigType" SG_ 2566803211 VdcInfoSig 4;
BA_ "CI_ParId" SG_ 2566832622 TripDistHr "918";
BA_ "CI_SigId" SG_ 2566832622 TripDistHr 1535;
BA_ "CI_SigName" SG_ 2566832622 TripDistHr "Trip Distance (High Resolution)";
BA_ "GenSigTimeoutTime_PCM" SG_ 2566832622 TripDistHr 5000;
BA_ "SPN" SG_ 2566832622 TripDistHr 918;
BA_ "SigType" SG_ 2566832622 TripDistHr 1;
BA_ "CI_ParId" SG_ 2566832622 TotVehDistHr "917";
BA_ "CI_SigId" SG_ 2566832622 TotVehDistHr 1534;
BA_ "CI_SigName" SG_ 2566832622 TotVehDistHr "Total Vehicle Distance (High Resolution)";
BA_ "GenSigTimeoutTime_PCM" SG_ 2566832622 TotVehDistHr 5000;
BA_ "SPN" SG_ 2566832622 TotVehDistHr 917;
BA_ "SigType" SG_ 2566832622 TotVehDistHr 1;
BA_ "CI_ParId" SG_ 2566832407 TotVehDistHr_FEC117 "917";
BA_ "CI_SigId" SG_ 2566832407 TotVehDistHr_FEC117 1531;
BA_ "CI_SigName" SG_ 2566832407 TotVehDistHr_FEC117 "Total Vehicle Distance (High Resolution)";
BA_ "GenSigTimeoutTime_PCM" SG_ 2566832407 TotVehDistHr_FEC117 5000;
BA_ "SPN" SG_ 2566832407 TotVehDistHr_FEC117 917;
BA_ "SigType" SG_ 2566832407 TotVehDistHr_FEC117 1;
BA_ "CI_ParId" SG_ 2566842433 Altitude "580";
BA_ "CI_SigId" SG_ 2566842433 Altitude 9759;
BA_ "CI_SigName" SG_ 2566842433 Altitude "Altitude";
BA_ "GenSigTimeoutTime_PCM" SG_ 2566842433 Altitude 5000;
BA_ "SPN" SG_ 2566842433 Altitude 580;
BA_ "SigType" SG_ 2566842433 Altitude 1;
BA_ "CI_ParId" SG_ 2566842433 Pitch "583";
BA_ "CI_SigId" SG_ 2566842433 Pitch 9758;
BA_ "CI_SigName" SG_ 2566842433 Pitch "Pitch";
BA_ "GenSigTimeoutTime_PCM" SG_ 2566842433 Pitch 5000;
BA_ "SPN" SG_ 2566842433 Pitch 583;
BA_ "SigType" SG_ 2566842433 Pitch 1;
BA_ "CI_ParId" SG_ 2566842433 NavBasedVehSpeed "517";
BA_ "CI_SigId" SG_ 2566842433 NavBasedVehSpeed 9757;
BA_ "CI_SigName" SG_ 2566842433 NavBasedVehSpeed "Navigation-Based Vehicle Speed";
BA_ "GenSigTimeoutTime_PCM" SG_ 2566842433 NavBasedVehSpeed 5000;
BA_ "SPN" SG_ 2566842433 NavBasedVehSpeed 517;
BA_ "SigType" SG_ 2566842433 NavBasedVehSpeed 1;
BA_ "CI_ParId" SG_ 2566842433 CompassBear "165";
BA_ "CI_SigId" SG_ 2566842433 CompassBear 9756;
BA_ "CI_SigName" SG_ 2566842433 CompassBear "Compass Bearing";
BA_ "GenSigTimeoutTime_PCM" SG_ 2566842433 CompassBear 5000;
BA_ "SPN" SG_ 2566842433 CompassBear 165;
BA_ "SigType" SG_ 2566842433 CompassBear 1;
BA_ "CI_ParId" SG_ 2566842442 Altitude_FEE84A "580";
BA_ "CI_SigId" SG_ 2566842442 Altitude_FEE84A 9764;
BA_ "CI_SigName" SG_ 2566842442 Altitude_FEE84A "Altitude";
BA_ "GenSigTimeoutTime_SGW" SG_ 2566842442 Altitude_FEE84A 5000;
BA_ "SPN" SG_ 2566842442 Altitude_FEE84A 580;
BA_ "SigType" SG_ 2566842442 Altitude_FEE84A 1;
BA_ "CI_ParId" SG_ 2566842442 Pitch_FEE84A "583";
BA_ "CI_SigId" SG_ 2566842442 Pitch_FEE84A 9763;
BA_ "CI_SigName" SG_ 2566842442 Pitch_FEE84A "Pitch";
BA_ "GenSigTimeoutTime_SGW" SG_ 2566842442 Pitch_FEE84A 5000;
BA_ "SPN" SG_ 2566842442 Pitch_FEE84A 583;
BA_ "SigType" SG_ 2566842442 Pitch_FEE84A 1;
BA_ "CI_ParId" SG_ 2566842442 NavBasedVehSpeed_FEE84A "517";
BA_ "CI_SigId" SG_ 2566842442 NavBasedVehSpeed_FEE84A 9762;
BA_ "CI_SigName" SG_ 2566842442 NavBasedVehSpeed_FEE84A "Navigation-Based Vehicle Speed";
BA_ "GenSigTimeoutTime_SGW" SG_ 2566842442 NavBasedVehSpeed_FEE84A 5000;
BA_ "SPN" SG_ 2566842442 NavBasedVehSpeed_FEE84A 517;
BA_ "SigType" SG_ 2566842442 NavBasedVehSpeed_FEE84A 1;
BA_ "CI_ParId" SG_ 2566842442 CompassBear_FEE84A "165";
BA_ "CI_SigId" SG_ 2566842442 CompassBear_FEE84A 9761;
BA_ "CI_SigName" SG_ 2566842442 CompassBear_FEE84A "Compass Bearing";
BA_ "GenSigTimeoutTime_SGW" SG_ 2566842442 CompassBear_FEE84A 5000;
BA_ "SPN" SG_ 2566842442 CompassBear_FEE84A 165;
BA_ "SigType" SG_ 2566842442 CompassBear_FEE84A 1;
BA_ "CI_ParId" SG_ 2566752586 VehRoll "3623";
BA_ "CI_SigId" SG_ 2566752586 VehRoll 9780;
BA_ "CI_SigName" SG_ 2566752586 VehRoll "Vehicle Roll";
BA_ "SPN" SG_ 2566752586 VehRoll 3623;
BA_ "SigType" SG_ 2566752586 VehRoll 1;
BA_ "CI_ParId" SG_ 2566846208 KeyBatPot "158";
BA_ "CI_SigId" SG_ 2566846208 KeyBatPot 3536;
BA_ "CI_SigName" SG_ 2566846208 KeyBatPot "Key Switch Battery Potential";
BA_ "GenSigTimeoutTime_PCM" SG_ 2566846208 KeyBatPot 5000;
BA_ "SPN" SG_ 2566846208 KeyBatPot 158;
BA_ "SigType" SG_ 2566846208 KeyBatPot 1;
BA_ "CI_ParId" SG_ 2566846208 BatPot_PwrIn1 "168";
BA_ "CI_SigId" SG_ 2566846208 BatPot_PwrIn1 3535;
BA_ "CI_SigName" SG_ 2566846208 BatPot_PwrIn1 "Battery Potential / Power Input 1";
BA_ "GenSigTimeoutTime_PCM" SG_ 2566846208 BatPot_PwrIn1 5000;
BA_ "SPN" SG_ 2566846208 BatPot_PwrIn1 168;
BA_ "SigType" SG_ 2566846208 BatPot_PwrIn1 1;
BA_ "CI_ParId" SG_ 2566846241 KeyBatPot_FEF721 "158";
BA_ "CI_SigId" SG_ 2566846241 KeyBatPot_FEF721 3551;
BA_ "CI_SigName" SG_ 2566846241 KeyBatPot_FEF721 "Key Switch Battery Potential";
BA_ "GenSigSendType" SG_ 2566846241 KeyBatPot_FEF721 3;
BA_ "GenSigTimeoutTime_PCM" SG_ 2566846241 KeyBatPot_FEF721 5000;
BA_ "SPN" SG_ 2566846241 KeyBatPot_FEF721 158;
BA_ "SigType" SG_ 2566846241 KeyBatPot_FEF721 1;
BA_ "CI_ParId" SG_ 2566846241 BatPot_PwrIn1_FEF721 "168";
BA_ "CI_SigId" SG_ 2566846241 BatPot_PwrIn1_FEF721 3550;
BA_ "CI_SigName" SG_ 2566846241 BatPot_PwrIn1_FEF721 "Battery Potential / Power Input 1";
BA_ "GenSigSendType" SG_ 2566846241 BatPot_PwrIn1_FEF721 3;
BA_ "GenSigTimeoutTime_PCM" SG_ 2566846241 BatPot_PwrIn1_FEF721 5000;
BA_ "SPN" SG_ 2566846241 BatPot_PwrIn1_FEF721 168;
BA_ "SigType" SG_ 2566846241 BatPot_PwrIn1_FEF721 1;
BA_ "CI_ParId" SG_ 2566843392 Vin "237";
BA_ "CI_SigId" SG_ 2566843392 Vin 1644;
BA_ "CI_SigName" SG_ 2566843392 Vin "Vehicle Identification Number";
BA_ "GenSigTimeoutTime_PCM" SG_ 2566843392 Vin 50000;
BA_ "SPN" SG_ 2566843392 Vin 237;
BA_ "SigType" SG_ 2566843392 Vin 8;
BA_ "CI_ParId" SG_ 2566843466 Vin_FEEC4A "237";
BA_ "CI_SigId" SG_ 2566843466 Vin_FEEC4A 1654;
BA_ "CI_SigName" SG_ 2566843466 Vin_FEEC4A "Vehicle Identification Number";
BA_ "SPN" SG_ 2566843466 Vin_FEEC4A 237;
BA_ "SigType" SG_ 2566843466 Vin_FEEC4A 8;
BA_ "CI_ParId" SG_ 2566843630 Vin_FEECEE "237";
BA_ "CI_SigId" SG_ 2566843630 Vin_FEECEE 1649;
BA_ "CI_SigName" SG_ 2566843630 Vin_FEECEE "Vehicle Identification Number";
BA_ "SPN" SG_ 2566843630 Vin_FEECEE 237;
BA_ "SigType" SG_ 2566843630 Vin_FEECEE 8;
BA_ "CI_ParId" SG_ 2566845249 Long_FEF341 "585";
BA_ "CI_SigId" SG_ 2566845249 Long_FEF341 9794;
BA_ "CI_SigName" SG_ 2566845249 Long_FEF341 "Longitude";
BA_ "GenSigTimeoutTime_PCM" SG_ 2566845249 Long_FEF341 5000;
BA_ "SPN" SG_ 2566845249 Long_FEF341 585;
BA_ "SigType" SG_ 2566845249 Long_FEF341 1;
BA_ "CI_ParId" SG_ 2566845249 Lat_FEF341 "584";
BA_ "CI_SigId" SG_ 2566845249 Lat_FEF341 9793;
BA_ "CI_SigName" SG_ 2566845249 Lat_FEF341 "Latitude";
BA_ "GenSigTimeoutTime_PCM" SG_ 2566845249 Lat_FEF341 5000;
BA_ "SPN" SG_ 2566845249 Lat_FEF341 584;
BA_ "SigType" SG_ 2566845249 Lat_FEF341 1;
BA_ "CI_ParId" SG_ 2566845258 Long_FEF34A "585";
BA_ "CI_SigId" SG_ 2566845258 Long_FEF34A 9797;
BA_ "CI_SigName" SG_ 2566845258 Long_FEF34A "Longitude";
BA_ "GenSigTimeoutTime_SGW" SG_ 2566845258 Long_FEF34A 5000;
BA_ "SPN" SG_ 2566845258 Long_FEF34A 585;
BA_ "SigType" SG_ 2566845258 Long_FEF34A 1;
BA_ "CI_ParId" SG_ 2566845258 Lat_FEF34A "584";
BA_ "CI_SigId" SG_ 2566845258 Lat_FEF34A 9796;
BA_ "CI_SigName" SG_ 2566845258 Lat_FEF34A "Latitude";
BA_ "GenSigTimeoutTime_SGW" SG_ 2566845258 Lat_FEF34A 5000;
BA_ "SPN" SG_ 2566845258 Lat_FEF34A 584;
BA_ "SigType" SG_ 2566845258 Lat_FEF34A 1;
BA_ "CI_ParId" SG_ 2566845422 Long_FEF3EE "585";
BA_ "CI_SigId" SG_ 2566845422 Long_FEF3EE 9803;
BA_ "CI_SigName" SG_ 2566845422 Long_FEF3EE "Longitude";
BA_ "GenSigTimeoutTime_PCM" SG_ 2566845422 Long_FEF3EE 5000;
BA_ "SPN" SG_ 2566845422 Long_FEF3EE 585;
BA_ "SigType" SG_ 2566845422 Long_FEF3EE 1;
BA_ "CI_ParId" SG_ 2566845422 Lat_FEF3EE "584";
BA_ "CI_SigId" SG_ 2566845422 Lat_FEF3EE 9802;
BA_ "CI_SigName" SG_ 2566845422 Lat_FEF3EE "Latitude";
BA_ "GenSigTimeoutTime_PCM" SG_ 2566845422 Lat_FEF3EE 5000;
BA_ "SPN" SG_ 2566845422 Lat_FEF3EE 584;
BA_ "SigType" SG_ 2566845422 Lat_FEF3EE 1;
BA_ "CI_ParId" SG_ 2566649418 TimeDilutionOfPrec "8132";
BA_ "CI_SigId" SG_ 2566649418 TimeDilutionOfPrec 9818;
BA_ "CI_SigName" SG_ 2566649418 TimeDilutionOfPrec "Time Dilution of Precision";
BA_ "GenSigTimeoutTime_SGW" SG_ 2566649418 TimeDilutionOfPrec 25000;
BA_ "SPN" SG_ 2566649418 TimeDilutionOfPrec 8132;
BA_ "CI_ParId" SG_ 2566649418 PosDilutionOfPrec "8131";
BA_ "CI_SigId" SG_ 2566649418 PosDilutionOfPrec 9817;
BA_ "CI_SigName" SG_ 2566649418 PosDilutionOfPrec "Position Dilution of Precision";
BA_ "GenSigTimeoutTime_SGW" SG_ 2566649418 PosDilutionOfPrec 25000;
BA_ "SPN" SG_ 2566649418 PosDilutionOfPrec 8131;
BA_ "CI_ParId" SG_ 2566649418 VertDilutionOfPrec "8130";
BA_ "CI_SigId" SG_ 2566649418 VertDilutionOfPrec 9816;
BA_ "CI_SigName" SG_ 2566649418 VertDilutionOfPrec "Vertical Dilution of Precision";
BA_ "GenSigTimeoutTime_SGW" SG_ 2566649418 VertDilutionOfPrec 25000;
BA_ "SPN" SG_ 2566649418 VertDilutionOfPrec 8130;
BA_ "CI_ParId" SG_ 2566649418 HorDilutionOfPrec "8129";
BA_ "CI_SigId" SG_ 2566649418 HorDilutionOfPrec 9815;
BA_ "CI_SigName" SG_ 2566649418 HorDilutionOfPrec "Horizontal Dilution of Precision";
BA_ "GenSigTimeoutTime_SGW" SG_ 2566649418 HorDilutionOfPrec 25000;
BA_ "SPN" SG_ 2566649418 HorDilutionOfPrec 8129;
BA_ "CI_ParId" SG_ 2566649418 TotNumOfSatsInView "8128";
BA_ "CI_SigId" SG_ 2566649418 TotNumOfSatsInView 9814;
BA_ "CI_SigName" SG_ 2566649418 TotNumOfSatsInView "Total Number of Satellites in View";
BA_ "GenSigTimeoutTime_SGW" SG_ 2566649418 TotNumOfSatsInView 25000;
BA_ "SPN" SG_ 2566649418 TotNumOfSatsInView 8128;
BA_ "SigType" SG_ 2566649418 TotNumOfSatsInView 1;
BA_ "CI_ParId" SG_ 2566842606 Altitude_FEE8EE "580";
BA_ "CI_SigId" SG_ 2566842606 Altitude_FEE8EE 50266;
BA_ "CI_SigName" SG_ 2566842606 Altitude_FEE8EE "Altitude";
BA_ "SPN" SG_ 2566842606 Altitude_FEE8EE 580;
BA_ "SigType" SG_ 2566842606 Altitude_FEE8EE 1;
BA_ "CI_ParId" SG_ 2566842606 NavBasedVehSpeed_FEE8EE "517";
BA_ "CI_SigId" SG_ 2566842606 NavBasedVehSpeed_FEE8EE 50265;
BA_ "CI_SigName" SG_ 2566842606 NavBasedVehSpeed_FEE8EE "Navigation-Based Vehicle Speed";
BA_ "SPN" SG_ 2566842606 NavBasedVehSpeed_FEE8EE 517;
BA_ "SigType" SG_ 2566842606 NavBasedVehSpeed_FEE8EE 1;
BA_ "CI_ParId" SG_ 2566842606 CompassBear_FEE8EE "165";
BA_ "CI_SigId" SG_ 2566842606 CompassBear_FEE8EE 50264;
BA_ "CI_SigName" SG_ 2566842606 CompassBear_FEE8EE "Compass Bearing";
BA_ "SPN" SG_ 2566842606 CompassBear_FEE8EE 165;
BA_ "SigType" SG_ 2566842606 CompassBear_FEE8EE 1;
BA_ "CI_ParId" SG_ 2348875082 StopTime "84";
BA_ "CI_SigId" SG_ 2348875082 StopTime 50002;
BA_ "CI_SigName" SG_ 2348875082 StopTime "Wheel-Based Vehicle Speed Average";
BA_ "GenSigTimeoutTime_PCM" SG_ 2348875082 StopTime 500;
BA_ "SPN" SG_ 2348875082 StopTime 84;
BA_ "SigType" SG_ 2348875082 StopTime 1;
BA_ "CI_SigId" SG_ 2348875082 PTOTime 50001;
BA_ "CI_ParId" SG_ 2348874826 DrivingTime "84";
BA_ "CI_SigId" SG_ 2348874826 DrivingTime 50004;
BA_ "CI_SigName" SG_ 2348874826 DrivingTime "Wheel-Based Vehicle Speed Average";
BA_ "GenSigTimeoutTime_PCM" SG_ 2348874826 DrivingTime 500;
BA_ "SPN" SG_ 2348874826 DrivingTime 84;
BA_ "SigType" SG_ 2348874826 DrivingTime 1;
BA_ "CI_ParId" SG_ 2348874826 RegenerationTime "84";
BA_ "CI_SigId" SG_ 2348874826 RegenerationTime 50003;
BA_ "CI_SigName" SG_ 2348874826 RegenerationTime "Wheel-Based Vehicle Speed Average";
BA_ "GenSigTimeoutTime_PCM" SG_ 2348874826 RegenerationTime 500;
BA_ "SPN" SG_ 2348874826 RegenerationTime 84;
BA_ "SigType" SG_ 2348874826 RegenerationTime 1;
BA_ "CI_ParId" SG_ 2348874570 RegenerationDistance "84";
BA_ "CI_SigId" SG_ 2348874570 RegenerationDistance 50006;
BA_ "CI_SigName" SG_ 2348874570 RegenerationDistance "Wheel-Based Vehicle Speed Average";
BA_ "GenSigTimeoutTime_PCM" SG_ 2348874570 RegenerationDistance 500;
BA_ "SPN" SG_ 2348874570 RegenerationDistance 84;
BA_ "SigType" SG_ 2348874570 RegenerationDistance 1;
BA_ "CI_ParId" SG_ 2348874570 EcoSwitchDistance "84";
BA_ "CI_SigId" SG_ 2348874570 EcoSwitchDistance 50005;
BA_ "CI_SigName" SG_ 2348874570 EcoSwitchDistance "Wheel-Based Vehicle Speed Average";
BA_ "GenSigTimeoutTime_PCM" SG_ 2348874570 EcoSwitchDistance 500;
BA_ "SPN" SG_ 2348874570 EcoSwitchDistance 84;
BA_ "SigType" SG_ 2348874570 EcoSwitchDistance 1;
BA_ "CI_ParId" SG_ 2348874314 EcoSwitchTime "84";
BA_ "CI_SigId" SG_ 2348874314 EcoSwitchTime 50008;
BA_ "CI_SigName" SG_ 2348874314 EcoSwitchTime "Wheel-Based Vehicle Speed Average";
BA_ "GenSigTimeoutTime_PCM" SG_ 2348874314 EcoSwitchTime 500;
BA_ "SPN" SG_ 2348874314 EcoSwitchTime 84;
BA_ "SigType" SG_ 2348874314 EcoSwitchTime 1;
BA_ "CI_SigId" SG_ 2348874314 RecovEnergySumAbs 50007;
BA_ "CI_SigId" SG_ 2348875594 TracEnergyDrivingSumAbs 50011;
BA_ "CI_SigId" SG_ 2348875594 EnergyConsPTOSumAbs 50010;
BA_ "CI_SigId" SG_ 2348875594 EnergyConsAvg 50009;
BA_ "CI_SigId" SG_ 2348871498 BatTempAvg 50015;
BA_ "GenSigStartValue" SG_ 2348871498 BatTempAvg 40;
BA_ "CI_SigId" SG_ 2348871498 AmbTempMax 50014;
BA_ "GenSigStartValue" SG_ 2348871498 AmbTempMax 8736;
BA_ "CI_SigId" SG_ 2348871498 AmbTempAvg 50013;
BA_ "GenSigStartValue" SG_ 2348871498 AmbTempAvg 8736;
BA_ "CI_SigId" SG_ 2348871498 BatTempMax 50012;
BA_ "GenSigStartValue" SG_ 2348871498 BatTempMax 40;
BA_ "CI_ParId" SG_ 2348871242 StopNumbersOccurrences "84";
BA_ "CI_SigId" SG_ 2348871242 StopNumbersOccurrences 50018;
BA_ "CI_SigName" SG_ 2348871242 StopNumbersOccurrences "Wheel-Based Vehicle Speed Average";
BA_ "GenSigTimeoutTime_PCM" SG_ 2348871242 StopNumbersOccurrences 500;
BA_ "SPN" SG_ 2348871242 StopNumbersOccurrences 84;
BA_ "SigType" SG_ 2348871242 StopNumbersOccurrences 1;
BA_ "CI_ParId" SG_ 2348871242 DrivingDistance "84";
BA_ "CI_SigId" SG_ 2348871242 DrivingDistance 50017;
BA_ "CI_SigName" SG_ 2348871242 DrivingDistance "Wheel-Based Vehicle Speed Average";
BA_ "GenSigTimeoutTime_PCM" SG_ 2348871242 DrivingDistance 500;
BA_ "SPN" SG_ 2348871242 DrivingDistance 84;
BA_ "SigType" SG_ 2348871242 DrivingDistance 1;
BA_ "CI_ParId" SG_ 2348871242 WhBasedVehSpeedAvg "84";
BA_ "CI_SigId" SG_ 2348871242 WhBasedVehSpeedAvg 50016;
BA_ "CI_SigName" SG_ 2348871242 WhBasedVehSpeedAvg "Wheel-Based Vehicle Speed Average";
BA_ "GenSigTimeoutTime_PCM" SG_ 2348871242 WhBasedVehSpeedAvg 500;
BA_ "SPN" SG_ 2348871242 WhBasedVehSpeedAvg 84;
BA_ "SigType" SG_ 2348871242 WhBasedVehSpeedAvg 1;
BA_ "CI_SigId" SG_ 2561142090 Driver_Stop 50019;
BA_ "CI_SigId" SG_ 2561141834 FuelConsumptionEstimatedDiesel 50022;
BA_ "CI_SigId" SG_ 2561141834 FuelConsumptionGas 50021;
BA_ "CI_SigId" SG_ 2561141834 FuelConsumptionDiesel 50020;
BA_ "CI_SigId" SG_ 2561141578 OverrevvingSeconds 50029;
BA_ "CI_SigId" SG_ 2561141578 SlopeSoftUphillPerc2 50028;
BA_ "CI_SigId" SG_ 2561141578 SlopeDownhillPerc 50027;
BA_ "CI_SigId" SG_ 2561141578 SlopeSoftDownhillPerc 50026;
BA_ "CI_SigId" SG_ 2561141578 SlopeUphillPerc 50025;
BA_ "CI_SigId" SG_ 2561141578 SlopeSoftUphillPerc 50024;
BA_ "CI_SigId" SG_ 2561141578 EstimatedVehicleWeight 50023;
BA_ "CI_SigId" SG_ 2561141322 IndexDegreeOfDificulty 50036;
BA_ "CI_SigId" SG_ 2561141322 IndexMissionSeverity 50035;
BA_ "CI_SigId" SG_ 2561141322 IndexAtmosphericConditions 50034;
BA_ "CI_SigId" SG_ 2561141322 IndexTortuosity 50033;
BA_ "CI_SigId" SG_ 2561141322 IndexSpeedProfile 50032;
BA_ "CI_SigId" SG_ 2561141322 IndexAltimetry 50031;
BA_ "CI_SigId" SG_ 2561141322 IndexVehicleLoad 50030;
BA_ "CI_SigId" SG_ 2561141066 EventValid 50042;
BA_ "CI_SigId" SG_ 2561141066 EventHdop 50041;
BA_ "CI_SigId" SG_ 2561141066 EventVdop 50040;
BA_ "CI_SigId" SG_ 2561141066 EventAltitude 50039;
BA_ "GenSigStartValue" SG_ 2561141066 EventAltitude 2500;
BA_ "CI_SigId" SG_ 2561141066 EventLongitude 50038;
BA_ "CI_SigId" SG_ 2561141066 EventLatitude 50037;
BA_ "CI_SigId" SG_ 2561140810 EvaluatedSamplesTrip 50044;
BA_ "CI_SigId" SG_ 2561140810 EvaluatedMetersTrip 50043;
BA_ "CI_SigId" SG_ 2561140554 EventDas 50046;
BA_ "CI_SigId" SG_ 2561140554 EvaluatedSamplesDas 50045;
BA_ "CI_SigId" SG_ 2561130314 WeightDas 50051;
BA_ "CI_SigId" SG_ 2561130314 BenefitDas 50050;
BA_ "CI_SigId" SG_ 2561130314 TrendDas 50049;
BA_ "CI_SigId" SG_ 2561130314 ValidDas 50048;
BA_ "GenSigStartValue" SG_ 2561130314 ValidDas 3;
BA_ "CI_SigId" SG_ 2561130314 ScoreDas 50047;
BA_ "CI_SigId" SG_ 2561132874 MaxDecelerationHarshBraking 50054;
BA_ "CI_SigId" SG_ 2561132874 EventHarshBraking 50053;
BA_ "CI_SigId" SG_ 2561132874 EvaluatedMetersHarshBraking 50052;
BA_ "CI_SigId" SG_ 2561132618 WeightHarshBraking 50059;
BA_ "CI_SigId" SG_ 2561132618 BenefitHarshBraking 50058;
BA_ "CI_SigId" SG_ 2561132618 TrendHarshBraking 50057;
BA_ "CI_SigId" SG_ 2561132618 ValidHarshBraking 50056;
BA_ "GenSigStartValue" SG_ 2561132618 ValidHarshBraking 3;
BA_ "CI_SigId" SG_ 2561132618 ScoreHarshBraking 50055;
BA_ "CI_SigId" SG_ 2561139786 EventTireSaving 50061;
BA_ "CI_SigId" SG_ 2561139786 EvaluatedSamplesTire 50060;
BA_ "CI_SigId" SG_ 2561139530 WeightTire 50066;
BA_ "CI_SigId" SG_ 2561139530 BenefitTire 50065;
BA_ "CI_SigId" SG_ 2561139530 TrendTire 50064;
BA_ "CI_SigId" SG_ 2561139530 ValidTire 50063;
BA_ "GenSigStartValue" SG_ 2561139530 ValidTire 3;
BA_ "CI_SigId" SG_ 2561139530 ScoreTire 50062;
BA_ "CI_SigId" SG_ 2561139274 MaxDecelerationStop 50073;
BA_ "CI_SigId" SG_ 2561139274 ManeuverCountStop 50072;
BA_ "CI_SigId" SG_ 2561139274 LastManeuverScoreStop 50071;
BA_ "CI_SigId" SG_ 2561139274 StartingSpeedStop 50070;
BA_ "CI_SigId" SG_ 2561139274 DurationStop 50069;
BA_ "CI_SigId" SG_ 2561139274 PanicBrakeState 50068;
BA_ "CI_SigId" SG_ 2561139274 EventStop 50067;
BA_ "CI_SigId" SG_ 2561139018 WeightStop 50078;
BA_ "CI_SigId" SG_ 2561139018 BenefitStop 50077;
BA_ "CI_SigId" SG_ 2561139018 TrendStop 50076;
BA_ "CI_SigId" SG_ 2561139018 ValidStop 50075;
BA_ "GenSigStartValue" SG_ 2561139018 ValidStop 3;
BA_ "CI_SigId" SG_ 2561139018 ScoreStop 50074;
BA_ "CI_SigId" SG_ 2561138762 EventStabilityControl 50080;
BA_ "CI_SigId" SG_ 2561138762 EvaluatedMetersStabilityControl 50079;
BA_ "CI_SigId" SG_ 2561138506 WeightStabilityControl 50085;
BA_ "CI_SigId" SG_ 2561138506 BenefitStabilityControl 50084;
BA_ "CI_SigId" SG_ 2561138506 TrendStabilityControl 50083;
BA_ "CI_SigId" SG_ 2561138506 ValidStabilityControl 50082;
BA_ "GenSigStartValue" SG_ 2561138506 ValidStabilityControl 3;
BA_ "CI_SigId" SG_ 2561138506 ScoreStabilityControl 50081;
BA_ "CI_SigId" SG_ 2561138250 TripEndReason 50089;
BA_ "CI_SigId" SG_ 2561138250 TripActive 50088;
BA_ "CI_SigId" SG_ 2561138250 TripEnded_A7DE4A 50087;
BA_ "CI_SigId" SG_ 2561138250 TripStarted_A7DE4A 50086;
BA_ "CI_SigId" SG_ 2561137994 TimeStampTripStart 50091;
BA_ "CI_SigId" SG_ 2561137994 OdometerTripStart 50090;
BA_ "CI_SigId" SG_ 2561137738 EventTireSafety 50093;
BA_ "CI_SigId" SG_ 2561137738 EvaluatedMetersTireSafety 50092;
BA_ "CI_SigId" SG_ 2561137482 WeightTireSafety 50098;
BA_ "CI_SigId" SG_ 2561137482 BenefitTireSafety 50097;
BA_ "CI_SigId" SG_ 2561137482 TrendTireSafety 50096;
BA_ "CI_SigId" SG_ 2561137482 ValidTireSafety 50095;
BA_ "GenSigStartValue" SG_ 2561137482 ValidTireSafety 3;
BA_ "CI_SigId" SG_ 2561137482 ScoreTireSafety 50094;
BA_ "CI_SigId" SG_ 2561137226 WeightSafety 50103;
BA_ "CI_SigId" SG_ 2561137226 BenefiSafety 50102;
BA_ "CI_SigId" SG_ 2561137226 TrendSafety 50101;
BA_ "CI_SigId" SG_ 2561137226 ValidSafety 50100;
BA_ "GenSigStartValue" SG_ 2561137226 ValidSafety 3;
BA_ "CI_SigId" SG_ 2561137226 ScoreSafety 50099;
BA_ "CI_SigId" SG_ 2561136970 MidRPMBonus 50113;
BA_ "GenSigStartValue" SG_ 2561136970 MidRPMBonus 1;
BA_ "CI_SigId" SG_ 2561136970 LowRPMMalus 50112;
BA_ "GenSigStartValue" SG_ 2561136970 LowRPMMalus 126;
BA_ "CI_SigId" SG_ 2561136970 HighRPMMalus 50111;
BA_ "GenSigStartValue" SG_ 2561136970 HighRPMMalus 126;
BA_ "CI_SigId" SG_ 2561136970 LowRPMLimit 50110;
BA_ "CI_SigId" SG_ 2561136970 HighRPMLimit 50109;
BA_ "CI_SigId" SG_ 2561136970 TorqueLevel 50108;
BA_ "CI_SigId" SG_ 2561136970 RPMZone 50107;
BA_ "CI_SigId" SG_ 2561136970 RPMLevel 50106;
BA_ "CI_SigId" SG_ 2561136970 EventRPM 50105;
BA_ "CI_SigId" SG_ 2561136970 EvaluatedSamplesRpm 50104;
BA_ "CI_SigId" SG_ 2561136714 WeightRpm 50118;
BA_ "CI_SigId" SG_ 2561136714 BenefitRpm 50117;
BA_ "CI_SigId" SG_ 2561136714 TrendRpm 50116;
BA_ "CI_SigId" SG_ 2561136714 ValidRpm 50115;
BA_ "GenSigStartValue" SG_ 2561136714 ValidRpm 3;
BA_ "CI_SigId" SG_ 2561136714 ScoreRpm 50114;
BA_ "CI_SigId" SG_ 2561136458 EventRadar 50120;
BA_ "CI_SigId" SG_ 2561136458 EvaluatedSamplesRadar 50119;
BA_ "CI_SigId" SG_ 2561136202 WeightRadar 50125;
BA_ "CI_SigId" SG_ 2561136202 BenefitRadar 50124;
BA_ "CI_SigId" SG_ 2561136202 TrendRadar 50123;
BA_ "CI_SigId" SG_ 2561136202 ValidRadar 50122;
BA_ "GenSigStartValue" SG_ 2561136202 ValidRadar 3;
BA_ "CI_SigId" SG_ 2561136202 ScoreRadar 50121;
BA_ "CI_SigId" SG_ 2561135946 EventPecc 50127;
BA_ "CI_SigId" SG_ 2561135946 EvaluatedSamplesPecc 50126;
BA_ "CI_SigId" SG_ 2561135690 WeightPecc 50132;
BA_ "CI_SigId" SG_ 2561135690 BenefitPecc 50131;
BA_ "CI_SigId" SG_ 2561135690 TrendPecc 50130;
BA_ "CI_SigId" SG_ 2561135690 ValidPecc 50129;
BA_ "GenSigStartValue" SG_ 2561135690 ValidPecc 3;
BA_ "CI_SigId" SG_ 2561135690 ScorePecc 50128;
BA_ "CI_SigId" SG_ 2561134922 EventLaneDpt 50134;
BA_ "CI_SigId" SG_ 2561134922 EvaluatedSamplesLaneDpt 50133;
BA_ "CI_SigId" SG_ 2561134666 WeightLaneDpt 50139;
BA_ "CI_SigId" SG_ 2561134666 BenefitLaneDpt 50138;
BA_ "CI_SigId" SG_ 2561134666 TrendLaneDpt 50137;
BA_ "CI_SigId" SG_ 2561134666 ValidLaneDpt 50136;
BA_ "GenSigStartValue" SG_ 2561134666 ValidLaneDpt 3;
BA_ "CI_SigId" SG_ 2561134666 ScoreLaneDpt 50135;
BA_ "CI_SigId" SG_ 2561134410 WeightInertiaPecc 50144;
BA_ "CI_SigId" SG_ 2561134410 BenefitInertiaPecc 50143;
BA_ "CI_SigId" SG_ 2561134410 TrendInertiaPecc 50142;
BA_ "CI_SigId" SG_ 2561134410 ValidInertiaPecc 50141;
BA_ "GenSigStartValue" SG_ 2561134410 ValidInertiaPecc 3;
BA_ "CI_SigId" SG_ 2561134410 ScoreInertiaPecc 50140;
BA_ "CI_SigId" SG_ 2561133386 EventHarshSteering 50146;
BA_ "CI_SigId" SG_ 2561133386 EvaluatedMetersHarshSteering 50145;
BA_ "CI_SigId" SG_ 2561133130 WeightHarshSteering 50151;
BA_ "CI_SigId" SG_ 2561133130 BenefitHarshSteering 50150;
BA_ "CI_SigId" SG_ 2561133130 TrendHarshSteering 50149;
BA_ "CI_SigId" SG_ 2561133130 ValidHarshSteering 50148;
BA_ "GenSigStartValue" SG_ 2561133130 ValidHarshSteering 3;
BA_ "CI_SigId" SG_ 2561133130 ScoreHarshSteering 50147;
BA_ "CI_SigId" SG_ 2561132362 EventHandBrake 50153;
BA_ "CI_SigId" SG_ 2561132362 NumEventsHandBrake 50152;
BA_ "CI_SigId" SG_ 2561132106 WeightHandBrake 50158;
BA_ "CI_SigId" SG_ 2561132106 BenefitHandBrake 50157;
BA_ "CI_SigId" SG_ 2561132106 TrendHandBrake 50156;
BA_ "CI_SigId" SG_ 2561132106 ValidHandBrake 50155;
BA_ "GenSigStartValue" SG_ 2561132106 ValidHandBrake 3;
BA_ "CI_SigId" SG_ 2561132106 ScoreHandBrake 50154;
BA_ "CI_SigId" SG_ 2561131594 WeightFuel 50163;
BA_ "CI_SigId" SG_ 2561131594 BenefitFuel 50162;
BA_ "CI_SigId" SG_ 2561131594 TrendFuel 50161;
BA_ "CI_SigId" SG_ 2561131594 ValidFuel 50160;
BA_ "GenSigStartValue" SG_ 2561131594 ValidFuel 3;
BA_ "CI_SigId" SG_ 2561131594 ScoreFuel 50159;
BA_ "CI_SigId" SG_ 2561131338 WeightEngineUse 50168;
BA_ "CI_SigId" SG_ 2561131338 BenefitEngineUse 50167;
BA_ "CI_SigId" SG_ 2561131338 TrendEngineUse 50166;
BA_ "CI_SigId" SG_ 2561131338 ValidEngineUse 50165;
BA_ "GenSigStartValue" SG_ 2561131338 ValidEngineUse 3;
BA_ "CI_SigId" SG_ 2561131338 ScoreEngineUse 50164;
BA_ "CI_SigId" SG_ 2561131082 EvaluatedSamplesEcoMode 50169;
BA_ "CI_SigId" SG_ 2561130826 WeightEcoMode 50174;
BA_ "CI_SigId" SG_ 2561130826 BenefitEcoMode 50173;
BA_ "CI_SigId" SG_ 2561130826 TrendEcoMode 50172;
BA_ "CI_SigId" SG_ 2561130826 ValidEcoMode 50171;
BA_ "GenSigStartValue" SG_ 2561130826 ValidEcoMode 3;
BA_ "CI_SigId" SG_ 2561130826 ScoreEcoMode 50170;
BA_ "CI_SigId" SG_ 2561130570 WeightDeceleration 50179;
BA_ "CI_SigId" SG_ 2561130570 BenefitDeceleration 50178;
BA_ "CI_SigId" SG_ 2561130570 TrendDeceleration 50177;
BA_ "CI_SigId" SG_ 2561130570 ValidDeceleration 50176;
BA_ "GenSigStartValue" SG_ 2561130570 ValidDeceleration 3;
BA_ "CI_SigId" SG_ 2561130570 ScoreDeceleration 50175;
BA_ "CI_SigId" SG_ 2561129802 TimeStampCurrent 50181;
BA_ "CI_SigId" SG_ 2561129802 OdometerTripCurrent 50180;
BA_ "CI_SigId" SG_ 2561129290 WeightCare 50186;
BA_ "CI_SigId" SG_ 2561129290 BenefitCare 50185;
BA_ "CI_SigId" SG_ 2561129290 TrendCare 50184;
BA_ "CI_SigId" SG_ 2561129290 ValidCare 50183;
BA_ "GenSigStartValue" SG_ 2561129290 ValidCare 3;
BA_ "CI_SigId" SG_ 2561129290 ScoreCare 50182;
BA_ "CI_SigId" SG_ 2561129034 EventAuxBrake 50193;
BA_ "CI_SigId" SG_ 2561129034 AuxBrakeActive 50192;
BA_ "CI_SigId" SG_ 2561129034 ManeuverServiceBrakeDistance 50191;
BA_ "GenSigStartValue" SG_ 2561129034 ManeuverServiceBrakeDistance 1;
BA_ "CI_SigId" SG_ 2561129034 ManeuverDistance 50190;
BA_ "CI_SigId" SG_ 2561129034 TotalBrakingDistance 50189;
BA_ "CI_SigId" SG_ 2561129034 Ratio 50188;
BA_ "CI_SigId" SG_ 2561129034 LastManeuverScoreAuxBrake 50187;
BA_ "CI_SigId" SG_ 2561128778 WeightAuxBrake 50198;
BA_ "CI_SigId" SG_ 2561128778 BenefitAuxBrake 50197;
BA_ "CI_SigId" SG_ 2561128778 TrendAuxBrake 50196;
BA_ "CI_SigId" SG_ 2561128778 ValidAuxBrake 50195;
BA_ "GenSigStartValue" SG_ 2561128778 ValidAuxBrake 3;
BA_ "CI_SigId" SG_ 2561128778 ScoreAuxBrake 50194;
BA_ "CI_SigId" SG_ 2561128522 EvaluatedSamplesAirC 50199;
BA_ "CI_SigId" SG_ 2561128266 WeightAirC 50204;
BA_ "CI_SigId" SG_ 2561128266 BenefitAirC 50203;
BA_ "CI_SigId" SG_ 2561128266 TrendAirC 50202;
BA_ "CI_SigId" SG_ 2561128266 ValidAirC 50201;
BA_ "GenSigStartValue" SG_ 2561128266 ValidAirC 3;
BA_ "CI_SigId" SG_ 2561128266 ScoreAirC 50200;
BA_ "CI_SigId" SG_ 2561128010 EventAebs 50206;
BA_ "CI_SigId" SG_ 2561128010 EvaluatedSamplesAebs 50205;
BA_ "CI_SigId" SG_ 2561126986 EventAcc 50208;
BA_ "CI_SigId" SG_ 2561126986 EvaluatedSamplesAcc 50207;
BA_ "CI_SigId" SG_ 2561127754 WeightAebs 50213;
BA_ "CI_SigId" SG_ 2561127754 BenefitAebs 50212;
BA_ "CI_SigId" SG_ 2561127754 TrendAebs 50211;
BA_ "CI_SigId" SG_ 2561127754 ValidAebs 50210;
BA_ "GenSigStartValue" SG_ 2561127754 ValidAebs 3;
BA_ "CI_SigId" SG_ 2561127754 ScoreAebs 50209;
BA_ "CI_SigId" SG_ 2561126730 WeightAcc 50218;
BA_ "CI_SigId" SG_ 2561126730 BenefitAcc 50217;
BA_ "CI_SigId" SG_ 2561126730 TrendAcc 50216;
BA_ "CI_SigId" SG_ 2561126730 ValidAcc 50215;
BA_ "GenSigStartValue" SG_ 2561126730 ValidAcc 3;
BA_ "CI_SigId" SG_ 2561126730 ScoreAcc 50214;
BA_ "CI_SigId" SG_ 2561129546 ResetEcoB 50220;
BA_ "CI_SigId" SG_ 2561129546 ResetEcoA 50219;
BA_ "CI_SigId" SG_ 2561135434 OldDasEnabled 50225;
BA_ "CI_SigId" SG_ 2561135434 OldDasWarning 50224;
BA_ "CI_SigId" SG_ 2561135434 OldDasStop 50223;
BA_ "CI_SigId" SG_ 2561135434 OldDasStatus 50222;
BA_ "CI_SigId" SG_ 2561135434 OldDasPiswa 50221;
BA_ "CI_SigId" SG_ 2561135178 NotificationEnabled 50229;
BA_ "CI_SigId" SG_ 2561135178 NotificationCritical 50228;
BA_ "CI_SigId" SG_ 2561135178 NotificationTypeId 50227;
BA_ "CI_SigId" SG_ 2561135178 NotificationTextId 50226;
BA_ "CI_SigId" SG_ 2561131850 NrSatellites 50235;
BA_ "CI_SigId" SG_ 2561131850 Vdop 50234;
BA_ "CI_SigId" SG_ 2561131850 Hdop 50233;
BA_ "CI_SigId" SG_ 2561131850 GPSAltitude 50232;
BA_ "GenSigStartValue" SG_ 2561131850 GPSAltitude 2500;
BA_ "CI_SigId" SG_ 2561131850 GPSLongitude 50231;
BA_ "CI_SigId" SG_ 2561131850 GPSLatitude 50230;
BA_ "CI_SigId" SG_ 2561140298 VersionModel 50239;
BA_ "GenSigStartValue" SG_ 2561140298 VersionModel 1;
BA_ "CI_SigId" SG_ 2561140298 VersionRevision 50238;
BA_ "GenSigStartValue" SG_ 2561140298 VersionRevision 1;
BA_ "CI_SigId" SG_ 2561140298 VersionMinor 50237;
BA_ "GenSigStartValue" SG_ 2561140298 VersionMinor 1;
BA_ "CI_SigId" SG_ 2561140298 VersionMajor 50236;
BA_ "GenSigStartValue" SG_ 2561140298 VersionMajor 1;
BA_ "CI_SigId" SG_ 2561134154 PunishingManeuverInertia 50248;
BA_ "CI_SigId" SG_ 2561134154 DangerOfCollisionInertia 50247;
BA_ "CI_SigId" SG_ 2561134154 StartingSpeedInertia 50246;
BA_ "CI_SigId" SG_ 2561134154 DurationInertia 50245;
BA_ "CI_SigId" SG_ 2561134154 ManeuverCountInertia 50244;
BA_ "CI_SigId" SG_ 2561134154 EndReasonInertia 50243;
BA_ "CI_SigId" SG_ 2561134154 StartReasonInertia 50242;
BA_ "CI_SigId" SG_ 2561134154 EventInertia 50241;
BA_ "CI_SigId" SG_ 2561134154 LastManeuverScoreInertia 50240;
BA_ "CI_SigId" SG_ 2561133898 WeightInertia 50253;
BA_ "CI_SigId" SG_ 2561133898 BenefitInertia 50252;
BA_ "CI_SigId" SG_ 2561133898 TrendInertia 50251;
BA_ "CI_SigId" SG_ 2561133898 ValidInertia 50250;
BA_ "GenSigStartValue" SG_ 2561133898 ValidInertia 3;
BA_ "CI_SigId" SG_ 2561133898 ScoreInertia 50249;
BA_ "CI_SigId" SG_ 2561127498 AvgAccelerator 50258;
BA_ "CI_SigId" SG_ 2561127498 DurationAcceleration 50257;
BA_ "CI_SigId" SG_ 2561127498 LastManeuverScoreAcceleration 50256;
BA_ "CI_SigId" SG_ 2561127498 ManeuverCountAcceleration 50255;
BA_ "CI_SigId" SG_ 2561127498 EventAcceleration 50254;
BA_ "CI_SigId" SG_ 2561127242 WeightAcceleration 50263;
BA_ "CI_SigId" SG_ 2561127242 BenefitAcceleration 50262;
BA_ "CI_SigId" SG_ 2561127242 TrendAcceleration 50261;
BA_ "CI_SigId" SG_ 2561127242 ValidAcceleration 50260;
BA_ "GenSigStartValue" SG_ 2561127242 ValidAcceleration 3;
BA_ "CI_SigId" SG_ 2561127242 ScoreAcceleration 50259;
BA_ "CI_SigId" SG_ 2566894154 GetChargedTime 50269;
BA_ "CI_SigId" SG_ 2566896970 IdCrashDevice4 50277;
BA_ "CI_SigName" SG_ 2566896970 IdCrashDevice4 "IdCrashDevice2";
BA_ "GenSigSendType" SG_ 2566896970 IdCrashDevice4 0;
BA_ "CI_SigId" SG_ 2566896970 IdCrashDevice3 50276;
BA_ "CI_SigName" SG_ 2566896970 IdCrashDevice3 "IdCrashDevice2";
BA_ "GenSigSendType" SG_ 2566896970 IdCrashDevice3 0;
BA_ "CI_ParId" SG_ 2566893898 CrashEventType "917";
BA_ "CI_SigId" SG_ 2566893898 CrashEventType 50278;
BA_ "CI_SigName" SG_ 2566893898 CrashEventType "Total Vehicle Distance (High Resolution)";
BA_ "GenSigTimeoutTime_PCM" SG_ 2566893898 CrashEventType 5000;
BA_ "SPN" SG_ 2566893898 CrashEventType 917;
BA_ "SigType" SG_ 2566893898 CrashEventType 1;
BA_ "CI_SigId" SG_ 2566895434 IdCrashDevice2 50280;
BA_ "CI_SigName" SG_ 2566895434 IdCrashDevice2 "IdCrashDevice2";
BA_ "GenSigSendType" SG_ 2566895434 IdCrashDevice2 0;
BA_ "CI_ParId" SG_ 2566895434 IdCrashDevice "917";
BA_ "CI_SigId" SG_ 2566895434 IdCrashDevice 50279;
BA_ "CI_SigName" SG_ 2566895434 IdCrashDevice "IdCrashDevice";
BA_ "GenSigTimeoutTime_PCM" SG_ 2566895434 IdCrashDevice 5000;
BA_ "SPN" SG_ 2566895434 IdCrashDevice 917;
BA_ "SigType" SG_ 2566895434 IdCrashDevice 1;
BA_ "CI_ParId" SG_ 2566845491 TirePrsThrsDetAx1InnLe "2587";
BA_ "CI_SigId" SG_ 2566845491 TirePrsThrsDetAx1InnLe 50317;
BA_ "CI_SigName" SG_ 2566845491 TirePrsThrsDetAx1InnLe "Tire Pressure Threshold Detection";
BA_ "GenSigTimeoutTime_PCM" SG_ 2566845491 TirePrsThrsDetAx1InnLe 2500;
BA_ "SPN" SG_ 2566845491 TirePrsThrsDetAx1InnLe 2587;
BA_ "CI_ParId" SG_ 2566845491 TirePrsThrsDetAx1InnRi "2587";
BA_ "CI_SigId" SG_ 2566845491 TirePrsThrsDetAx1InnRi 50318;
BA_ "CI_SigName" SG_ 2566845491 TirePrsThrsDetAx1InnRi "Tire Pressure Threshold Detection";
BA_ "GenSigTimeoutTime_PCM" SG_ 2566845491 TirePrsThrsDetAx1InnRi 2500;
BA_ "SPN" SG_ 2566845491 TirePrsThrsDetAx1InnRi 2587;
BA_ "CI_ParId" SG_ 2566845491 TirePrsThrsDetAx1OutLe "2587";
BA_ "CI_SigId" SG_ 2566845491 TirePrsThrsDetAx1OutLe 50319;
BA_ "CI_SigName" SG_ 2566845491 TirePrsThrsDetAx1OutLe "Tire Pressure Threshold Detection";
BA_ "GenSigTimeoutTime_PCM" SG_ 2566845491 TirePrsThrsDetAx1OutLe 2500;
BA_ "SPN" SG_ 2566845491 TirePrsThrsDetAx1OutLe 2587;
BA_ "CI_ParId" SG_ 2566845491 TirePrsThrsDetAx1OutRi "2587";
BA_ "CI_SigId" SG_ 2566845491 TirePrsThrsDetAx1OutRi 50320;
BA_ "CI_SigName" SG_ 2566845491 TirePrsThrsDetAx1OutRi "Tire Pressure Threshold Detection";
BA_ "GenSigTimeoutTime_PCM" SG_ 2566845491 TirePrsThrsDetAx1OutRi 2500;
BA_ "SPN" SG_ 2566845491 TirePrsThrsDetAx1OutRi 2587;
BA_ "CI_ParId" SG_ 2566845491 TirePrsThrsDetAx2InnLe "2587";
BA_ "CI_SigId" SG_ 2566845491 TirePrsThrsDetAx2InnLe 50321;
BA_ "CI_SigName" SG_ 2566845491 TirePrsThrsDetAx2InnLe "Tire Pressure Threshold Detection";
BA_ "GenSigTimeoutTime_PCM" SG_ 2566845491 TirePrsThrsDetAx2InnLe 2500;
BA_ "SPN" SG_ 2566845491 TirePrsThrsDetAx2InnLe 2587;
BA_ "CI_ParId" SG_ 2566845491 TirePrsThrsDetAx2InnRi "2587";
BA_ "CI_SigId" SG_ 2566845491 TirePrsThrsDetAx2InnRi 50322;
BA_ "CI_SigName" SG_ 2566845491 TirePrsThrsDetAx2InnRi "Tire Pressure Threshold Detection";
BA_ "GenSigTimeoutTime_PCM" SG_ 2566845491 TirePrsThrsDetAx2InnRi 2500;
BA_ "SPN" SG_ 2566845491 TirePrsThrsDetAx2InnRi 2587;
BA_ "CI_ParId" SG_ 2566845491 TirePrsThrsDetAx2OutLe "2587";
BA_ "CI_SigId" SG_ 2566845491 TirePrsThrsDetAx2OutLe 50323;
BA_ "CI_SigName" SG_ 2566845491 TirePrsThrsDetAx2OutLe "Tire Pressure Threshold Detection";
BA_ "GenSigTimeoutTime_PCM" SG_ 2566845491 TirePrsThrsDetAx2OutLe 2500;
BA_ "SPN" SG_ 2566845491 TirePrsThrsDetAx2OutLe 2587;
BA_ "CI_ParId" SG_ 2566845491 TirePrsThrsDetAx2OutRi "2587";
BA_ "CI_SigId" SG_ 2566845491 TirePrsThrsDetAx2OutRi 50324;
BA_ "CI_SigName" SG_ 2566845491 TirePrsThrsDetAx2OutRi "Tire Pressure Threshold Detection";
BA_ "GenSigTimeoutTime_PCM" SG_ 2566845491 TirePrsThrsDetAx2OutRi 2500;
BA_ "SPN" SG_ 2566845491 TirePrsThrsDetAx2OutRi 2587;
BA_ "CI_ParId" SG_ 2566845491 TirePrsThrsDetAx3InnLe "2587";
BA_ "CI_SigId" SG_ 2566845491 TirePrsThrsDetAx3InnLe 50325;
BA_ "CI_SigName" SG_ 2566845491 TirePrsThrsDetAx3InnLe "Tire Pressure Threshold Detection";
BA_ "GenSigTimeoutTime_PCM" SG_ 2566845491 TirePrsThrsDetAx3InnLe 2500;
BA_ "SPN" SG_ 2566845491 TirePrsThrsDetAx3InnLe 2587;
BA_ "CI_ParId" SG_ 2566845491 TirePrsThrsDetAx3InnRi "2587";
BA_ "CI_SigId" SG_ 2566845491 TirePrsThrsDetAx3InnRi 50326;
BA_ "CI_SigName" SG_ 2566845491 TirePrsThrsDetAx3InnRi "Tire Pressure Threshold Detection";
BA_ "GenSigTimeoutTime_PCM" SG_ 2566845491 TirePrsThrsDetAx3InnRi 2500;
BA_ "SPN" SG_ 2566845491 TirePrsThrsDetAx3InnRi 2587;
BA_ "CI_ParId" SG_ 2566845491 TirePrsThrsDetAx3OutLe "2587";
BA_ "CI_SigId" SG_ 2566845491 TirePrsThrsDetAx3OutLe 50327;
BA_ "CI_SigName" SG_ 2566845491 TirePrsThrsDetAx3OutLe "Tire Pressure Threshold Detection";
BA_ "GenSigTimeoutTime_PCM" SG_ 2566845491 TirePrsThrsDetAx3OutLe 2500;
BA_ "SPN" SG_ 2566845491 TirePrsThrsDetAx3OutLe 2587;
BA_ "CI_ParId" SG_ 2566845491 TirePrsThrsDetAx3OutRi "2587";
BA_ "CI_SigId" SG_ 2566845491 TirePrsThrsDetAx3OutRi 50328;
BA_ "CI_SigName" SG_ 2566845491 TirePrsThrsDetAx3OutRi "Tire Pressure Threshold Detection";
BA_ "GenSigTimeoutTime_PCM" SG_ 2566845491 TirePrsThrsDetAx3OutRi 2500;
BA_ "SPN" SG_ 2566845491 TirePrsThrsDetAx3OutRi 2587;
BA_ "CI_ParId" SG_ 2566845491 TirePrsThrsDetAx4InnLe "2587";
BA_ "CI_SigId" SG_ 2566845491 TirePrsThrsDetAx4InnLe 50329;
BA_ "CI_SigName" SG_ 2566845491 TirePrsThrsDetAx4InnLe "Tire Pressure Threshold Detection";
BA_ "GenSigTimeoutTime_PCM" SG_ 2566845491 TirePrsThrsDetAx4InnLe 2500;
BA_ "SPN" SG_ 2566845491 TirePrsThrsDetAx4InnLe 2587;
BA_ "CI_ParId" SG_ 2566845491 TirePrsThrsDetAx4InnRi "2587";
BA_ "CI_SigId" SG_ 2566845491 TirePrsThrsDetAx4InnRi 50330;
BA_ "CI_SigName" SG_ 2566845491 TirePrsThrsDetAx4InnRi "Tire Pressure Threshold Detection";
BA_ "GenSigTimeoutTime_PCM" SG_ 2566845491 TirePrsThrsDetAx4InnRi 2500;
BA_ "SPN" SG_ 2566845491 TirePrsThrsDetAx4InnRi 2587;
BA_ "CI_ParId" SG_ 2566845491 TirePrsThrsDetAx4OutLe "2587";
BA_ "CI_SigId" SG_ 2566845491 TirePrsThrsDetAx4OutLe 50331;
BA_ "CI_SigName" SG_ 2566845491 TirePrsThrsDetAx4OutLe "Tire Pressure Threshold Detection";
BA_ "GenSigTimeoutTime_PCM" SG_ 2566845491 TirePrsThrsDetAx4OutLe 2500;
BA_ "SPN" SG_ 2566845491 TirePrsThrsDetAx4OutLe 2587;
BA_ "CI_ParId" SG_ 2566845491 TirePrsThrsDetAx4OutRi "2587";
BA_ "CI_SigId" SG_ 2566845491 TirePrsThrsDetAx4OutRi 50332;
BA_ "CI_SigName" SG_ 2566845491 TirePrsThrsDetAx4OutRi "Tire Pressure Threshold Detection";
BA_ "GenSigTimeoutTime_PCM" SG_ 2566845491 TirePrsThrsDetAx4OutRi 2500;
BA_ "SPN" SG_ 2566845491 TirePrsThrsDetAx4OutRi 2587;
BA_ "CI_ParId" SG_ 2566845491 ExTirePrsSupp "6900";
BA_ "CI_SigId" SG_ 2566845491 ExTirePrsSupp 50316;
BA_ "CI_SigName" SG_ 2566845491 ExTirePrsSupp "Extended Tire Pressure Support";
BA_ "GenSigTimeoutTime_PCM" SG_ 2566845491 ExTirePrsSupp 2500;
BA_ "SPN" SG_ 2566845491 ExTirePrsSupp 6990;
BA_ "SigType" SG_ 2566845491 ExTirePrsSupp 4;
BA_ "CI_ParId" SG_ 2566845491 TireSensElFault "1697";
BA_ "CI_SigId" SG_ 2566845491 TireSensElFault 50315;
BA_ "CI_SigName" SG_ 2566845491 TireSensElFault "Tire Sensor Electrical Fault";
BA_ "GenSigTimeoutTime_PCM" SG_ 2566845491 TireSensElFault 2500;
BA_ "SPN" SG_ 2566845491 TireSensElFault 1697;
BA_ "SigType" SG_ 2566845491 TireSensElFault 4;
BA_ "CI_ParId" SG_ 2566845491 TireSensEnaSts "1699";
BA_ "CI_SigId" SG_ 2566845491 TireSensEnaSts 50314;
BA_ "CI_SigName" SG_ 2566845491 TireSensEnaSts "Tire Sensor Enable Status";
BA_ "GenSigTimeoutTime_PCM" SG_ 2566845491 TireSensEnaSts 2500;
BA_ "SPN" SG_ 2566845491 TireSensEnaSts 1699;
BA_ "SigType" SG_ 2566845491 TireSensEnaSts 4;
BA_ "CI_ParId" SG_ 2566845491 TireTempAx1InnLe "242";
BA_ "CI_SigId" SG_ 2566845491 TireTempAx1InnLe 50298;
BA_ "CI_SigName" SG_ 2566845491 TireTempAx1InnLe "Tire Temperature";
BA_ "GenSigTimeoutTime_PCM" SG_ 2566845491 TireTempAx1InnLe 2500;
BA_ "SPN" SG_ 2566845491 TireTempAx1InnLe 242;
BA_ "SigType" SG_ 2566845491 TireTempAx1InnLe 1;
BA_ "CI_ParId" SG_ 2566845491 TireTempAx1InnRi "242";
BA_ "CI_SigId" SG_ 2566845491 TireTempAx1InnRi 50299;
BA_ "CI_SigName" SG_ 2566845491 TireTempAx1InnRi "Tire Temperature";
BA_ "GenSigTimeoutTime_PCM" SG_ 2566845491 TireTempAx1InnRi 2500;
BA_ "SPN" SG_ 2566845491 TireTempAx1InnRi 242;
BA_ "SigType" SG_ 2566845491 TireTempAx1InnRi 1;
BA_ "CI_ParId" SG_ 2566845491 TireTempAx1OutLe "242";
BA_ "CI_SigId" SG_ 2566845491 TireTempAx1OutLe 50300;
BA_ "CI_SigName" SG_ 2566845491 TireTempAx1OutLe "Tire Temperature";
BA_ "GenSigTimeoutTime_PCM" SG_ 2566845491 TireTempAx1OutLe 2500;
BA_ "SPN" SG_ 2566845491 TireTempAx1OutLe 242;
BA_ "SigType" SG_ 2566845491 TireTempAx1OutLe 1;
BA_ "CI_ParId" SG_ 2566845491 TireTempAx1OutRi "242";
BA_ "CI_SigId" SG_ 2566845491 TireTempAx1OutRi 50301;
BA_ "CI_SigName" SG_ 2566845491 TireTempAx1OutRi "Tire Temperature";
BA_ "GenSigTimeoutTime_PCM" SG_ 2566845491 TireTempAx1OutRi 2500;
BA_ "SPN" SG_ 2566845491 TireTempAx1OutRi 242;
BA_ "SigType" SG_ 2566845491 TireTempAx1OutRi 1;
BA_ "CI_ParId" SG_ 2566845491 TireTempAx2InnLe "242";
BA_ "CI_SigId" SG_ 2566845491 TireTempAx2InnLe 50302;
BA_ "CI_SigName" SG_ 2566845491 TireTempAx2InnLe "Tire Temperature";
BA_ "GenSigTimeoutTime_PCM" SG_ 2566845491 TireTempAx2InnLe 2500;
BA_ "SPN" SG_ 2566845491 TireTempAx2InnLe 242;
BA_ "SigType" SG_ 2566845491 TireTempAx2InnLe 1;
BA_ "CI_ParId" SG_ 2566845491 TireTempAx2InnRi "242";
BA_ "CI_SigId" SG_ 2566845491 TireTempAx2InnRi 50303;
BA_ "CI_SigName" SG_ 2566845491 TireTempAx2InnRi "Tire Temperature";
BA_ "GenSigTimeoutTime_PCM" SG_ 2566845491 TireTempAx2InnRi 2500;
BA_ "SPN" SG_ 2566845491 TireTempAx2InnRi 242;
BA_ "SigType" SG_ 2566845491 TireTempAx2InnRi 1;
BA_ "CI_ParId" SG_ 2566845491 TireTempAx2OutLe "242";
BA_ "CI_SigId" SG_ 2566845491 TireTempAx2OutLe 50304;
BA_ "CI_SigName" SG_ 2566845491 TireTempAx2OutLe "Tire Temperature";
BA_ "GenSigTimeoutTime_PCM" SG_ 2566845491 TireTempAx2OutLe 2500;
BA_ "SPN" SG_ 2566845491 TireTempAx2OutLe 242;
BA_ "SigType" SG_ 2566845491 TireTempAx2OutLe 1;
BA_ "CI_ParId" SG_ 2566845491 TireTempAx2OutRi "242";
BA_ "CI_SigId" SG_ 2566845491 TireTempAx2OutRi 50305;
BA_ "CI_SigName" SG_ 2566845491 TireTempAx2OutRi "Tire Temperature";
BA_ "GenSigTimeoutTime_PCM" SG_ 2566845491 TireTempAx2OutRi 2500;
BA_ "SPN" SG_ 2566845491 TireTempAx2OutRi 242;
BA_ "SigType" SG_ 2566845491 TireTempAx2OutRi 1;
BA_ "CI_ParId" SG_ 2566845491 TireTempAx3InnLe "242";
BA_ "CI_SigId" SG_ 2566845491 TireTempAx3InnLe 50306;
BA_ "CI_SigName" SG_ 2566845491 TireTempAx3InnLe "Tire Temperature";
BA_ "GenSigTimeoutTime_PCM" SG_ 2566845491 TireTempAx3InnLe 2500;
BA_ "SPN" SG_ 2566845491 TireTempAx3InnLe 242;
BA_ "SigType" SG_ 2566845491 TireTempAx3InnLe 1;
BA_ "CI_ParId" SG_ 2566845491 TireTempAx3InnRi "242";
BA_ "CI_SigId" SG_ 2566845491 TireTempAx3InnRi 50307;
BA_ "CI_SigName" SG_ 2566845491 TireTempAx3InnRi "Tire Temperature";
BA_ "GenSigTimeoutTime_PCM" SG_ 2566845491 TireTempAx3InnRi 2500;
BA_ "SPN" SG_ 2566845491 TireTempAx3InnRi 242;
BA_ "SigType" SG_ 2566845491 TireTempAx3InnRi 1;
BA_ "CI_ParId" SG_ 2566845491 TireTempAx3OutLe "242";
BA_ "CI_SigId" SG_ 2566845491 TireTempAx3OutLe 50308;
BA_ "CI_SigName" SG_ 2566845491 TireTempAx3OutLe "Tire Temperature";
BA_ "GenSigTimeoutTime_PCM" SG_ 2566845491 TireTempAx3OutLe 2500;
BA_ "SPN" SG_ 2566845491 TireTempAx3OutLe 242;
BA_ "SigType" SG_ 2566845491 TireTempAx3OutLe 1;
BA_ "CI_ParId" SG_ 2566845491 TireTempAx3OutRi "242";
BA_ "CI_SigId" SG_ 2566845491 TireTempAx3OutRi 50309;
BA_ "CI_SigName" SG_ 2566845491 TireTempAx3OutRi "Tire Temperature";
BA_ "GenSigTimeoutTime_PCM" SG_ 2566845491 TireTempAx3OutRi 2500;
BA_ "SPN" SG_ 2566845491 TireTempAx3OutRi 242;
BA_ "SigType" SG_ 2566845491 TireTempAx3OutRi 1;
BA_ "CI_ParId" SG_ 2566845491 TireTempAx4InnLe "242";
BA_ "CI_SigId" SG_ 2566845491 TireTempAx4InnLe 50310;
BA_ "CI_SigName" SG_ 2566845491 TireTempAx4InnLe "Tire Temperature";
BA_ "GenSigTimeoutTime_PCM" SG_ 2566845491 TireTempAx4InnLe 2500;
BA_ "SPN" SG_ 2566845491 TireTempAx4InnLe 242;
BA_ "SigType" SG_ 2566845491 TireTempAx4InnLe 1;
BA_ "CI_ParId" SG_ 2566845491 TireTempAx4InnRi "242";
BA_ "CI_SigId" SG_ 2566845491 TireTempAx4InnRi 50311;
BA_ "CI_SigName" SG_ 2566845491 TireTempAx4InnRi "Tire Temperature";
BA_ "GenSigTimeoutTime_PCM" SG_ 2566845491 TireTempAx4InnRi 2500;
BA_ "SPN" SG_ 2566845491 TireTempAx4InnRi 242;
BA_ "SigType" SG_ 2566845491 TireTempAx4InnRi 1;
BA_ "CI_ParId" SG_ 2566845491 TireTempAx4OutLe "242";
BA_ "CI_SigId" SG_ 2566845491 TireTempAx4OutLe 50312;
BA_ "CI_SigName" SG_ 2566845491 TireTempAx4OutLe "Tire Temperature";
BA_ "GenSigTimeoutTime_PCM" SG_ 2566845491 TireTempAx4OutLe 2500;
BA_ "SPN" SG_ 2566845491 TireTempAx4OutLe 242;
BA_ "SigType" SG_ 2566845491 TireTempAx4OutLe 1;
BA_ "CI_ParId" SG_ 2566845491 TireTempAx4OutRi "242";
BA_ "CI_SigId" SG_ 2566845491 TireTempAx4OutRi 50313;
BA_ "CI_SigName" SG_ 2566845491 TireTempAx4OutRi "Tire Temperature";
BA_ "GenSigTimeoutTime_PCM" SG_ 2566845491 TireTempAx4OutRi 2500;
BA_ "SPN" SG_ 2566845491 TireTempAx4OutRi 242;
BA_ "SigType" SG_ 2566845491 TireTempAx4OutRi 1;
BA_ "CI_ParId" SG_ 2566845491 TirePrsAx1OutRi "241";
BA_ "CI_SigId" SG_ 2566845491 TirePrsAx1OutRi 50282;
BA_ "CI_SigName" SG_ 2566845491 TirePrsAx1OutRi "Tire Pressure";
BA_ "GenSigTimeoutTime_PCM" SG_ 2566845491 TirePrsAx1OutRi 2500;
BA_ "SPN" SG_ 2566845491 TirePrsAx1OutRi 241;
BA_ "SigType" SG_ 2566845491 TirePrsAx1OutRi 1;
BA_ "CI_ParId" SG_ 2566845491 TirePrsAx1InnLe "241";
BA_ "CI_SigId" SG_ 2566845491 TirePrsAx1InnLe 50283;
BA_ "CI_SigName" SG_ 2566845491 TirePrsAx1InnLe "Tire Pressure";
BA_ "GenSigTimeoutTime_PCM" SG_ 2566845491 TirePrsAx1InnLe 2500;
BA_ "SPN" SG_ 2566845491 TirePrsAx1InnLe 241;
BA_ "SigType" SG_ 2566845491 TirePrsAx1InnLe 1;
BA_ "CI_ParId" SG_ 2566845491 TirePrsAx1InnRi "241";
BA_ "CI_SigId" SG_ 2566845491 TirePrsAx1InnRi 50284;
BA_ "CI_SigName" SG_ 2566845491 TirePrsAx1InnRi "Tire Pressure";
BA_ "GenSigTimeoutTime_PCM" SG_ 2566845491 TirePrsAx1InnRi 2500;
BA_ "SPN" SG_ 2566845491 TirePrsAx1InnRi 241;
BA_ "SigType" SG_ 2566845491 TirePrsAx1InnRi 1;
BA_ "CI_ParId" SG_ 2566845491 TirePrsAx1OutLe "241";
BA_ "CI_SigId" SG_ 2566845491 TirePrsAx1OutLe 50285;
BA_ "CI_SigName" SG_ 2566845491 TirePrsAx1OutLe "Tire Pressure";
BA_ "GenSigTimeoutTime_PCM" SG_ 2566845491 TirePrsAx1OutLe 2500;
BA_ "SPN" SG_ 2566845491 TirePrsAx1OutLe 241;
BA_ "SigType" SG_ 2566845491 TirePrsAx1OutLe 1;
BA_ "CI_ParId" SG_ 2566845491 TirePrsAx2InnLe "241";
BA_ "CI_SigId" SG_ 2566845491 TirePrsAx2InnLe 50286;
BA_ "CI_SigName" SG_ 2566845491 TirePrsAx2InnLe "Tire Pressure";
BA_ "GenSigTimeoutTime_PCM" SG_ 2566845491 TirePrsAx2InnLe 2500;
BA_ "SPN" SG_ 2566845491 TirePrsAx2InnLe 241;
BA_ "SigType" SG_ 2566845491 TirePrsAx2InnLe 1;
BA_ "CI_ParId" SG_ 2566845491 TirePrsAx2InnRi "241";
BA_ "CI_SigId" SG_ 2566845491 TirePrsAx2InnRi 50287;
BA_ "CI_SigName" SG_ 2566845491 TirePrsAx2InnRi "Tire Pressure";
BA_ "GenSigTimeoutTime_PCM" SG_ 2566845491 TirePrsAx2InnRi 2500;
BA_ "SPN" SG_ 2566845491 TirePrsAx2InnRi 241;
BA_ "SigType" SG_ 2566845491 TirePrsAx2InnRi 1;
BA_ "CI_ParId" SG_ 2566845491 TirePrsAx2OutLe "241";
BA_ "CI_SigId" SG_ 2566845491 TirePrsAx2OutLe 50288;
BA_ "CI_SigName" SG_ 2566845491 TirePrsAx2OutLe "Tire Pressure";
BA_ "GenSigTimeoutTime_PCM" SG_ 2566845491 TirePrsAx2OutLe 2500;
BA_ "SPN" SG_ 2566845491 TirePrsAx2OutLe 241;
BA_ "SigType" SG_ 2566845491 TirePrsAx2OutLe 1;
BA_ "CI_ParId" SG_ 2566845491 TirePrsAx2OutRi "241";
BA_ "CI_SigId" SG_ 2566845491 TirePrsAx2OutRi 50289;
BA_ "CI_SigName" SG_ 2566845491 TirePrsAx2OutRi "Tire Pressure";
BA_ "GenSigTimeoutTime_PCM" SG_ 2566845491 TirePrsAx2OutRi 2500;
BA_ "SPN" SG_ 2566845491 TirePrsAx2OutRi 241;
BA_ "SigType" SG_ 2566845491 TirePrsAx2OutRi 1;
BA_ "CI_ParId" SG_ 2566845491 TirePrsAx3InnLe "241";
BA_ "CI_SigId" SG_ 2566845491 TirePrsAx3InnLe 50290;
BA_ "CI_SigName" SG_ 2566845491 TirePrsAx3InnLe "Tire Pressure";
BA_ "GenSigTimeoutTime_PCM" SG_ 2566845491 TirePrsAx3InnLe 2500;
BA_ "SPN" SG_ 2566845491 TirePrsAx3InnLe 241;
BA_ "SigType" SG_ 2566845491 TirePrsAx3InnLe 1;
BA_ "CI_ParId" SG_ 2566845491 TirePrsAx3InnRi "241";
BA_ "CI_SigId" SG_ 2566845491 TirePrsAx3InnRi 50291;
BA_ "CI_SigName" SG_ 2566845491 TirePrsAx3InnRi "Tire Pressure";
BA_ "GenSigTimeoutTime_PCM" SG_ 2566845491 TirePrsAx3InnRi 2500;
BA_ "SPN" SG_ 2566845491 TirePrsAx3InnRi 241;
BA_ "SigType" SG_ 2566845491 TirePrsAx3InnRi 1;
BA_ "CI_ParId" SG_ 2566845491 TirePrsAx3OutLe "241";
BA_ "CI_SigId" SG_ 2566845491 TirePrsAx3OutLe 50292;
BA_ "CI_SigName" SG_ 2566845491 TirePrsAx3OutLe "Tire Pressure";
BA_ "GenSigTimeoutTime_PCM" SG_ 2566845491 TirePrsAx3OutLe 2500;
BA_ "SPN" SG_ 2566845491 TirePrsAx3OutLe 241;
BA_ "SigType" SG_ 2566845491 TirePrsAx3OutLe 1;
BA_ "CI_ParId" SG_ 2566845491 TirePrsAx3OutRi "241";
BA_ "CI_SigId" SG_ 2566845491 TirePrsAx3OutRi 50293;
BA_ "CI_SigName" SG_ 2566845491 TirePrsAx3OutRi "Tire Pressure";
BA_ "GenSigTimeoutTime_PCM" SG_ 2566845491 TirePrsAx3OutRi 2500;
BA_ "SPN" SG_ 2566845491 TirePrsAx3OutRi 241;
BA_ "SigType" SG_ 2566845491 TirePrsAx3OutRi 1;
BA_ "CI_ParId" SG_ 2566845491 TirePrsAx4InnLe "241";
BA_ "CI_SigId" SG_ 2566845491 TirePrsAx4InnLe 50294;
BA_ "CI_SigName" SG_ 2566845491 TirePrsAx4InnLe "Tire Pressure";
BA_ "GenSigTimeoutTime_PCM" SG_ 2566845491 TirePrsAx4InnLe 2500;
BA_ "SPN" SG_ 2566845491 TirePrsAx4InnLe 241;
BA_ "SigType" SG_ 2566845491 TirePrsAx4InnLe 1;
BA_ "CI_ParId" SG_ 2566845491 TirePrsAx4InnRi "241";
BA_ "CI_SigId" SG_ 2566845491 TirePrsAx4InnRi 50295;
BA_ "CI_SigName" SG_ 2566845491 TirePrsAx4InnRi "Tire Pressure";
BA_ "GenSigTimeoutTime_PCM" SG_ 2566845491 TirePrsAx4InnRi 2500;
BA_ "SPN" SG_ 2566845491 TirePrsAx4InnRi 241;
BA_ "SigType" SG_ 2566845491 TirePrsAx4InnRi 1;
BA_ "CI_ParId" SG_ 2566845491 TirePrsAx4OutLe "241";
BA_ "CI_SigId" SG_ 2566845491 TirePrsAx4OutLe 50296;
BA_ "CI_SigName" SG_ 2566845491 TirePrsAx4OutLe "Tire Pressure";
BA_ "GenSigTimeoutTime_PCM" SG_ 2566845491 TirePrsAx4OutLe 2500;
BA_ "SPN" SG_ 2566845491 TirePrsAx4OutLe 241;
BA_ "SigType" SG_ 2566845491 TirePrsAx4OutLe 1;
BA_ "CI_ParId" SG_ 2566845491 TirePrsAx4OutRi "241";
BA_ "CI_SigId" SG_ 2566845491 TirePrsAx4OutRi 50297;
BA_ "CI_SigName" SG_ 2566845491 TirePrsAx4OutRi "Tire Pressure";
BA_ "GenSigTimeoutTime_PCM" SG_ 2566845491 TirePrsAx4OutRi 2500;
BA_ "SPN" SG_ 2566845491 TirePrsAx4OutRi 241;
BA_ "SigType" SG_ 2566845491 TirePrsAx4OutRi 1;
BA_ "CI_ParId" SG_ 2566845491 TireLoc_FEF433 "929";
BA_ "CI_SigId" SG_ 2566845491 TireLoc_FEF433 50281;
BA_ "CI_SigName" SG_ 2566845491 TireLoc_FEF433 "Tire Location";
BA_ "GenSigTimeoutTime_PCM" SG_ 2566845491 TireLoc_FEF433 2500;
BA_ "SPN" SG_ 2566845491 TireLoc_FEF433 929;
BA_ "CI_ParId" SG_ 2565982748 SpnCm20_FECA1C "1706";
BA_ "CI_SigId" SG_ 2565982748 SpnCm20_FECA1C 50437;
BA_ "CI_SigName" SG_ 2565982748 SpnCm20_FECA1C "SPN Conversion Method 20";
BA_ "GenSigSendType" SG_ 2565982748 SpnCm20_FECA1C 3;
BA_ "GenSigTimeoutTime_PCM" SG_ 2565982748 SpnCm20_FECA1C 5000;
BA_ "SPN" SG_ 2565982748 SpnCm20_FECA1C 1706;
BA_ "CI_ParId" SG_ 2566845212 Long_FEF31C "585";
BA_ "CI_SigId" SG_ 2566845212 Long_FEF31C 50439;
BA_ "CI_SigName" SG_ 2566845212 Long_FEF31C "Longitude";
BA_ "GenSigTimeoutTime_SGW" SG_ 2566845212 Long_FEF31C 5000;
BA_ "SPN" SG_ 2566845212 Long_FEF31C 585;
BA_ "SigType" SG_ 2566845212 Long_FEF31C 1;
BA_ "CI_ParId" SG_ 2566845212 Lat_FEF31C "584";
BA_ "CI_SigId" SG_ 2566845212 Lat_FEF31C 50438;
BA_ "CI_SigName" SG_ 2566845212 Lat_FEF31C "Latitude";
BA_ "GenSigTimeoutTime_SGW" SG_ 2566845212 Lat_FEF31C 5000;
BA_ "SPN" SG_ 2566845212 Lat_FEF31C 584;
BA_ "SigType" SG_ 2566845212 Lat_FEF31C 1;
VAL_ 2251374793 TrailElConn 0 "Not Connected" 1 "Connected" 3 "Not Available" ;
VAL_ 2251374793 TurnRightLight 0 "Off" 1 "On" 2 "Error" 3 "Not Available" ;
VAL_ 2251374793 TurnLeftLight 0 "Off" 1 "On" 2 "Error" 3 "Not Available" ;
VAL_ 2251374793 StopLight 0 "Off" 1 "On" 2 "Error" 3 "Not Available" ;
VAL_ 2251374793 GenTrailFault 0 "No fault present" 1 "Fault present" ;
VAL_ 2251374793 RevGearLight 0 "Off" 1 "On" 2 "Error" 3 "Not Available" ;
VAL_ 2251374793 RearFogLight_140C9 0 "Off" 1 "On" 2 "Error" 3 "Not Available" ;
VAL_ 2251374793 PosLight 0 "Off" 1 "On" 2 "Error" 3 "Not Available" ;
VAL_ 2317131777 EngEcoMode 0 "Off" 1 "On" 2 "Inhibited" 3 "Not Available" ;
VAL_ 2317131777 EassSoCond 0 "Off" 1 "On" ;
VAL_ 2317131777 SamInfo 0 "SAM Off" 1 "Engine Off" 2 "Cranking management" 3 "Cold Engine Management" 4 "Passive Boost" 5 "Steady State" 6 "Regenerative Braking" 7 "Quick Charge" 8 "Auto Shut Off" 9 "Shut Off" 10 "SAM recovery" 11 "Battery Regeneration" 12 "SAM in failure" 13 "Constant Voltage" 14 "Logistic Mode" 15 "Not Valid" ;
VAL_ 2317131777 EassSensPossFault 0 "No fault present" 1 "Fault present" ;
VAL_ 2317131777 EcmStartRelayDiagFdbk 0 "False" 1 "True" ;
VAL_ 2317131777 BcmStartRelayDiagFdbk 0 "False" 1 "True" ;
VAL_ 2317131777 EassEngSts 0 "Engine Stop" 1 "Engine not in Stop" 2 "Engine Stall" 3 "Engine Stopping" ;
VAL_ 2317131777 EassFunctSts 0 "Off" 1 "On" 2 "Functional Disable Request" 3 "Safety Disable Request" ;
VAL_ 2317131777 GearShiftInd 0 "No suggestion" 1 "Downshift" 2 "Upshift" 3 "Not Available due to a failure" ;
VAL_ 2317131777 SuggGearGsi 0 "Not coded" 1 "1st gear" 2 "2nd gear" 3 "3rd gear" 4 "4th gear" 5 "5th gear" 6 "6th gear" 7 "7th gear" 14 "R" 15 "N" ;
VAL_ 2251374616 SensPosArea6Sts 0 "No Obstacle" 1 "Position 1" 2 "Position 2" 3 "Position 3" ;
VAL_ 2251374616 SensPosArea5Sts 0 "No Obstacle" 1 "Position 1" 2 "Position 2" 3 "Position 3" 4 "Position 4" ;
VAL_ 2251374616 SensPosArea4Sts 0 "No Obstacle" 1 "Position 1" 2 "Position 2" 3 "Position 3" ;
VAL_ 2251374616 NspBuzReqStsRhr 0 "Not Active" 1 "Active" ;
VAL_ 2251374616 NspBuzReqStsLhr 0 "Not Active" 1 "Active" ;
VAL_ 2251374616 NspFail 0 "No fault present" 1 "Front fault" 2 "Rear fault" 3 "System fault" ;
VAL_ 2251374616 NspCtrlSts 0 "System Active (Rear AND Front)" 1 "Only Front sensors are active" 2 "Only Rear sensors are active" 3 "System Not active" ;
VAL_ 2348885874 TransmMode8 0 "Disable" 1 "Enable" 2 "Reserved" 3 "Take no action" ;
VAL_ 2348885874 TransmMode7 0 "Disable" 1 "Enable" 2 "Reserved" 3 "Take no action" ;
VAL_ 2348885874 TransmMode6 0 "Disable" 1 "Enable" 2 "Reserved" 3 "Take no action" ;
VAL_ 2348885874 TransmMode5 0 "Disable" 1 "Enable" 2 "Reserved" 3 "Take no action" ;
VAL_ 2348885874 TransmShiftSelDisModeSw 0 "Off" 1 "On" 2 "Error" 3 "Not Available" ;
VAL_ 2348885874 TransmReqLaunchGear 0 "No request, use default" 1 "1st gear" 2 "2nd gear" 3 "3rd gear" 4 "4th gear" 5 "5th gear" 6 "6th gear" 7 "7th gear" 8 "8th gear" 9 "Reverse 1" 10 "Reverse 2" 11 "Reverse 3" 12 "Reverse 4" 13 "Transmission selection" 14 "Error" 15 "Not Available" ;
VAL_ 2348885874 TransmMode4 0 "Disable" 1 "Enable" 2 "Reserved" 3 "Take no action" ;
VAL_ 2348885874 TransmMode3 0 "Disable" 1 "Enable" 2 "Reserved" 3 "Take no action" ;
VAL_ 2348885874 TransmMode2 0 "Disable" 1 "Enable" 2 "Reserved" 3 "Take no action" ;
VAL_ 2348885874 TransmMode1 0 "Disable" 1 "Enable" 2 "Reserved" 3 "Take no action" ;
VAL_ 2348885874 DisengDiffLckReqCentRear 0 "Engage differential lock" 1 "Disengage differential lock" 2 "Reserved" 3 "Take no action" ;
VAL_ 2348885874 DisengDiffLckReqCentFront 0 "Engage differential lock" 1 "Disengage differential lock" 2 "Reserved" 3 "Take no action" ;
VAL_ 2348885874 DisengDiffLckReqCent 0 "Engage differential lock" 1 "Disengage differential lock" 2 "Reserved" 3 "Take no action" ;
VAL_ 2348885874 DisengDiffLckReqRa2 0 "Engage differential lock" 1 "Disengage differential lock" 2 "Reserved" 3 "Take no action" ;
VAL_ 2348885874 DisengDiffLckReqRa1 0 "Engage differential lock" 1 "Disengage differential lock" 2 "Reserved" 3 "Take no action" ;
VAL_ 2348885874 DisengDiffLckReqFa2 0 "Engage differential lock" 1 "Disengage differential lock" 2 "Reserved" 3 "Take no action" ;
VAL_ 2348885874 DisengDiffLckReqFa1 0 "Engage differential lock" 1 "Disengage differential lock" 2 "Reserved" 3 "Take no action" ;
VAL_ 2348885874 TransmReqGear 223 "Reverse Selector pos" 224 "Pos unknown and/or no btn press" 225 "Press mom. btn to resel cur pos" 226 "Betw. Reverse and Park pos" 227 "Betw. Neutral and Reverse pos" 228 "Betw. Drive and Neutral pos" 229 "Betw. D-1 and Driveshift sel pos" 230 "Betw. D-2 and D-1 pos" 231 "Betw. D-3 and D-2 pos" 232 "Betw. D-4 and D-3 pos" 233 "Betw. D-5 and D-4 pos" 234 "Betw. D-6 and D-5 pos" 235 "Betw. D-7 and D-6 pos" 236 "Betw. two fw pos." 237 "Betw. two reverse pos" 238 "Betw. two pos" 239 "D-7 7th fw pos from Drive" 240 "D-6 6th fw pos from Drive" 241 "D-5 5th fw pos from Drive" 242 "D-4 4th fw pos from Drive" 243 "D-3 3rd fw pos from Drive" 244 "D-2 2nd fw pos from Drive" 245 "D-1 1st fw pos from Drive" 246 "Downshift 2 gear" 247 "Downshift 1 gear" 248 "Upshift 2 gear" 249 "Upshift 1 gear" 250 "Fw Low pos" 251 "Park pos" 252 "Fw Drive pos" 253 "Hold current gear" 255 "No Action" ;
VAL_ 2348885874 TransmRevGearShiftInhReq 0 "Allow shifts" 1 "Inhibit shifts" 2 "Reserved" 3 "Take no action" ;
VAL_ 2348885874 DisengDrvlReq 0 "Allow driveline engagement" 1 "Disengage driveline" 2 "Reserved" 3 "Take no action" ;
VAL_ 2348885874 TransmTrqConvLckReq 0 "Allow lockup" 1 "Disable lockup" 2 "Request lockup" 3 "Take no action" ;
VAL_ 2348885874 TransmGearShiftInhReq 0 "Gear shifts allowed" 1 "Gear shifts inhibited" 2 "Reserved" 3 "Take no action" ;
VAL_ 2566750979 TcSts 0 "2 wheel high" 1 "4 wheel high" 2 "Neutral" 3 "2 wheel low" 4 "4 wheel low" 5 "Shift in Progr. / gear not conf." 6 "Error" 7 "Not Available" ;
VAL_ 2566751205 TcSts_FD83E5 0 "2 wheel high" 1 "4 wheel high" 2 "Neutral" 3 "2 wheel low" 4 "4 wheel low" 5 "Shift in Progr. / gear not conf." 6 "Error" 7 "Not Available" ;
VAL_ 2365484270 TcoPerf 0 "Normal performance" 1 "Performance analysis" 2 "Error" 3 "Not Available" ;
VAL_ 2365484270 HandInfo 0 "No handling information" 1 "Handling information" 2 "Error" 3 "Not Available" ;
VAL_ 2365484270 SysEvt 0 "No tachograph event" 1 "Tachograph event" 2 "Error" 3 "Not Available" ;
VAL_ 2365484270 DrivCardDriv2 0 "Driver card not present" 1 "Driver card present" 2 "Error" 3 "Not Available" ;
VAL_ 2365484270 Driv2TimeRelSts 0 "Normal, No limits reached" 1 "Limit 1, 15 min before 4 �h" 2 "Limit 2, 4 �h reached" 3 "Limit 3, 15min before 9h" 4 "Limit 4, 9h reached" 5 "Limit 5, 15min before 16h" 6 "Limit 6, 16h reached" 13 "Other" 14 "Error" 15 "Not Available" ;
VAL_ 2365484270 VehOverspeed 0 "No overspeed" 1 "Overspeed" 2 "Error" 3 "Not Available" ;
VAL_ 2365484270 DrivCardDriv1 0 "Driver card not present" 1 "Driver card present" 2 "Error" 3 "Not Available" ;
VAL_ 2365484270 Driv1TimeRelSts 0 "Normal, No limits reached" 1 "Limit 1, 15 min before 4 �h" 2 "Limit 2, 4 �h reached" 3 "Limit 3, 15min before 9h" 4 "Limit 4, 9h reached" 5 "Limit 5, 15min before 16h" 6 "Limit 6, 16h reached" 13 "Other" 14 "Error" 15 "Not Available" ;
VAL_ 2365484270 VehMot 0 "Vehicle motion not detected" 1 "Vehicle motion detected" 2 "Error" 3 "Not Available" ;
VAL_ 2365484270 Driv2WorkSts 0 "Rest, sleeping" 1 "Driver available, short break" 2 "Work" 3 "Drive, Behind wheel" 4 "Reserved" 5 "Reserved" 6 "Error" 7 "Not Available" ;
VAL_ 2365484270 Driv1WorkSts 0 "Rest, sleeping" 1 "Driver available, short break" 2 "Work" 3 "Drive, Behind wheel" 4 "Reserved" 5 "Reserved" 6 "Error" 7 "Not Available" ;
VAL_ 2566842094 LocalHrOfs 249 "UTC time, Offset not known/supp." 250 "Local time" 255 "Not Available" ;
VAL_ 2566842094 LocalMinOfs 255 "Not Available" ;
VAL_ 2566842094 Yr 255 "Not Available" ;
VAL_ 2566842094 Day 255 "Not Available" ;
VAL_ 2566842094 Month 255 "Not Available" ;
VAL_ 2566842094 Hr 255 "Not Available" ;
VAL_ 2566842094 Min 255 "Not Available" ;
VAL_ 2566842094 Sec 255 "Not Available" ;
VAL_ 2566841921 LocalHrOfs_FEE641 249 "UTC time, Offset not known/supp." 250 "Local time" 255 "Not Available" ;
VAL_ 2566841921 LocalMinOfs_FEE641 255 "Not Available" ;
VAL_ 2566841921 Yr_FEE641 255 "Not Available" ;
VAL_ 2566841921 Day_FEE641 255 "Not Available" ;
VAL_ 2566841921 Month_FEE641 255 "Not Available" ;
VAL_ 2566841921 Hr_FEE641 255 "Not Available" ;
VAL_ 2566841921 Min_FEE641 255 "Not Available" ;
VAL_ 2566841921 Sec_FEE641 255 "Not Available" ;
VAL_ 2566841930 LocalHrOfs_FEE64A 249 "UTC time, Offset not known/supp." 250 "Local time" 255 "Not Available" ;
VAL_ 2566841930 LocalMinOfs_FEE64A 255 "Not Available" ;
VAL_ 2566841930 Yr_FEE64A 255 "Not Available" ;
VAL_ 2566841930 Day_FEE64A 255 "Not Available" ;
VAL_ 2566841930 Month_FEE64A 255 "Not Available" ;
VAL_ 2566841930 Hr_FEE64A 255 "Not Available" ;
VAL_ 2566841930 Min_FEE64A 255 "Not Available" ;
VAL_ 2566841930 Sec_FEE64A 255 "Not Available" ;
VAL_ 2566764851 TireLoc 0 "Axle 1, Outer left wheel" 1 "Axle 1, Inner left wheel" 2 "Axle 1, Inner right wheel" 3 "Axle 1, Outer right wheel" 16 "Axle 2, Outer left wheel" 17 "Axle 2, Inner left wheel" 18 "Axle 2, Inner right wheel" 19 "Axle 2, Outer right wheel" 32 "Axle 3, Outer left wheel" 33 "Axle 3, Inner left wheel" 34 "Axle 3, Inner right wheel" 35 "Axle 3, Outer right wheel" 48 "Axle 4, Outer left wheel" 49 "Axle 4, Inner left wheel" 50 "Axle 4, Inner right wheel" 51 "Axle 4, Outer right wheel" 255 "Not Available" ;
VAL_ 2566803211 YcBrkCtrlActv 0 "Passive but installed" 1 "Active" 2 "Reserved" 3 "Don�t Care / Take no action" ;
VAL_ 2566803211 YcEngCtrlActv 0 "Passive but installed" 1 "Active" 2 "Reserved" 3 "Don�t Care / Take no action" ;
VAL_ 2566803211 RopBrkCtrlActv 0 "Passive but installed" 1 "Active" 2 "Reserved" 3 "Don�t Care / Take no action" ;
VAL_ 2566803211 RopEngCtrlActv 0 "Passive but installed" 1 "Active" 2 "Reserved" 3 "Don�t Care / Take no action" ;
VAL_ 2566803211 VdcBrkLightReq 0 "Turn brake light not on" 1 "Turn brake light on" 2 "Reserved" 3 "Don�t Care / Take no action" ;
VAL_ 2566803211 VdcFullyOp 0 "Not fully operational" 1 "Fully operational" 2 "Reserved" 3 "Don�t Care / Take no action" ;
VAL_ 2566803211 VdcInfoSig 0 "Off" 1 "On" 2 "Reserved" 3 "Don�t Care / Take no action" ;
VAL_ 2561142090 Driver_Stop 0 "NoEvent" 1 "Driver Stop Event" 2 "Not Available" ;
VAL_ 2561141066 EventValid 0 "False" 1 "True" 2 "Reserved" 3 "NotAvailable" ;
VAL_ 2561140554 EventDas 0 "NoEvent" 1 "DasWarning" 2 "DasStop" ;
VAL_ 2561130314 BenefitDas 0 "False" 1 "True" 2 "Reserved" 3 "NotAvailable" ;
VAL_ 2561130314 ValidDas 0 "False" 1 "True" 2 "Reserved" 3 "NotAvailable" ;
VAL_ 2561132874 EventHarshBraking 0 "NoEvent" 1 "HarshBrakingDetected" ;
VAL_ 2561132618 BenefitHarshBraking 0 "False" 1 "True" 2 "Reserved" 3 "NotAvailable" ;
VAL_ 2561132618 ValidHarshBraking 0 "False" 1 "True" 2 "Reserved" 3 "NotAvailable" ;
VAL_ 2561139786 EventTireSaving 0 "NoEvent" 1 "WastefulTirePressure" ;
VAL_ 2561139530 BenefitTire 0 "False" 1 "True" 2 "Reserved" 3 "NotAvailable" ;
VAL_ 2561139530 ValidTire 0 "False" 1 "True" 2 "Reserved" 3 "NotAvailable" ;
VAL_ 2561139274 PanicBrakeState 0 "PanicBrakeAllowed" 1 "PanicBrakeNotAllowed" 2 "PanicBrakeDetected" ;
VAL_ 2561139274 EventStop 0 "NoEvent" 1 "GoodStop" 2 "BadStop" 3 "PanicStop" ;
VAL_ 2561139018 BenefitStop 0 "False" 1 "True" 2 "Reserved" 3 "NotAvailable" ;
VAL_ 2561139018 ValidStop 0 "False" 1 "True" 2 "Reserved" 3 "NotAvailable" ;
VAL_ 2561138762 EventStabilityControl 0 "NoEvent" 1 "UnsafeDrivingDetected" ;
VAL_ 2561138506 BenefitStabilityControl 0 "False" 1 "True" 2 "Reserved" 3 "NotAvailable" ;
VAL_ 2561138506 ValidStabilityControl 0 "False" 1 "True" 2 "Reserved" 3 "NotAvailable" ;
VAL_ 2561138250 TripEndReason 0 "NotEnded" 1 "KeyOff" 2 "DriverIdChanged" 3 "UserReset" 4 "TelematicAppReset" ;
VAL_ 2561138250 TripActive 0 "False" 1 "True" 2 "Reserved" 3 "NotAvailable" ;
VAL_ 2561138250 TripEnded_A7DE4A 0 "False" 1 "True" 2 "Reserved" 3 "NotAvailable" ;
VAL_ 2561138250 TripStarted_A7DE4A 0 "False" 1 "True" 2 "Reserved" 3 "NotAvailable" ;
VAL_ 2561137738 EventTireSafety 0 "NoEvent" 1 "UnsafeTirePressure" ;
VAL_ 2561137482 BenefitTireSafety 0 "False" 1 "True" 2 "Reserved" 3 "NotAvailable" ;
VAL_ 2561137482 ValidTireSafety 0 "False" 1 "True" 2 "Reserved" 3 "NotAvailable" ;
VAL_ 2561137226 BenefiSafety 0 "False" 1 "True" 2 "Reserved" 3 "NotAvailable" ;
VAL_ 2561137226 ValidSafety 0 "False" 1 "True" 2 "Reserved" 3 "NotAvailable" ;
VAL_ 2561136970 TorqueLevel 0 "Low" 1 "High" ;
VAL_ 2561136970 RPMZone 0 "Low" 1 "Middle" 2 "High" ;
VAL_ 2561136970 RPMLevel 0 "Low" 1 "Middle" 2 "High" ;
VAL_ 2561136970 EventRPM 0 "NoEvent" 1 "GoodRPMStyle" 2 "BadRPMStyleHigh" 3 "BadRPMStyleLow" 4 "BadRPMGsiFault" ;
VAL_ 2561136714 BenefitRpm 0 "False" 1 "True" 2 "Reserved" 3 "NotAvailable" ;
VAL_ 2561136714 ValidRpm 0 "False" 1 "True" 2 "Reserved" 3 "NotAvailable" ;
VAL_ 2561136458 EventRadar 0 "NoEvent" 1 "UnsafeDistanceDetected" ;
VAL_ 2561136202 BenefitRadar 0 "False" 1 "True" 2 "Reserved" 3 "NotAvailable" ;
VAL_ 2561136202 ValidRadar 0 "False" 1 "True" 2 "Reserved" 3 "NotAvailable" ;
VAL_ 2561135946 EventPecc 0 "NoEvent" 1 "PeccEnabled" 2 "PeccDisabled" ;
VAL_ 2561135690 BenefitPecc 0 "False" 1 "True" 2 "Reserved" 3 "NotAvailable" ;
VAL_ 2561135690 ValidPecc 0 "False" 1 "True" 2 "Reserved" 3 "NotAvailable" ;
VAL_ 2561134922 EventLaneDpt 0 "NoEvent" 1 "LaneDepartureEnabled" 2 "LaneDepartureDisabled" 3 "LaneDepartureTriggered" ;
VAL_ 2561134666 BenefitLaneDpt 0 "False" 1 "True" 2 "Reserved" 3 "NotAvailable" ;
VAL_ 2561134666 ValidLaneDpt 0 "False" 1 "True" 2 "Reserved" 3 "NotAvailable" ;
VAL_ 2561134410 BenefitInertiaPecc 0 "False" 1 "True" 2 "Reserved" 3 "NotAvailable" ;
VAL_ 2561134410 ValidInertiaPecc 0 "False" 1 "True" 2 "Reserved" 3 "NotAvailable" ;
VAL_ 2561133386 EventHarshSteering 0 "NoEvent" 1 "HarshSteeringDetected" ;
VAL_ 2561133130 BenefitHarshSteering 0 "False" 1 "True" 2 "Reserved" 3 "NotAvailable" ;
VAL_ 2561133130 ValidHarshSteering 0 "False" 1 "True" 2 "Reserved" 3 "NotAvailable" ;
VAL_ 2561132362 EventHandBrake 0 "NoEvent" 1 "BadHandBrake" ;
VAL_ 2561132106 BenefitHandBrake 0 "False" 1 "True" 2 "Reserved" 3 "NotAvailable" ;
VAL_ 2561132106 ValidHandBrake 0 "False" 1 "True" 2 "Reserved" 3 "NotAvailable" ;
VAL_ 2561131594 BenefitFuel 0 "False" 1 "True" 2 "Reserved" 3 "NotAvailable" ;
VAL_ 2561131594 ValidFuel 0 "False" 1 "True" 2 "Reserved" 3 "NotAvailable" ;
VAL_ 2561131338 BenefitEngineUse 0 "False" 1 "True" 2 "Reserved" 3 "NotAvailable" ;
VAL_ 2561131338 ValidEngineUse 0 "False" 1 "True" 2 "Reserved" 3 "NotAvailable" ;
VAL_ 2561130826 BenefitEcoMode 0 "False" 1 "True" 2 "Reserved" 3 "NotAvailable" ;
VAL_ 2561130826 ValidEcoMode 0 "False" 1 "True" 2 "Reserved" 3 "NotAvailable" ;
VAL_ 2561130570 BenefitDeceleration 0 "False" 1 "True" 2 "Reserved" 3 "NotAvailable" ;
VAL_ 2561130570 ValidDeceleration 0 "False" 1 "True" 2 "Reserved" 3 "NotAvailable" ;
VAL_ 2561129290 BenefitCare 0 "False" 1 "True" 2 "Reserved" 3 "NotAvailable" ;
VAL_ 2561129290 ValidCare 0 "False" 1 "True" 2 "Reserved" 3 "NotAvailable" ;
VAL_ 2561129034 EventAuxBrake 0 "NoEvent" 1 "GoodAuxBrake" 2 "BadAuxBrake" ;
VAL_ 2561128778 BenefitAuxBrake 0 "False" 1 "True" 2 "Reserved" 3 "NotAvailable" ;
VAL_ 2561128778 ValidAuxBrake 0 "False" 1 "True" 2 "Reserved" 3 "NotAvailable" ;
VAL_ 2561128266 BenefitAirC 0 "False" 1 "True" 2 "Reserved" 3 "NotAvailable" ;
VAL_ 2561128266 ValidAirC 0 "False" 1 "True" 2 "Reserved" 3 "NotAvailable" ;
VAL_ 2561128010 EventAebs 0 "NoEvent" 1 "AebsEnabled" 2 "AebsDisabled" 3 "AebsTriggered" ;
VAL_ 2561126986 EventAcc 0 "NoEvent" 1 "AccEnabled" 2 "AccDisabled" 3 "AccTriggered" ;
VAL_ 2561127754 BenefitAebs 0 "False" 1 "True" 2 "Reserved" 3 "NotAvailable" ;
VAL_ 2561127754 ValidAebs 0 "False" 1 "True" 2 "Reserved" 3 "NotAvailable" ;
VAL_ 2561126730 BenefitAcc 0 "False" 1 "True" 2 "Reserved" 3 "NotAvailable" ;
VAL_ 2561126730 ValidAcc 0 "False" 1 "True" 2 "Reserved" 3 "NotAvailable" ;
VAL_ 2561129546 ResetEcoB 0 "False" 1 "True" 2 "Reserved" 3 "NotAvailable" ;
VAL_ 2561129546 ResetEcoA 0 "False" 1 "True" 2 "Reserved" 3 "NotAvailable" ;
VAL_ 2561135434 OldDasEnabled 0 "False" 1 "True" 2 "Reserved" 3 "NotAvailable" ;
VAL_ 2561135434 OldDasWarning 0 "False" 1 "True" 2 "Reserved" 3 "NotAvailable" ;
VAL_ 2561135434 OldDasStop 0 "False" 1 "True" 2 "Reserved" 3 "NotAvailable" ;
VAL_ 2561134154 PunishingManeuverInertia 0 "False" 1 "True" 2 "Reserved" 3 "NotAvailable" ;
VAL_ 2561134154 DangerOfCollisionInertia 0 "False" 1 "True" 2 "Reserved" 3 "NotAvailable" ;
VAL_ 2561134154 EndReasonInertia 0 "NoReason" 1 "BrakeAction" 2 "GasPedalPressed" 3 "CruiseControlEnabled" 4 "NoEnded" ;
VAL_ 2561134154 StartReasonInertia 0 "NoReason" 1 "GasPedalReleased" 2 "CruiseControlDisabled" ;
VAL_ 2561134154 EventInertia 0 "NoEvent" 1 "GoodInertia" 2 "BadInertia" 3 "GoodGasGas" 4 "DangerOfCollision" 5 "PunishingManeuver" ;
VAL_ 2561133898 BenefitInertia 0 "False" 1 "True" 2 "Reserved" 3 "NotAvailable" ;
VAL_ 2561133898 ValidInertia 0 "False" 1 "True" 2 "Reserved" 3 "NotAvailable" ;
VAL_ 2561127498 EventAcceleration 0 "NoEvent" 1 "GoodAcceleration" 2 "BadAcceleration" ;
VAL_ 2561127242 BenefitAcceleration 0 "False" 1 "True" 2 "Reserved" 3 "NotAvailable" ;
VAL_ 2561127242 ValidAcceleration 0 "False" 1 "True" 2 "Reserved" 3 "NotAvailable" ;
VAL_ 2566845491 TirePrsThrsDetAx1InnLe 0 "Extreme over pressure" 1 "Over pressure" 2 "No warning pressure" 3 "Under pressure" 4 "Extreme under pressure" 5 "Not defined" 6 "Error indicator" 7 "Not Available" ;
VAL_ 2566845491 TireTempAx1InnRi 255 "Not Available" ;
VAL_ 2566845491 TireTempAx1OutLe 255 "Not Available" ;
VAL_ 2566845491 TireTempAx1OutRi 255 "Not Available" ;
VAL_ 2566845491 TireTempAx2InnLe 255 "Not Available" ;
VAL_ 2566845491 TireTempAx2InnRi 255 "Not Available" ;
VAL_ 2566845491 TireTempAx2OutLe 255 "Not Available" ;
VAL_ 2566845491 TireTempAx2OutRi 255 "Not Available" ;
VAL_ 2566845491 TireTempAx3InnLe 255 "Not Available" ;
VAL_ 2566845491 TireTempAx3InnRi 255 "Not Available" ;
VAL_ 2566845491 TireTempAx3OutLe 255 "Not Available" ;
VAL_ 2566845491 TireTempAx3OutRi 255 "Not Available" ;
VAL_ 2566845491 TireTempAx4InnLe 255 "Not Available" ;
VAL_ 2566845491 TireTempAx4InnRi 255 "Not Available" ;
VAL_ 2566845491 TireTempAx4OutLe 255 "Not Available" ;
VAL_ 2566845491 TireTempAx4OutRi 255 "Not Available" ;
VAL_ 2566845491 TirePrsAx1OutRi 255 "Not Available" ;
VAL_ 2566845491 TirePrsAx1InnLe 255 "Not Available" ;
VAL_ 2566845491 TirePrsAx1InnRi 255 "Not Available" ;
VAL_ 2566845491 TirePrsAx1OutLe 255 "Not Available" ;
VAL_ 2566845491 TirePrsAx2InnLe 255 "Not Available" ;
VAL_ 2566845491 TirePrsAx2InnRi 255 "Not Available" ;
VAL_ 2566845491 TirePrsAx2OutLe 255 "Not Available" ;
VAL_ 2566845491 TirePrsAx2OutRi 255 "Not Available" ;
VAL_ 2566845491 TirePrsAx3InnLe 255 "Not Available" ;
VAL_ 2566845491 TirePrsAx3InnRi 255 "Not Available" ;
VAL_ 2566845491 TirePrsAx3OutLe 255 "Not Available" ;
VAL_ 2566845491 TirePrsAx3OutRi 255 "Not Available" ;
VAL_ 2566845491 TirePrsAx4InnLe 255 "Not Available" ;
VAL_ 2566845491 TirePrsAx4InnRi 255 "Not Available" ;
VAL_ 2566845491 TirePrsAx4OutLe 255 "Not Available" ;
VAL_ 2566845491 TirePrsAx4OutRi 255 "Not Available" ;
VAL_ 2565982748 SpnCm20_FECA1C 0 "SPN v.4" 1 "SPN v.1,2,3" ;
SIG_VALTYPE_ 2561135434 OldDasPiswa : 1;
